VERSION "HIPBNNNYNNNNNNNNNNNNNNNNNNNNNNNNNNYYNNNNNN/4>%%%/4/'%**4NNN///"

NS_ :

BS_:

BU_: ADC BDF BDL BDR BGW CDC DDM VNC Vector_XXX

BO_ 1570 BDB1S03: 8 BDL
 SG_ RSRSENFT : 23|2@0+ (1,0) [0|0] "-"  BGW,CDC,DDM
 SG_ SULDCD : 21|2@0+ (1,0) [0|0] "-"  BGW,CDC,DDM
 SG_ PANL : 19|1@0+ (1,0) [0|0] "-"  BGW,CDC
 SG_ LED_HI_B : 17|2@0+ (1,0) [0|0] "-"  BGW,CDC,DDM
 SG_ DRL : 31|1@0+ (1,0) [0|0] "-"  BGW,CDC,DDM
 SG_ HEDH : 30|1@0+ (1,0) [0|0] "-"  BGW,CDC,DDM
 SG_ HEDL : 29|1@0+ (1,0) [0|0] "-"  BGW,CDC,DDM
 SG_ TAIL : 28|1@0+ (1,0) [0|0] "-"  BGW,CDC
 SG_ FFOG : 27|1@0+ (1,0) [0|0] "-"  BGW,CDC,DDM
 SG_ RFOG : 26|1@0+ (1,0) [0|0] "-"  BGW,CDC,DDM
 SG_ RSROFFTT : 25|2@0+ (1,0) [0|0] "-"  BGW,CDC,DDM
 SG_ SB_IND : 39|2@0+ (1,0) [0|0] "-"  BGW,CDC,DDM
 SG_ RSRMIDR3 : 33|2@0+ (1,0) [0|0] "-"  BGW,CDC,DDM
 SG_ RSRMID_R : 47|2@0+ (1,0) [0|0] "-"  BGW,CDC,DDM
 SG_ RSR_PR : 45|1@0+ (1,0) [0|0] "-"  BGW,CDC,DDM
 SG_ RSRON_ST : 44|1@0+ (1,0) [0|0] "-"  BGW,CDC,DDM
 SG_ LTOFF_AD : 54|1@0+ (1,0) [0|0] "-"  BGW,CDC,DDM
 SG_ RSRSENFC : 53|2@0+ (1,0) [0|0] "-"  BGW,CDC,DDM
 SG_ SRWARN : 51|1@0+ (1,0) [0|0] "-"  BGW,CDC,DDM
 SG_ PWWARN : 50|1@0+ (1,0) [0|0] "-"  BGW,CDC,DDM
 SG_ LTRBZ_R : 49|1@0+ (1,0) [0|0] "-"  BGW,CDC,DDM

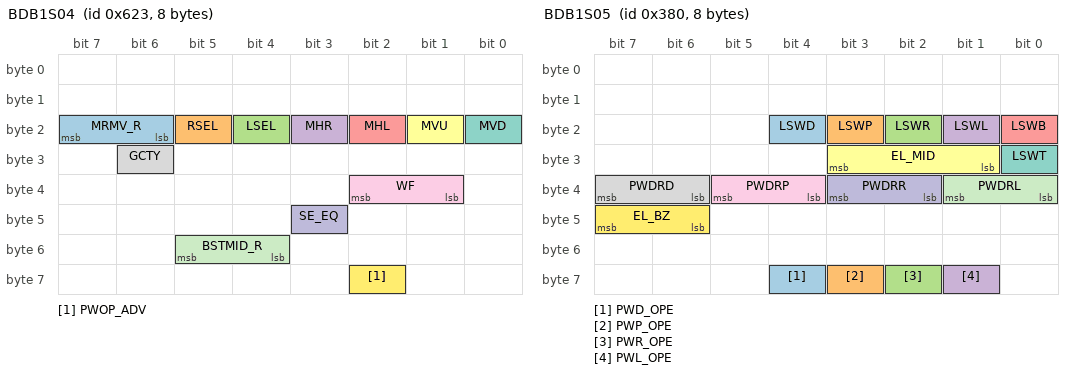
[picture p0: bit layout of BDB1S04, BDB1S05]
BO_ 1571 BDB1S04: 8 BDL
 SG_ MRMV_R : 23|2@0+ (1,0) [0|0] "-"  BGW,CDC,DDM
 SG_ RSEL : 21|1@0+ (1,0) [0|0] "-"  BGW,CDC,DDM
 SG_ LSEL : 20|1@0+ (1,0) [0|0] "-"  BGW,CDC,DDM
 SG_ MHR : 19|1@0+ (1,0) [0|0] "-"  BGW,CDC,DDM
 SG_ MHL : 18|1@0+ (1,0) [0|0] "-"  BGW,CDC,DDM
 SG_ MVU : 17|1@0+ (1,0) [0|0] "-"  BGW,CDC,DDM
 SG_ MVD : 16|1@0+ (1,0) [0|0] "-"  BGW,CDC,DDM
 SG_ GCTY : 30|1@0+ (1,0) [0|0] "-"  BGW,CDC,DDM
 SG_ WF : 34|2@0+ (1,0) [0|0] "-"  BGW,CDC,DDM
 SG_ SE_EQ : 43|1@0+ (1,0) [0|0] "-"  BGW,CDC,DDM
 SG_ BSTMID_R : 53|2@0+ (1,0) [0|0] "-"  BGW,CDC,DDM
 SG_ PWOP_ADV : 58|1@0+ (1,0) [0|0] "-"  BGW,CDC,DDM

BO_ 896 BDB1S05: 8 BDL
 SG_ LSWD : 20|1@0+ (1,0) [0|0] "-"  BGW,CDC
 SG_ LSWP : 19|1@0+ (1,0) [0|0] "-"  BGW,CDC
 SG_ LSWR : 18|1@0+ (1,0) [0|0] "-"  BGW,CDC
 SG_ LSWL : 17|1@0+ (1,0) [0|0] "-"  BGW,CDC
 SG_ LSWB : 16|1@0+ (1,0) [0|0] "-"  BGW,CDC
 SG_ EL_MID : 27|3@0+ (1,0) [0|0] "-"  BGW,CDC
 SG_ LSWT : 24|1@0+ (1,0) [0|0] "-"  BGW,CDC
 SG_ PWDRD : 39|2@0+ (1,0) [0|0] "-"  BGW,CDC
 SG_ PWDRP : 37|2@0+ (1,0) [0|0] "-"  BGW,CDC
 SG_ PWDRR : 35|2@0+ (1,0) [0|0] "-"  BGW,CDC
 SG_ PWDRL : 33|2@0+ (1,0) [0|0] "-"  BGW,CDC
 SG_ EL_BZ : 47|2@0+ (1,0) [0|0] "-"  BGW,CDC
 SG_ PWD_OPE : 60|1@0+ (1,0) [0|0] "-"  BGW,CDC
 SG_ PWP_OPE : 59|1@0+ (1,0) [0|0] "-"  BGW,CDC
 SG_ PWR_OPE : 58|1@0+ (1,0) [0|0] "-"  BGW,CDC
 SG_ PWL_OPE : 57|1@0+ (1,0) [0|0] "-"  BGW,CDC

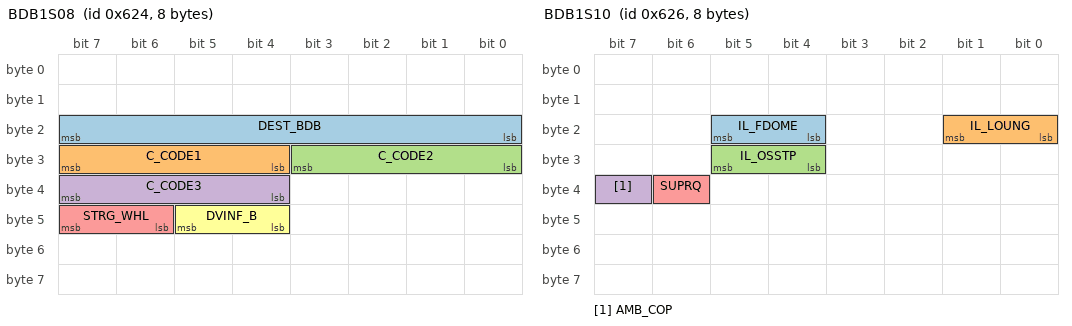
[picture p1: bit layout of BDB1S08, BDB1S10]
BO_ 1572 BDB1S08: 8 BDL
 SG_ DEST_BDB : 23|8@0+ (1,0) [0|0] "-"  BGW,CDC
 SG_ C_CODE1 : 31|4@0+ (1,0) [0|0] "-"  BGW,CDC
 SG_ C_CODE2 : 27|4@0+ (1,0) [0|0] "-"  BGW,CDC
 SG_ C_CODE3 : 39|4@0+ (1,0) [0|0] "-"  BGW,CDC
 SG_ STRG_WHL : 47|2@0+ (1,0) [0|0] "-"  BGW,CDC
 SG_ DVINF_B : 45|2@0+ (1,0) [0|0] "-"  BGW,CDC

BO_ 1574 BDB1S10: 8 BDL
 SG_ IL_FDOME : 21|2@0+ (1,0) [0|0] "-"  CDC
 SG_ IL_LOUNG : 17|2@0+ (1,0) [0|0] "-"  CDC
 SG_ IL_OSSTP : 29|2@0+ (1,0) [0|0] "-"  CDC
 SG_ AMB_COP : 39|1@0+ (1,0) [0|0] "-"  CDC
 SG_ SUPRQ : 38|1@0+ (1,0) [0|0] "-"  CDC

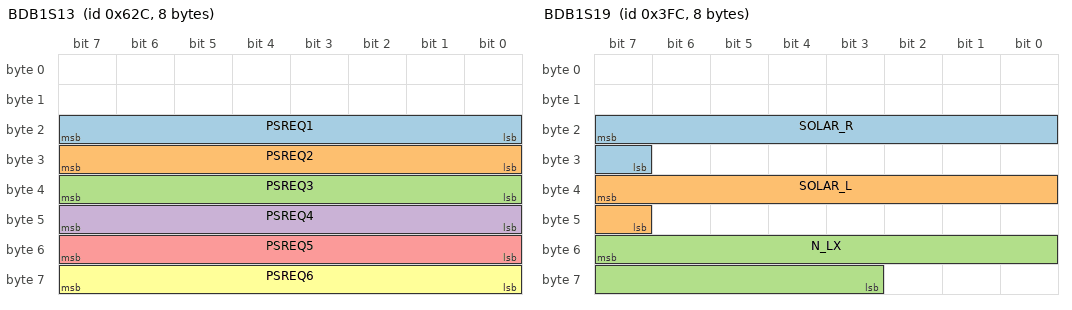
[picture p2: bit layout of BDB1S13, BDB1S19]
BO_ 1580 BDB1S13: 8 BDL
 SG_ PSREQ1 : 23|8@0+ (1,0) [0|0] "-"  CDC
 SG_ PSREQ2 : 31|8@0+ (1,0) [0|0] "-"  CDC
 SG_ PSREQ3 : 39|8@0+ (1,0) [0|0] "-"  CDC
 SG_ PSREQ4 : 47|8@0+ (1,0) [0|0] "-"  CDC
 SG_ PSREQ5 : 55|8@0+ (1,0) [0|0] "-"  CDC
 SG_ PSREQ6 : 63|8@0+ (1,0) [0|0] "-"  CDC

BO_ 1020 BDB1S19: 8 BDL
 SG_ SOLAR_R : 23|9@0+ (100,0) [0|0] "-"  BGW,CDC
 SG_ SOLAR_L : 39|9@0+ (100,0) [0|0] "-"  BGW,CDC
 SG_ N_LX : 55|13@0+ (1,0) [0|0] "-"  BGW,CDC

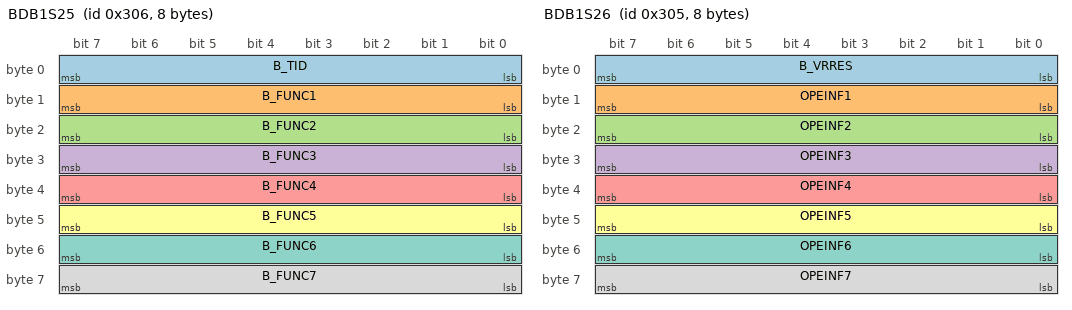
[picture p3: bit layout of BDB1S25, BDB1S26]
BO_ 774 BDB1S25: 8 BDL
 SG_ B_TID : 7|8@0+ (1,0) [0|0] "-"  CDC
 SG_ B_FUNC1 : 15|8@0+ (1,0) [0|0] "-"  CDC
 SG_ B_FUNC2 : 23|8@0+ (1,0) [0|0] "-"  CDC
 SG_ B_FUNC3 : 31|8@0+ (1,0) [0|0] "-"  CDC
 SG_ B_FUNC4 : 39|8@0+ (1,0) [0|0] "-"  CDC
 SG_ B_FUNC5 : 47|8@0+ (1,0) [0|0] "-"  CDC
 SG_ B_FUNC6 : 55|8@0+ (1,0) [0|0] "-"  CDC
 SG_ B_FUNC7 : 63|8@0+ (1,0) [0|0] "-"  CDC

BO_ 773 BDB1S26: 8 BDL
 SG_ B_VRRES : 7|8@0+ (1,0) [0|0] "-"  CDC
 SG_ OPEINF1 : 15|8@0+ (1,0) [0|0] "-"  CDC
 SG_ OPEINF2 : 23|8@0+ (1,0) [0|0] "-"  CDC
 SG_ OPEINF3 : 31|8@0+ (1,0) [0|0] "-"  CDC
 SG_ OPEINF4 : 39|8@0+ (1,0) [0|0] "-"  CDC
 SG_ OPEINF5 : 47|8@0+ (1,0) [0|0] "-"  CDC
 SG_ OPEINF6 : 55|8@0+ (1,0) [0|0] "-"  CDC
 SG_ OPEINF7 : 63|8@0+ (1,0) [0|0] "-"  CDC

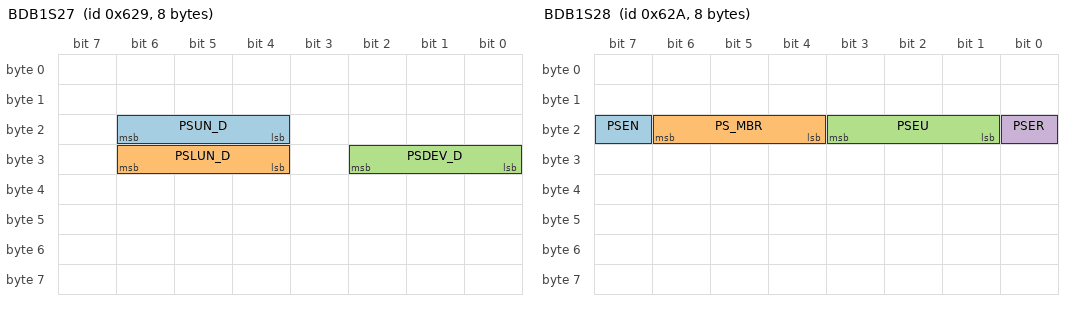
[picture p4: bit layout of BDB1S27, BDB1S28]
BO_ 1577 BDB1S27: 8 BDL
 SG_ PSUN_D : 22|3@0+ (1,0) [0|0] "-"  CDC
 SG_ PSLUN_D : 30|3@0+ (1,0) [0|0] "-"  CDC
 SG_ PSDEV_D : 26|3@0+ (1,0) [0|0] "-"  CDC

BO_ 1578 BDB1S28: 8 BDL
 SG_ PSEN : 23|1@0+ (1,0) [0|0] "-"  CDC
 SG_ PS_MBR : 22|3@0+ (1,0) [0|0] "-"  CDC
 SG_ PSEU : 19|3@0+ (1,0) [0|0] "-"  CDC
 SG_ PSER : 16|1@0+ (1,0) [0|0] "-"  CDC

BO_ 919 BDB1S29: 32 BDL
 SG_ WS_NUM : 23|8@0+ (1,0) [0|0] "-"  CDC
 SG_ WS_DRVR : 31|3@0+ (1,0) [0|0] "-"  CDC
 SG_ WS_NEXTD : 26|3@0+ (1,0) [0|0] "-"  CDC
 SG_ WS_MSG : 39|4@0+ (1,0) [0|0] "-"  CDC
 SG_ DP_ST : 55|1@0+ (1,0) [0|0] "-"  CDC
 SG_ NDRV_DET : 54|1@0+ (1,0) [0|0] "-"  CDC
 SG_ REQ_DPSC : 53|1@0+ (1,0) [0|0] "-"  CDC
 SG_ PS_NUM : 52|8@0+ (1,0) [0|0] "-"  CDC
 SG_ PS_DRVR : 60|3@0+ (1,0) [0|0] "-"  CDC
 SG_ PS_GO_DS : 57|1@0+ (1,0) [0|0] "-"  CDC
 SG_ PS_GO_PD : 56|1@0+ (1,0) [0|0] "-"  CDC
 SG_ PS_GO_FR : 71|1@0+ (1,0) [0|0] "-"  CDC
 SG_ PS_OD : 70|3@0+ (1,0) [0|0] "-"  CDC
 SG_ PS_GO_KA : 67|1@0+ (1,0) [0|0] "-"  CDC
 SG_ PS_FRR : 66|1@0+ (1,0) [0|0] "-"  CDC
 SG_ DKY_EXST : 65|1@0+ (1,0) [0|0] "-"  CDC
 SG_ PS_N_KEY : 64|3@0+ (1,0) [0|0] "-"  CDC
 SG_ PS_FRMEM : 77|1@0+ (1,0) [0|0] "-"  CDC
 SG_ RESEXERS : 76|3@0+ (1,0) [0|0] "-"  CDC
 SG_ DIDEXERS : 73|3@0+ (1,0) [0|0] "-"  CDC
 SG_ PS_DKLNK : 86|1@0+ (1,0) [0|0] "-"  CDC
 SG_ PS_PDHR : 85|1@0+ (1,0) [0|0] "-"  CDC
 SG_ FRTIME : 84|4@0+ (1,0) [0|0] "-"  CDC

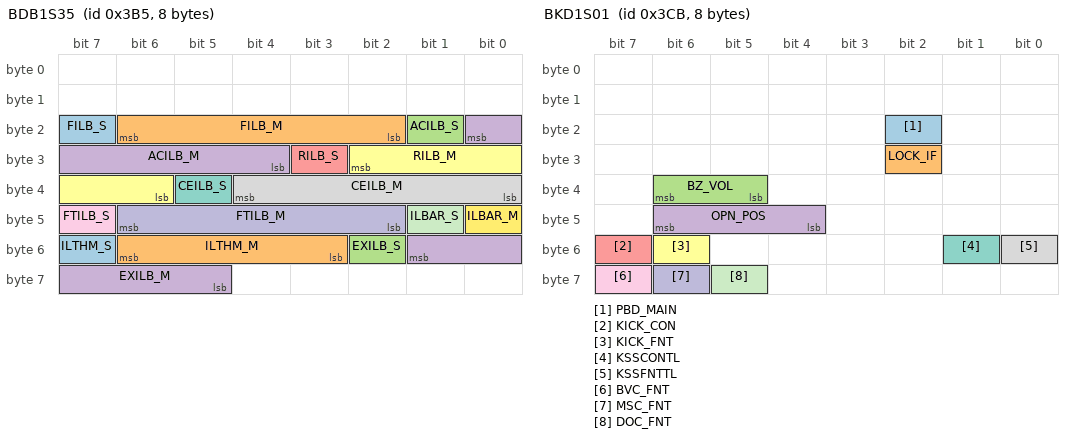
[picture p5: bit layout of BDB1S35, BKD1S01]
BO_ 949 BDB1S35: 8 BDL
 SG_ FILB_S : 23|1@0+ (1,0) [0|0] "-"  CDC
 SG_ FILB_M : 22|5@0+ (1,0) [0|0] "-"  CDC
 SG_ ACILB_S : 17|1@0+ (1,0) [0|0] "-"  CDC
 SG_ ACILB_M : 16|5@0+ (1,0) [0|0] "-"  CDC
 SG_ RILB_S : 27|1@0+ (1,0) [0|0] "-"  CDC
 SG_ RILB_M : 26|5@0+ (1,0) [0|0] "-"  CDC
 SG_ CEILB_S : 37|1@0+ (1,0) [0|0] "-"  CDC
 SG_ CEILB_M : 36|5@0+ (1,0) [0|0] "-"  CDC
 SG_ FTILB_S : 47|1@0+ (1,0) [0|0] "-"  CDC
 SG_ FTILB_M : 46|5@0+ (1,0) [0|0] "-"  CDC
 SG_ ILBAR_S : 41|1@0+ (1,0) [0|0] "-"  CDC
 SG_ ILBAR_M : 40|1@0+ (1,0) [0|0] "-"  CDC
 SG_ ILTHM_S : 55|1@0+ (1,0) [0|0] "-"  CDC
 SG_ ILTHM_M : 54|4@0+ (1,0) [0|0] "-"  CDC
 SG_ EXILB_S : 50|1@0+ (1,0) [0|0] "-"  CDC
 SG_ EXILB_M : 49|5@0+ (1,0) [0|0] "-"  CDC

BO_ 952 BDB1S36: 8 BDL
 SG_ ILCUSA_S : 23|1@0+ (1,0) [0|0] "-"  CDC
 SG_ ILCUSA_M : 22|7@0+ (1,0) [0|0] "-"  CDC
 SG_ WELIL_S : 31|1@0+ (1,0) [0|0] "-"  CDC
 SG_ WELIL_M : 30|1@0+ (1,0) [0|0] "-"  CDC
 SG_ DRIIL_S : 27|1@0+ (1,0) [0|0] "-"  CDC
 SG_ DRIIL_M : 26|1@0+ (1,0) [0|0] "-"  CDC
 SG_ ACIL_S : 25|1@0+ (1,0) [0|0] "-"  CDC
 SG_ ACIL_M : 24|1@0+ (1,0) [0|0] "-"  CDC
 SG_ TIMEIL_S : 39|1@0+ (1,0) [0|0] "-"  CDC
 SG_ TIMEIL_M : 38|1@0+ (1,0) [0|0] "-"  CDC
 SG_ ILMAIN_S : 37|1@0+ (1,0) [0|0] "-"  CDC
 SG_ ILMAIN_M : 36|1@0+ (1,0) [0|0] "-"  CDC
 SG_ FNIL_S : 35|1@0+ (1,0) [0|0] "-"  CDC
 SG_ FNIL_M : 34|1@0+ (1,0) [0|0] "-"  CDC
 SG_ SEAIL_S : 33|1@0+ (1,0) [0|0] "-"  CDC
 SG_ SEAIL_M : 32|1@0+ (1,0) [0|0] "-"  CDC
 SG_ ILLON_NO : 45|6@0+ (1,0) [0|0] "-"  CDC
 SG_ ILLON_F : 50|3@0+ (1,0) [0|0] "-"  CDC

BO_ 786 BDC1S13: 32 BDL
 SG_ ODO_BECU : 7|32@0+ (0.1,0) [0|0] "km"  CDC
 SG_ FV312 : 175|56@0+ (1,0) [0|0] "-"  CDC
 SG_ KZK312 : 231|32@0+ (1,0) [0|0] "-"  CDC

BO_ 800 BDC1S14: 32 BDL
 SG_ B_RACRES : 7|8@0+ (1,0) [0|0] "-"  BGW,CDC
 SG_ B_RACTRG : 15|1@0+ (1,0) [0|0] "-"  BGW,CDC
 SG_ B_RACEQP : 14|1@0+ (1,0) [0|0] "-"  BGW,CDC
 SG_ B_DPADD : 13|1@0+ (1,0) [0|0] "-"  BGW,CDC
 SG_ B_DPACTM : 11|3@0+ (1,0) [0|0] "-"  BGW,CDC
 SG_ B_DPACMD : 8|1@0+ (1,0) [0|0] "-"  BGW,CDC
 SG_ B_DPTMP : 23|8@0+ (1,0) [0|0] "-"  BGW,CDC
 SG_ B_DPREFR : 31|2@0+ (1,0) [0|0] "-"  BGW,CDC
 SG_ B_DPBLLV : 29|4@0+ (1,0) [0|0] "-"  BGW,CDC
 SG_ B_DPFDEF : 25|2@0+ (1,0) [0|0] "-"  BGW,CDC
 SG_ B_DPRDEF : 39|2@0+ (1,0) [0|0] "-"  BGW,CDC
 SG_ B_DPSH : 37|2@0+ (1,0) [0|0] "-"  BGW,CDC
 SG_ B_DPFDHV : 35|2@0+ (1,0) [0|0] "-"  BGW,CDC
 SG_ B_DPFPHV : 33|2@0+ (1,0) [0|0] "-"  BGW,CDC
 SG_ B_DPRDHV : 47|2@0+ (1,0) [0|0] "-"  BGW,CDC
 SG_ B_DPRPHV : 45|2@0+ (1,0) [0|0] "-"  BGW,CDC
 SG_ B_DPFGON : 43|2@0+ (1,0) [0|0] "-"  BGW,CDC
 SG_ B_DPFGCH : 41|2@0+ (1,0) [0|0] "-"  BGW,CDC
 SG_ B_DPFGLV : 55|3@0+ (1,0) [0|0] "-"  BGW,CDC

BO_ 810 BDC1S16: 32 BDL
 SG_ B_DPID1 : 7|3@0+ (1,0) [0|0] "-"  BGW,CDC
 SG_ B_DPON1 : 4|1@0+ (1,0) [0|0] "-"  BGW,CDC
 SG_ B_DPTYP1 : 3|1@0+ (1,0) [0|0] "-"  BGW,CDC
 SG_ B_DPDAY1 : 2|7@0+ (1,0) [0|0] "-"  BGW,CDC
 SG_ B_DPMON1 : 11|4@0+ (1,0) [0|0] "-"  BGW,CDC
 SG_ B_DPDAT1 : 23|5@0+ (1,0) [0|0] "-"  BGW,CDC
 SG_ B_DPDTM1 : 18|9@0+ (1,0) [0|0] "-"  BGW,CDC
 SG_ B_DPAC1 : 25|1@0+ (1,0) [0|0] "-"  BGW,CDC
 SG_ B_DPBC1 : 24|1@0+ (1,0) [0|0] "-"  BGW,CDC
 SG_ B_DPID2 : 39|3@0+ (1,0) [0|0] "-"  BGW,CDC
 SG_ B_DPON2 : 36|1@0+ (1,0) [0|0] "-"  BGW,CDC
 SG_ B_DPTYP2 : 35|1@0+ (1,0) [0|0] "-"  BGW,CDC
 SG_ B_DPDAY2 : 34|7@0+ (1,0) [0|0] "-"  BGW,CDC
 SG_ B_DPMON2 : 43|4@0+ (1,0) [0|0] "-"  BGW,CDC
 SG_ B_DPDAT2 : 55|5@0+ (1,0) [0|0] "-"  BGW,CDC
 SG_ B_DPDTM2 : 50|9@0+ (1,0) [0|0] "-"  BGW,CDC
 SG_ B_DPAC2 : 57|1@0+ (1,0) [0|0] "-"  BGW,CDC
 SG_ B_DPBC2 : 56|1@0+ (1,0) [0|0] "-"  BGW,CDC
 SG_ B_DPID3 : 71|3@0+ (1,0) [0|0] "-"  BGW,CDC
 SG_ B_DPON3 : 68|1@0+ (1,0) [0|0] "-"  BGW,CDC
 SG_ B_DPTYP3 : 67|1@0+ (1,0) [0|0] "-"  BGW,CDC
 SG_ B_DPDAY3 : 66|7@0+ (1,0) [0|0] "-"  BGW,CDC
 SG_ B_DPMON3 : 75|4@0+ (1,0) [0|0] "-"  BGW,CDC
 SG_ B_DPDAT3 : 87|5@0+ (1,0) [0|0] "-"  BGW,CDC
 SG_ B_DPDTM3 : 82|9@0+ (1,0) [0|0] "-"  BGW,CDC
 SG_ B_DPAC3 : 89|1@0+ (1,0) [0|0] "-"  BGW,CDC
 SG_ B_DPBC3 : 88|1@0+ (1,0) [0|0] "-"  BGW,CDC
 SG_ B_DPID4 : 103|3@0+ (1,0) [0|0] "-"  BGW,CDC
 SG_ B_DPON4 : 100|1@0+ (1,0) [0|0] "-"  BGW,CDC
 SG_ B_DPTYP4 : 99|1@0+ (1,0) [0|0] "-"  BGW,CDC
 SG_ B_DPDAY4 : 98|7@0+ (1,0) [0|0] "-"  BGW,CDC
 SG_ B_DPMON4 : 107|4@0+ (1,0) [0|0] "-"  BGW,CDC
 SG_ B_DPDAT4 : 119|5@0+ (1,0) [0|0] "-"  BGW,CDC
 SG_ B_DPDTM4 : 114|9@0+ (1,0) [0|0] "-"  BGW,CDC
 SG_ B_DPAC4 : 121|1@0+ (1,0) [0|0] "-"  BGW,CDC
 SG_ B_DPBC4 : 120|1@0+ (1,0) [0|0] "-"  BGW,CDC
 SG_ B_DPID5 : 135|3@0+ (1,0) [0|0] "-"  BGW,CDC
 SG_ B_DPON5 : 132|1@0+ (1,0) [0|0] "-"  BGW,CDC
 SG_ B_DPTYP5 : 131|1@0+ (1,0) [0|0] "-"  BGW,CDC
 SG_ B_DPDAY5 : 130|7@0+ (1,0) [0|0] "-"  BGW,CDC
 SG_ B_DPMON5 : 139|4@0+ (1,0) [0|0] "-"  BGW,CDC
 SG_ B_DPDAT5 : 151|5@0+ (1,0) [0|0] "-"  BGW,CDC
 SG_ B_DPDTM5 : 146|9@0+ (1,0) [0|0] "-"  BGW,CDC
 SG_ B_DPAC5 : 153|1@0+ (1,0) [0|0] "-"  BGW,CDC
 SG_ B_DPBC5 : 152|1@0+ (1,0) [0|0] "-"  BGW,CDC
 SG_ B_DPID6 : 167|3@0+ (1,0) [0|0] "-"  BGW,CDC
 SG_ B_DPON6 : 164|1@0+ (1,0) [0|0] "-"  BGW,CDC
 SG_ B_DPTYP6 : 163|1@0+ (1,0) [0|0] "-"  BGW,CDC
 SG_ B_DPDAY6 : 162|7@0+ (1,0) [0|0] "-"  BGW,CDC
 SG_ B_DPMON6 : 171|4@0+ (1,0) [0|0] "-"  BGW,CDC
 SG_ B_DPDAT6 : 183|5@0+ (1,0) [0|0] "-"  BGW,CDC
 SG_ B_DPDTM6 : 178|9@0+ (1,0) [0|0] "-"  BGW,CDC
 SG_ B_DPAC6 : 185|1@0+ (1,0) [0|0] "-"  BGW,CDC
 SG_ B_DPBC6 : 184|1@0+ (1,0) [0|0] "-"  BGW,CDC
 SG_ B_DPID7 : 199|3@0+ (1,0) [0|0] "-"  BGW,CDC
 SG_ B_DPON7 : 196|1@0+ (1,0) [0|0] "-"  BGW,CDC
 SG_ B_DPTYP7 : 195|1@0+ (1,0) [0|0] "-"  BGW,CDC
 SG_ B_DPDAY7 : 194|7@0+ (1,0) [0|0] "-"  BGW,CDC
 SG_ B_DPMON7 : 203|4@0+ (1,0) [0|0] "-"  BGW,CDC
 SG_ B_DPDAT7 : 215|5@0+ (1,0) [0|0] "-"  BGW,CDC
 SG_ B_DPDTM7 : 210|9@0+ (1,0) [0|0] "-"  BGW,CDC
 SG_ B_DPAC7 : 217|1@0+ (1,0) [0|0] "-"  BGW,CDC
 SG_ B_DPBC7 : 216|1@0+ (1,0) [0|0] "-"  BGW,CDC
 SG_ B_DPTYPN : 231|1@0+ (1,0) [0|0] "-"  BGW,CDC
 SG_ B_DPDAYN : 230|3@0+ (1,0) [0|0] "-"  BGW,CDC
 SG_ B_DPMONN : 227|4@0+ (1,0) [0|0] "-"  BGW,CDC
 SG_ B_DPDATN : 239|5@0+ (1,0) [0|0] "-"  BGW,CDC
 SG_ B_DPDTMN : 234|9@0+ (1,0) [0|0] "-"  BGW,CDC
 SG_ B_DPACN : 241|1@0+ (1,0) [0|0] "-"  BGW,CDC
 SG_ B_DPBCN : 240|1@0+ (1,0) [0|0] "-"  BGW,CDC
 SG_ B_DPACTO : 255|2@0+ (1,0) [0|0] "-"  BGW,CDC

BO_ 892 BDC1S22: 8 BDL
 SG_ THEFTD1 : 7|2@0+ (1,0) [0|0] "-"  BGW,CDC
 SG_ THEFTD2 : 5|12@0+ (1,0) [0|0] "-"  BGW,CDC

BO_ 320 BDC1S23: 8 BDL
 SG_ MTNLS_L : 7|1@0+ (1,0) [0|0] "-"  CDC
 SG_ MTNLS_R : 6|1@0+ (1,0) [0|0] "-"  CDC

BO_ 390 BDC1S30: 32 BDR
 SG_ DSADSTX : 7|8@0+ (1,0) [0|0] "-"  CDC
 SG_ DSADSTY : 15|8@0+ (1,0) [0|0] "-"  CDC
 SG_ DSADFNX : 19|1@0+ (1,0) [0|0] "-"  CDC
 SG_ DSADFNY : 18|1@0+ (1,0) [0|0] "-"  CDC
 SG_ DSADOPX : 17|1@0+ (1,0) [0|0] "-"  CDC
 SG_ DSADOPY : 16|1@0+ (1,0) [0|0] "-"  CDC
 SG_ DSSHTST : 31|1@0+ (1,0) [0|0] "-"  CDC
 SG_ DSSHTFN : 30|1@0+ (1,0) [0|0] "-"  CDC
 SG_ DSSHTOP : 29|1@0+ (1,0) [0|0] "-"  CDC
 SG_ DSSWGST : 28|1@0+ (1,0) [0|0] "-"  CDC
 SG_ DSSWGFN : 27|1@0+ (1,0) [0|0] "-"  CDC
 SG_ DSSWGOP : 26|1@0+ (1,0) [0|0] "-"  CDC
 SG_ DSARFST : 25|2@0+ (1,0) [0|0] "-"  CDC
 SG_ DCADSTX : 39|8@0+ (1,0) [0|0] "-"  CDC
 SG_ DCADSTY : 47|8@0+ (1,0) [0|0] "-"  CDC
 SG_ DCADFNX : 51|1@0+ (1,0) [0|0] "-"  CDC
 SG_ DCADFNY : 50|1@0+ (1,0) [0|0] "-"  CDC
 SG_ DCADOPX : 49|1@0+ (1,0) [0|0] "-"  CDC
 SG_ DCADOPY : 48|1@0+ (1,0) [0|0] "-"  CDC
 SG_ DCSHTST : 63|1@0+ (1,0) [0|0] "-"  CDC
 SG_ DCSHTFN : 62|1@0+ (1,0) [0|0] "-"  CDC
 SG_ DCSHTOP : 61|1@0+ (1,0) [0|0] "-"  CDC
 SG_ DCSWGST : 60|1@0+ (1,0) [0|0] "-"  CDC
 SG_ DCSWGFN : 59|1@0+ (1,0) [0|0] "-"  CDC
 SG_ DCSWGOP : 58|1@0+ (1,0) [0|0] "-"  CDC
 SG_ DCARFST : 57|2@0+ (1,0) [0|0] "-"  CDC
 SG_ PSADSTX : 71|8@0+ (1,0) [0|0] "-"  CDC
 SG_ PSADSTY : 79|8@0+ (1,0) [0|0] "-"  CDC
 SG_ PSADFNX : 83|1@0+ (1,0) [0|0] "-"  CDC
 SG_ PSADFNY : 82|1@0+ (1,0) [0|0] "-"  CDC
 SG_ PSADOPX : 81|1@0+ (1,0) [0|0] "-"  CDC
 SG_ PSADOPY : 80|1@0+ (1,0) [0|0] "-"  CDC
 SG_ PSSHTST : 95|1@0+ (1,0) [0|0] "-"  CDC
 SG_ PSSHTFN : 94|1@0+ (1,0) [0|0] "-"  CDC
 SG_ PSSHTOP : 93|1@0+ (1,0) [0|0] "-"  CDC
 SG_ PSSWGST : 92|1@0+ (1,0) [0|0] "-"  CDC
 SG_ PSSWGFN : 91|1@0+ (1,0) [0|0] "-"  CDC
 SG_ PSSWGOP : 90|1@0+ (1,0) [0|0] "-"  CDC
 SG_ PSARFST : 89|2@0+ (1,0) [0|0] "-"  CDC
 SG_ PCADSTX : 103|8@0+ (1,0) [0|0] "-"  CDC
 SG_ PCADSTY : 111|8@0+ (1,0) [0|0] "-"  CDC
 SG_ PCADFNX : 115|1@0+ (1,0) [0|0] "-"  CDC
 SG_ PCADFNY : 114|1@0+ (1,0) [0|0] "-"  CDC
 SG_ PCADOPX : 113|1@0+ (1,0) [0|0] "-"  CDC
 SG_ PCADOPY : 112|1@0+ (1,0) [0|0] "-"  CDC
 SG_ PCSHTST : 127|1@0+ (1,0) [0|0] "-"  CDC
 SG_ PCSHTFN : 126|1@0+ (1,0) [0|0] "-"  CDC
 SG_ PCSHTOP : 125|1@0+ (1,0) [0|0] "-"  CDC
 SG_ PCSWGST : 124|1@0+ (1,0) [0|0] "-"  CDC
 SG_ PCSWGFN : 123|1@0+ (1,0) [0|0] "-"  CDC
 SG_ PCSWGOP : 122|1@0+ (1,0) [0|0] "-"  CDC
 SG_ PCARFST : 121|2@0+ (1,0) [0|0] "-"  CDC
 SG_ RRCADSTX : 135|8@0+ (1,0) [0|0] "-"  CDC
 SG_ RRCADSTY : 143|8@0+ (1,0) [0|0] "-"  CDC
 SG_ RRCADFNX : 147|1@0+ (1,0) [0|0] "-"  CDC
 SG_ RRCADFNY : 146|1@0+ (1,0) [0|0] "-"  CDC
 SG_ RRCADOPX : 145|1@0+ (1,0) [0|0] "-"  CDC
 SG_ RRCADOPY : 144|1@0+ (1,0) [0|0] "-"  CDC
 SG_ RRCSHTST : 159|1@0+ (1,0) [0|0] "-"  CDC
 SG_ RRCSHTFN : 158|1@0+ (1,0) [0|0] "-"  CDC
 SG_ RRCSHTOP : 157|1@0+ (1,0) [0|0] "-"  CDC
 SG_ RRCSWGST : 156|1@0+ (1,0) [0|0] "-"  CDC
 SG_ RRCSWGFN : 155|1@0+ (1,0) [0|0] "-"  CDC
 SG_ RRCSWGOP : 154|1@0+ (1,0) [0|0] "-"  CDC
 SG_ RRCARFST : 153|2@0+ (1,0) [0|0] "-"  CDC
 SG_ RLCADSTX : 167|8@0+ (1,0) [0|0] "-"  CDC
 SG_ RLCADSTY : 175|8@0+ (1,0) [0|0] "-"  CDC
 SG_ RLCADFNX : 179|1@0+ (1,0) [0|0] "-"  CDC
 SG_ RLCADFNY : 178|1@0+ (1,0) [0|0] "-"  CDC
 SG_ RLCADOPX : 177|1@0+ (1,0) [0|0] "-"  CDC
 SG_ RLCADOPY : 176|1@0+ (1,0) [0|0] "-"  CDC
 SG_ RLCSHTST : 191|1@0+ (1,0) [0|0] "-"  CDC
 SG_ RLCSHTFN : 190|1@0+ (1,0) [0|0] "-"  CDC
 SG_ RLCSHTOP : 189|1@0+ (1,0) [0|0] "-"  CDC
 SG_ RLCSWGST : 188|1@0+ (1,0) [0|0] "-"  CDC
 SG_ RLCSWGFN : 187|1@0+ (1,0) [0|0] "-"  CDC
 SG_ RLCSWGOP : 186|1@0+ (1,0) [0|0] "-"  CDC
 SG_ RLCARFST : 185|2@0+ (1,0) [0|0] "-"  CDC
 SG_ SWNSWFNP : 199|1@0+ (1,0) [0|0] "-"  CDC
 SG_ SWNSWOPP : 198|1@0+ (1,0) [0|0] "-"  CDC
 SG_ SWNSWSTP : 197|2@0+ (1,0) [0|0] "-"  CDC
 SG_ SWNSWFND : 195|1@0+ (1,0) [0|0] "-"  CDC
 SG_ SWNSWOPD : 194|1@0+ (1,0) [0|0] "-"  CDC
 SG_ SWNSWSTD : 193|2@0+ (1,0) [0|0] "-"  CDC
 SG_ BLMDCMFN : 202|1@0+ (1,0) [0|0] "-"  CDC
 SG_ BLMDCMOP : 201|1@0+ (1,0) [0|0] "-"  CDC
 SG_ BLMDCMST : 200|1@0+ (1,0) [0|0] "-"  CDC
 SG_ DSPADFN : 215|1@0+ (1,0) [0|0] "-"  CDC
 SG_ DSPADOP : 214|1@0+ (1,0) [0|0] "-"  CDC
 SG_ DCPADFN : 213|1@0+ (1,0) [0|0] "-"  CDC
 SG_ DCPADOP : 212|1@0+ (1,0) [0|0] "-"  CDC
 SG_ PSPADFN : 211|1@0+ (1,0) [0|0] "-"  CDC
 SG_ PSPADOP : 210|1@0+ (1,0) [0|0] "-"  CDC
 SG_ PCPADFN : 209|1@0+ (1,0) [0|0] "-"  CDC
 SG_ PCPADOP : 208|1@0+ (1,0) [0|0] "-"  CDC
 SG_ RRCPADFN : 219|1@0+ (1,0) [0|0] "-"  CDC
 SG_ RRCPADOP : 218|1@0+ (1,0) [0|0] "-"  CDC
 SG_ RLCPADFN : 217|1@0+ (1,0) [0|0] "-"  CDC
 SG_ RLCPADOP : 216|1@0+ (1,0) [0|0] "-"  CDC
 SG_ SPTSWFNP : 231|1@0+ (1,0) [0|0] "-"  CDC
 SG_ SPTSWOPP : 230|1@0+ (1,0) [0|0] "-"  CDC
 SG_ SPTSWSTP : 228|1@0+ (1,0) [0|0] "-"  CDC
 SG_ SPTSWFND : 227|1@0+ (1,0) [0|0] "-"  CDC
 SG_ SPTSWOPD : 226|1@0+ (1,0) [0|0] "-"  CDC
 SG_ SPTSWSTD : 224|1@0+ (1,0) [0|0] "-"  CDC
 SG_ SPRSWFNP : 239|1@0+ (1,0) [0|0] "-"  CDC
 SG_ SPRSWOPP : 238|1@0+ (1,0) [0|0] "-"  CDC
 SG_ SPRSWSTP : 236|1@0+ (1,0) [0|0] "-"  CDC
 SG_ SPRSWFND : 235|1@0+ (1,0) [0|0] "-"  CDC
 SG_ SPRSWOPD : 234|1@0+ (1,0) [0|0] "-"  CDC
 SG_ SPRSWSTD : 232|1@0+ (1,0) [0|0] "-"  CDC

BO_ 466 BDC1S33: 8 BDF
 SG_ TVPSOFF : 9|1@0+ (1,0) [0|0] "-"  BDL,CDC
 SG_ APSCJDSA : 19|4@0+ (1,0) [0|0] "-"  CDC

BO_ 328 BDC1S41: 32 BDF
 SG_ AXSOC : 79|16@0+ (0.1,0) [0|0] "%"  CDC

BO_ 868 BDC1S45: 8 BDF
 SG_ SLB_VLWF : 9|2@0+ (1,0) [0|0] "-"  CDC

BO_ 467 BDC1S46: 8 BDF
 SG_ PDS_BUZ : 3|2@0+ (1,0) [0|0] "-"  CDC
 SG_ PDS_DISP : 1|2@0+ (1,0) [0|0] "-"  CDC

BO_ 823 BDC1S48: 32 BDL
 SG_ PS_GO_DD : 7|1@0+ (1,0) [0|0] "-"  BGW,CDC
 SG_ PS_GO_DK : 6|1@0+ (1,0) [0|0] "-"  BGW,CDC
 SG_ FRRSTBDB : 5|3@0+ (1,0) [0|0] "-"  BGW,CDC
 SG_ DISPMODE : 2|1@0+ (1,0) [0|0] "-"  BGW,CDC
 SG_ PS_PD : 1|1@0+ (1,0) [0|0] "-"  BGW,CDC
 SG_ PS_GO_ND : 0|1@0+ (1,0) [0|0] "-"  BGW,CDC
 SG_ MRMAINSW : 15|2@0+ (1,0) [0|0] "-"  BGW,CDC
 SG_ MRSOCANS : 11|4@0+ (1,0) [0|0] "-"  BGW,CDC
 SG_ MRSOCMIN : 23|1@0+ (1,0) [0|0] "-"  BGW,CDC
 SG_ MRRUN : 22|1@0+ (1,0) [0|0] "-"  BGW,CDC
 SG_ MREXITF : 21|3@0+ (1,0) [0|0] "-"  BGW,CDC

BO_ 19 BDC1S52: 64 BDF
 SG_ KZKSEND1 : 7|64@0+ (1,0) [0|0] "-"  CDC
 SG_ KZKSEND2 : 71|64@0+ (1,0) [0|0] "-"  CDC
 SG_ KZKSEND3 : 135|64@0+ (1,0) [0|0] "-"  CDC
 SG_ KZKSEND4 : 199|64@0+ (1,0) [0|0] "-"  CDC
 SG_ KZKSEND5 : 263|64@0+ (1,0) [0|0] "-"  CDC
 SG_ KZKSEND6 : 327|64@0+ (1,0) [0|0] "-"  CDC
 SG_ KZKSEND7 : 391|64@0+ (1,0) [0|0] "-"  CDC
 SG_ KZKSEND8 : 455|64@0+ (1,0) [0|0] "-"  CDC

BO_ 27 BDC1S60: 64 BDF
 SG_ KZKID : 7|8@0+ (1,0) [0|0] "-"  CDC
 SG_ KZKUSAGE : 15|8@0+ (1,0) [0|0] "-"  CDC
 SG_ KZKVERI1 : 23|64@0+ (1,0) [0|0] "-"  CDC
 SG_ KZKVERI2 : 87|64@0+ (1,0) [0|0] "-"  CDC
 SG_ KZKVERI3 : 151|64@0+ (1,0) [0|0] "-"  CDC
 SG_ KZKVERI4 : 215|64@0+ (1,0) [0|0] "-"  CDC

BO_ 833 BDC1S74: 8 BDF
 SG_ POW_ADV : 2|3@0+ (1,0) [0|0] "-"  CDC

BO_ 483 BDC1S81: 32 BDL
 SG_ VPSINFO7 : 30|1@0+ (1,0) [0|0] "-"  CDC
 SG_ VPSINFO6 : 29|1@0+ (1,0) [0|0] "-"  CDC
 SG_ VPSINFO5 : 28|1@0+ (1,0) [0|0] "-"  CDC
 SG_ VPSINFO4 : 27|1@0+ (1,0) [0|0] "-"  CDC
 SG_ VPSINFO3 : 26|1@0+ (1,0) [0|0] "-"  CDC
 SG_ VPSINFO2 : 25|1@0+ (1,0) [0|0] "-"  CDC
 SG_ VPSINFO1 : 24|1@0+ (1,0) [0|0] "-"  CDC
 SG_ VPSINFOS : 39|8@0+ (1,0) [0|0] "-"  CDC
 SG_ VPSISOTA : 55|8@0+ (1,0) [0|0] "-"  CDC
 SG_ APOFRQ : 64|1@0+ (1,0) [0|0] "-"  BGW,CDC,DDM

BO_ 871 BDC1S83: 8 BDF
 SG_ PWRSVSET : 7|4@0+ (1,0) [0|0] "-"  BGW,CDC,DDM
 SG_ PWRSVSOC : 31|16@0+ (0.1,0) [0|0] "kWh"  BGW,CDC,DDM

BO_ 853 BDC1S97: 32 BDF
 SG_ PWCRTRT1 : 71|8@0+ (1,0) [0|0] "-"  CDC
 SG_ PWCRTMD1 : 79|1@0+ (1,0) [0|0] "-"  CDC
 SG_ PWCRTID1 : 78|6@0+ (1,0) [0|0] "-"  CDC

BO_ 856 BDC1S98: 32 BDR
 SG_ PWCRTRT2 : 71|8@0+ (1,0) [0|0] "-"  CDC
 SG_ PWCRTMD2 : 79|1@0+ (1,0) [0|0] "-"  CDC
 SG_ PWCRTID2 : 78|6@0+ (1,0) [0|0] "-"  CDC

BO_ 861 BDC1S99: 32 BDL
 SG_ SBCGOTA : 7|32@0+ (1,0) [0|0] "-"  CDC
 SG_ PWLVOTA : 39|32@0+ (1,0) [0|0] "-"  CDC
 SG_ PWCRTRT3 : 71|8@0+ (1,0) [0|0] "-"  CDC
 SG_ PWCRTMD3 : 79|1@0+ (1,0) [0|0] "-"  CDC
 SG_ PWCRTID3 : 78|6@0+ (1,0) [0|0] "-"  CDC
 SG_ RDYOF_ST : 95|1@0+ (1,0) [0|0] "-"  CDC

BO_ 420 BDC1SA0: 32 BDL
 SG_ PROTREQ : 7|3@0+ (1,0) [0|0] "-"  CDC
 SG_ CYCLCREQ : 4|1@0+ (1,0) [0|0] "-"  CDC
 SG_ DRWUREQ2 : 3|1@0+ (1,0) [0|0] "-"  CDC
 SG_ RMSETREQ : 15|1@0+ (1,0) [0|0] "-"  CDC
 SG_ STRMREQ : 14|2@0+ (1,0) [0|0] "-"  CDC
 SG_ STATREQ : 23|5@0+ (1,0) [0|0] "-"  CDC

BO_ 863 BDC1SA1: 32 BDL
 SG_ PAD_EQ2 : 7|2@0+ (1,0) [0|0] "-"  CDC
 SG_ BSET_PAD : 15|3@0+ (1,0) [0|0] "-"  CDC
 SG_ BSET_PG : 12|2@0+ (1,0) [0|0] "-"  CDC
 SG_ HLACK : 23|2@0+ (1,0) [0|0] "-"  CDC
 SG_ DRBDCABN : 31|1@0+ (1,0) [0|0] "-"  CDC
 SG_ DRGABN : 30|1@0+ (1,0) [0|0] "-"  CDC
 SG_ DRGOFF : 29|1@0+ (1,0) [0|0] "-"  CDC

BO_ 915 BDC1SC1: 32 BDL
 SG_ BDOACK01 : 7|8@0+ (1,0) [0|0] "-"  CDC
 SG_ BDOACK02 : 15|8@0+ (1,0) [0|0] "-"  CDC
 SG_ BDOACK03 : 23|8@0+ (1,0) [0|0] "-"  CDC
 SG_ BDOACK04 : 31|8@0+ (1,0) [0|0] "-"  CDC
 SG_ BDOACK05 : 39|8@0+ (1,0) [0|0] "-"  CDC
 SG_ BDOACK06 : 47|8@0+ (1,0) [0|0] "-"  CDC
 SG_ BDOACK07 : 55|8@0+ (1,0) [0|0] "-"  CDC
 SG_ BDOACK08 : 63|8@0+ (1,0) [0|0] "-"  CDC
 SG_ BDOACK09 : 71|8@0+ (1,0) [0|0] "-"  CDC
 SG_ BDOACK10 : 79|8@0+ (1,0) [0|0] "-"  CDC
 SG_ BDOACK11 : 87|8@0+ (1,0) [0|0] "-"  CDC
 SG_ BDOACK12 : 95|8@0+ (1,0) [0|0] "-"  CDC
 SG_ BDOACRSV : 103|72@0+ (1,0) [0|0] "-"  CDC
 SG_ FV393 : 175|56@0+ (1,0) [0|0] "-"  CDC
 SG_ KZK393 : 231|32@0+ (1,0) [0|0] "-"  CDC

BO_ 917 BDC1SC2: 64 BDL
 SG_ UMASIF01 : 7|16@0+ (1,0) [0|0] "-"  CDC
 SG_ UMASRQ01 : 23|16@0+ (1,0) [0|0] "-"  CDC
 SG_ UMASRV01 : 39|16@0+ (1,0) [0|0] "-"  CDC
 SG_ UMASAD01 : 55|376@0+ (1,0) [0|0] "-"  CDC
 SG_ FV395 : 431|56@0+ (1,0) [0|0] "-"  CDC
 SG_ KZK395 : 487|32@0+ (1,0) [0|0] "-"  CDC

BO_ 918 BDC1SC3: 64 BDL
 SG_ UMASIF02 : 7|16@0+ (1,0) [0|0] "-"  CDC
 SG_ UMASRQ02 : 23|16@0+ (1,0) [0|0] "-"  CDC
 SG_ UMASRV02 : 39|16@0+ (1,0) [0|0] "-"  CDC
 SG_ UMASAD02 : 55|376@0+ (1,0) [0|0] "-"  CDC
 SG_ FV396 : 431|56@0+ (1,0) [0|0] "-"  CDC
 SG_ KZK396 : 487|32@0+ (1,0) [0|0] "-"  CDC

BO_ 922 BDC1SC4: 64 BDL
 SG_ UMASIF03 : 7|16@0+ (1,0) [0|0] "-"  CDC
 SG_ UMASRQ03 : 23|16@0+ (1,0) [0|0] "-"  CDC
 SG_ UMASRV03 : 39|16@0+ (1,0) [0|0] "-"  CDC
 SG_ UMASAD03 : 55|376@0+ (1,0) [0|0] "-"  CDC
 SG_ FV39A : 431|56@0+ (1,0) [0|0] "-"  CDC
 SG_ KZK39A : 487|32@0+ (1,0) [0|0] "-"  CDC

BO_ 923 BDC1SC5: 64 BDL
 SG_ UMASIF04 : 7|16@0+ (1,0) [0|0] "-"  CDC
 SG_ UMASRQ04 : 23|16@0+ (1,0) [0|0] "-"  CDC
 SG_ UMASRV04 : 39|16@0+ (1,0) [0|0] "-"  CDC
 SG_ UMASAD04 : 55|376@0+ (1,0) [0|0] "-"  CDC
 SG_ FV39B : 431|56@0+ (1,0) [0|0] "-"  CDC
 SG_ KZK39B : 487|32@0+ (1,0) [0|0] "-"  CDC

BO_ 925 BDC1SC6: 64 BDL
 SG_ UMASIF05 : 7|16@0+ (1,0) [0|0] "-"  CDC
 SG_ UMASRQ05 : 23|16@0+ (1,0) [0|0] "-"  CDC
 SG_ UMASRV05 : 39|16@0+ (1,0) [0|0] "-"  CDC
 SG_ UMASAD05 : 55|376@0+ (1,0) [0|0] "-"  CDC
 SG_ FV39D : 431|56@0+ (1,0) [0|0] "-"  CDC
 SG_ KZK39D : 487|32@0+ (1,0) [0|0] "-"  CDC

BO_ 926 BDC1SC7: 64 BDL
 SG_ UMASIF06 : 7|16@0+ (1,0) [0|0] "-"  CDC
 SG_ UMASRQ06 : 23|16@0+ (1,0) [0|0] "-"  CDC
 SG_ UMASRV06 : 39|16@0+ (1,0) [0|0] "-"  CDC
 SG_ UMASAD06 : 55|376@0+ (1,0) [0|0] "-"  CDC
 SG_ FV39E : 431|56@0+ (1,0) [0|0] "-"  CDC
 SG_ KZK39E : 487|32@0+ (1,0) [0|0] "-"  CDC

BO_ 927 BDC1SC8: 64 BDL
 SG_ UMASIF07 : 7|16@0+ (1,0) [0|0] "-"  CDC
 SG_ UMASRQ07 : 23|16@0+ (1,0) [0|0] "-"  CDC
 SG_ UMASRV07 : 39|16@0+ (1,0) [0|0] "-"  CDC
 SG_ UMASAD07 : 55|376@0+ (1,0) [0|0] "-"  CDC
 SG_ FV39F : 431|56@0+ (1,0) [0|0] "-"  CDC
 SG_ KZK39F : 487|32@0+ (1,0) [0|0] "-"  CDC

BO_ 933 BDC1SC9: 64 BDL
 SG_ UMASIF08 : 7|16@0+ (1,0) [0|0] "-"  CDC
 SG_ UMASRQ08 : 23|16@0+ (1,0) [0|0] "-"  CDC
 SG_ UMASRV08 : 39|16@0+ (1,0) [0|0] "-"  CDC
 SG_ UMASAD08 : 55|376@0+ (1,0) [0|0] "-"  CDC
 SG_ FV3A5 : 431|56@0+ (1,0) [0|0] "-"  CDC
 SG_ KZK3A5 : 487|32@0+ (1,0) [0|0] "-"  CDC

BO_ 940 BDC1SD1: 64 BDL
 SG_ UMASIF09 : 7|16@0+ (1,0) [0|0] "-"  CDC
 SG_ UMASRQ09 : 23|16@0+ (1,0) [0|0] "-"  CDC
 SG_ UMASRV09 : 39|16@0+ (1,0) [0|0] "-"  CDC
 SG_ UMASAD09 : 55|376@0+ (1,0) [0|0] "-"  CDC
 SG_ FV3AC : 431|56@0+ (1,0) [0|0] "-"  CDC
 SG_ KZK3AC : 487|32@0+ (1,0) [0|0] "-"  CDC

BO_ 942 BDC1SD2: 64 BDL
 SG_ UMASIF10 : 7|16@0+ (1,0) [0|0] "-"  CDC
 SG_ UMASRQ10 : 23|16@0+ (1,0) [0|0] "-"  CDC
 SG_ UMASRV10 : 39|16@0+ (1,0) [0|0] "-"  CDC
 SG_ UMASAD10 : 55|376@0+ (1,0) [0|0] "-"  CDC
 SG_ FV3AE : 431|56@0+ (1,0) [0|0] "-"  CDC
 SG_ KZK3AE : 487|32@0+ (1,0) [0|0] "-"  CDC

BO_ 946 BDC1SD3: 64 BDL
 SG_ UMASIF11 : 7|16@0+ (1,0) [0|0] "-"  CDC
 SG_ UMASRQ11 : 23|16@0+ (1,0) [0|0] "-"  CDC
 SG_ UMASRV11 : 39|16@0+ (1,0) [0|0] "-"  CDC
 SG_ UMASAD11 : 55|376@0+ (1,0) [0|0] "-"  CDC
 SG_ FV3B2 : 431|56@0+ (1,0) [0|0] "-"  CDC
 SG_ KZK3B2 : 487|32@0+ (1,0) [0|0] "-"  CDC

BO_ 947 BDC1SD4: 64 BDL
 SG_ UMASIF12 : 7|16@0+ (1,0) [0|0] "-"  CDC
 SG_ UMASRQ12 : 23|16@0+ (1,0) [0|0] "-"  CDC
 SG_ UMASRV12 : 39|16@0+ (1,0) [0|0] "-"  CDC
 SG_ UMASAD12 : 55|376@0+ (1,0) [0|0] "-"  CDC
 SG_ FV3B3 : 431|56@0+ (1,0) [0|0] "-"  CDC
 SG_ KZK3B3 : 487|32@0+ (1,0) [0|0] "-"  CDC

BO_ 953 BDC1SD5: 64 BDL
 SG_ UMRSIF01 : 7|16@0+ (1,0) [0|0] "-"  CDC
 SG_ UMRSRQ01 : 23|16@0+ (1,0) [0|0] "-"  CDC
 SG_ UMRSRV01 : 39|16@0+ (1,0) [0|0] "-"  CDC
 SG_ UMRSAD01 : 55|376@0+ (1,0) [0|0] "-"  CDC
 SG_ FV3B9 : 431|56@0+ (1,0) [0|0] "-"  CDC
 SG_ KZK3B9 : 487|32@0+ (1,0) [0|0] "-"  CDC

BO_ 956 BDC1SD6: 64 BDL
 SG_ UMRSIF02 : 7|16@0+ (1,0) [0|0] "-"  CDC
 SG_ UMRSRQ02 : 23|16@0+ (1,0) [0|0] "-"  CDC
 SG_ UMRSRV02 : 39|16@0+ (1,0) [0|0] "-"  CDC
 SG_ UMRSAD02 : 55|376@0+ (1,0) [0|0] "-"  CDC
 SG_ FV3BC : 431|56@0+ (1,0) [0|0] "-"  CDC
 SG_ KZK3BC : 487|32@0+ (1,0) [0|0] "-"  CDC

BO_ 966 BDC1SD7: 64 BDL
 SG_ UMRSIF03 : 7|16@0+ (1,0) [0|0] "-"  CDC
 SG_ UMRSRQ03 : 23|16@0+ (1,0) [0|0] "-"  CDC
 SG_ UMRSRV03 : 39|16@0+ (1,0) [0|0] "-"  CDC
 SG_ UMRSAD03 : 55|376@0+ (1,0) [0|0] "-"  CDC
 SG_ FV3C6 : 431|56@0+ (1,0) [0|0] "-"  CDC
 SG_ KZK3C6 : 487|32@0+ (1,0) [0|0] "-"  CDC

BO_ 967 BDC1SD8: 64 BDL
 SG_ UMRSIF04 : 7|16@0+ (1,0) [0|0] "-"  CDC
 SG_ UMRSRQ04 : 23|16@0+ (1,0) [0|0] "-"  CDC
 SG_ UMRSRV04 : 39|16@0+ (1,0) [0|0] "-"  CDC
 SG_ UMRSAD04 : 55|376@0+ (1,0) [0|0] "-"  CDC
 SG_ FV3C7 : 431|56@0+ (1,0) [0|0] "-"  CDC
 SG_ KZK3C7 : 487|32@0+ (1,0) [0|0] "-"  CDC

BO_ 973 BDC1SD9: 64 BDL
 SG_ UMRSIF05 : 7|16@0+ (1,0) [0|0] "-"  CDC
 SG_ UMRSRQ05 : 23|16@0+ (1,0) [0|0] "-"  CDC
 SG_ UMRSRV05 : 39|16@0+ (1,0) [0|0] "-"  CDC
 SG_ UMRSAD05 : 55|376@0+ (1,0) [0|0] "-"  CDC
 SG_ FV3CD : 431|56@0+ (1,0) [0|0] "-"  CDC
 SG_ KZK3CD : 487|32@0+ (1,0) [0|0] "-"  CDC

BO_ 979 BDC1SE1: 64 BDL
 SG_ UMRSIF06 : 7|16@0+ (1,0) [0|0] "-"  CDC
 SG_ UMRSRQ06 : 23|16@0+ (1,0) [0|0] "-"  CDC
 SG_ UMRSRV06 : 39|16@0+ (1,0) [0|0] "-"  CDC
 SG_ UMRSAD06 : 55|376@0+ (1,0) [0|0] "-"  CDC
 SG_ FV3D3 : 431|56@0+ (1,0) [0|0] "-"  CDC
 SG_ KZK3D3 : 487|32@0+ (1,0) [0|0] "-"  CDC

BO_ 982 BDC1SE2: 64 BDL
 SG_ UMRSIF07 : 7|16@0+ (1,0) [0|0] "-"  CDC
 SG_ UMRSRQ07 : 23|16@0+ (1,0) [0|0] "-"  CDC
 SG_ UMRSRV07 : 39|16@0+ (1,0) [0|0] "-"  CDC
 SG_ UMRSAD07 : 55|376@0+ (1,0) [0|0] "-"  CDC
 SG_ FV3D6 : 431|56@0+ (1,0) [0|0] "-"  CDC
 SG_ KZK3D6 : 487|32@0+ (1,0) [0|0] "-"  CDC

BO_ 989 BDC1SE3: 64 BDL
 SG_ UMRSIF08 : 7|16@0+ (1,0) [0|0] "-"  CDC
 SG_ UMRSRQ08 : 23|16@0+ (1,0) [0|0] "-"  CDC
 SG_ UMRSRV08 : 39|16@0+ (1,0) [0|0] "-"  CDC
 SG_ UMRSAD08 : 55|376@0+ (1,0) [0|0] "-"  CDC
 SG_ FV3DD : 431|56@0+ (1,0) [0|0] "-"  CDC
 SG_ KZK3DD : 487|32@0+ (1,0) [0|0] "-"  CDC

BO_ 993 BDC1SE4: 64 BDL
 SG_ UMRSIF09 : 7|16@0+ (1,0) [0|0] "-"  CDC
 SG_ UMRSRQ09 : 23|16@0+ (1,0) [0|0] "-"  CDC
 SG_ UMRSRV09 : 39|16@0+ (1,0) [0|0] "-"  CDC
 SG_ UMRSAD09 : 55|376@0+ (1,0) [0|0] "-"  CDC
 SG_ FV3E1 : 431|56@0+ (1,0) [0|0] "-"  CDC
 SG_ KZK3E1 : 487|32@0+ (1,0) [0|0] "-"  CDC

BO_ 1003 BDC1SE5: 64 BDL
 SG_ UMRSIF10 : 7|16@0+ (1,0) [0|0] "-"  CDC
 SG_ UMRSRQ10 : 23|16@0+ (1,0) [0|0] "-"  CDC
 SG_ UMRSRV10 : 39|16@0+ (1,0) [0|0] "-"  CDC
 SG_ UMRSAD10 : 55|376@0+ (1,0) [0|0] "-"  CDC
 SG_ FV3EB : 431|56@0+ (1,0) [0|0] "-"  CDC
 SG_ KZK3EB : 487|32@0+ (1,0) [0|0] "-"  CDC

BO_ 1007 BDC1SE6: 64 BDL
 SG_ UMRSIF11 : 7|16@0+ (1,0) [0|0] "-"  CDC
 SG_ UMRSRQ11 : 23|16@0+ (1,0) [0|0] "-"  CDC
 SG_ UMRSRV11 : 39|16@0+ (1,0) [0|0] "-"  CDC
 SG_ UMRSAD11 : 55|376@0+ (1,0) [0|0] "-"  CDC
 SG_ FV3EF : 431|56@0+ (1,0) [0|0] "-"  CDC
 SG_ KZK3EF : 487|32@0+ (1,0) [0|0] "-"  CDC

BO_ 1013 BDC1SE7: 64 BDL
 SG_ UMRSIF12 : 7|16@0+ (1,0) [0|0] "-"  CDC
 SG_ UMRSRQ12 : 23|16@0+ (1,0) [0|0] "-"  CDC
 SG_ UMRSRV12 : 39|16@0+ (1,0) [0|0] "-"  CDC
 SG_ UMRSAD12 : 55|376@0+ (1,0) [0|0] "-"  CDC
 SG_ FV3F5 : 431|56@0+ (1,0) [0|0] "-"  CDC
 SG_ KZK3F5 : 487|32@0+ (1,0) [0|0] "-"  CDC

BO_ 1059 BDC1SE8: 64 BDL
 SG_ UMIIFTT : 7|16@0+ (1,0) [0|0] "-"  CDC
 SG_ UMIREQTT : 23|16@0+ (1,0) [0|0] "-"  CDC
 SG_ UMIRSVTT : 39|16@0+ (1,0) [0|0] "-"  CDC
 SG_ UMIDATTT : 55|464@0+ (1,0) [0|0] "-"  CDC

BO_ 1065 BDC1SE9: 64 BDL
 SG_ UMIIFS1 : 7|16@0+ (1,0) [0|0] "-"  CDC
 SG_ UMIREQS1 : 23|16@0+ (1,0) [0|0] "-"  CDC
 SG_ UMIRSVS1 : 39|16@0+ (1,0) [0|0] "-"  CDC
 SG_ UMIDATS1 : 55|464@0+ (1,0) [0|0] "-"  CDC

BO_ 1072 BDC1SF1: 64 BDL
 SG_ UMIIFS2 : 7|16@0+ (1,0) [0|0] "-"  CDC
 SG_ UMIREQS2 : 23|16@0+ (1,0) [0|0] "-"  CDC
 SG_ UMIRSVS2 : 39|16@0+ (1,0) [0|0] "-"  CDC
 SG_ UMIDATS2 : 55|464@0+ (1,0) [0|0] "-"  CDC

BO_ 1152 BDC1SF2: 64 BDL
 SG_ UMIIFS3 : 7|16@0+ (1,0) [0|0] "-"  CDC
 SG_ UMIREQS3 : 23|16@0+ (1,0) [0|0] "-"  CDC
 SG_ UMIRSVS3 : 39|16@0+ (1,0) [0|0] "-"  CDC
 SG_ UMIDATS3 : 55|464@0+ (1,0) [0|0] "-"  CDC

BO_ 1156 BDC1SF3: 64 BDL
 SG_ UMIIFS4 : 7|16@0+ (1,0) [0|0] "-"  CDC
 SG_ UMIREQS4 : 23|16@0+ (1,0) [0|0] "-"  CDC
 SG_ UMIRSVS4 : 39|16@0+ (1,0) [0|0] "-"  CDC
 SG_ UMIDATS4 : 55|464@0+ (1,0) [0|0] "-"  CDC

BO_ 1169 BDC1SF4: 64 BDL
 SG_ UMIIFPW : 7|16@0+ (1,0) [0|0] "-"  CDC
 SG_ UMIREQPW : 23|16@0+ (1,0) [0|0] "-"  CDC
 SG_ UMIRSVPW : 39|16@0+ (1,0) [0|0] "-"  CDC
 SG_ UMIDATPW : 55|464@0+ (1,0) [0|0] "-"  CDC

BO_ 1175 BDC1SF6: 64 BDL
 SG_ UMIIFSD : 7|16@0+ (1,0) [0|0] "-"  CDC
 SG_ UMIREQSD : 23|16@0+ (1,0) [0|0] "-"  CDC
 SG_ UMIRSVSD : 39|16@0+ (1,0) [0|0] "-"  CDC
 SG_ UMIDATSD : 55|464@0+ (1,0) [0|0] "-"  CDC

BO_ 1318 BDC1SG4: 64 BDL
 SG_ UMIIFDL : 7|16@0+ (1,0) [0|0] "-"  CDC
 SG_ UMIREQDL : 23|16@0+ (1,0) [0|0] "-"  CDC
 SG_ UMIRSVDL : 39|16@0+ (1,0) [0|0] "-"  CDC
 SG_ UMIDATDL : 55|464@0+ (1,0) [0|0] "-"  CDC

BO_ 1323 BDC1SG6: 64 BDL
 SG_ UMIIFI1 : 7|16@0+ (1,0) [0|0] "-"  CDC
 SG_ UMIREQI1 : 23|16@0+ (1,0) [0|0] "-"  CDC
 SG_ UMIRSVI1 : 39|16@0+ (1,0) [0|0] "-"  CDC
 SG_ UMIDATI1 : 55|464@0+ (1,0) [0|0] "-"  CDC

BO_ 1324 BDC1SG7: 64 BDL
 SG_ UMIIFI2 : 7|16@0+ (1,0) [0|0] "-"  CDC
 SG_ UMIREQI2 : 23|16@0+ (1,0) [0|0] "-"  CDC
 SG_ UMIRSVI2 : 39|16@0+ (1,0) [0|0] "-"  CDC
 SG_ UMIDATI2 : 55|464@0+ (1,0) [0|0] "-"  CDC

BO_ 1328 BDC1SG8: 64 BDL
 SG_ UMIIFI3 : 7|16@0+ (1,0) [0|0] "-"  CDC
 SG_ UMIREQI3 : 23|16@0+ (1,0) [0|0] "-"  CDC
 SG_ UMIRSVI3 : 39|16@0+ (1,0) [0|0] "-"  CDC
 SG_ UMIDATI3 : 55|464@0+ (1,0) [0|0] "-"  CDC

BO_ 1329 BDC1SG9: 64 BDL
 SG_ UMIIFDP : 7|16@0+ (1,0) [0|0] "-"  CDC
 SG_ UMIREQDP : 23|16@0+ (1,0) [0|0] "-"  CDC
 SG_ UMIRSVDP : 39|16@0+ (1,0) [0|0] "-"  CDC
 SG_ UMIDATDP : 55|464@0+ (1,0) [0|0] "-"  CDC

BO_ 1332 BDC1SH3: 64 BDL
 SG_ UMIIFFG : 7|16@0+ (1,0) [0|0] "-"  CDC
 SG_ UMIREQFG : 23|16@0+ (1,0) [0|0] "-"  CDC
 SG_ UMIRSVFG : 39|16@0+ (1,0) [0|0] "-"  CDC
 SG_ UMIDATFG : 55|376@0+ (1,0) [0|0] "-"  CDC
 SG_ FV534 : 431|56@0+ (1,0) [0|0] "-"  CDC
 SG_ KZK534 : 487|32@0+ (1,0) [0|0] "-"  CDC

BO_ 1333 BDC1SH4: 64 BDL
 SG_ UMIIFA1 : 7|16@0+ (1,0) [0|0] "-"  CDC
 SG_ UMIREQA1 : 23|16@0+ (1,0) [0|0] "-"  CDC
 SG_ UMIRSVA1 : 39|16@0+ (1,0) [0|0] "-"  CDC
 SG_ UMIDATA1 : 55|464@0+ (1,0) [0|0] "-"  CDC

BO_ 1335 BDC1SH5: 64 BDL
 SG_ UMIIFA2 : 7|16@0+ (1,0) [0|0] "-"  CDC
 SG_ UMIREQA2 : 23|16@0+ (1,0) [0|0] "-"  CDC
 SG_ UMIRSVA2 : 39|16@0+ (1,0) [0|0] "-"  CDC
 SG_ UMIDATA2 : 55|464@0+ (1,0) [0|0] "-"  CDC

BO_ 1336 BDC1SH6: 64 BDL
 SG_ UMIIFA3 : 7|16@0+ (1,0) [0|0] "-"  CDC
 SG_ UMIREQA3 : 23|16@0+ (1,0) [0|0] "-"  CDC
 SG_ UMIRSVA3 : 39|16@0+ (1,0) [0|0] "-"  CDC
 SG_ UMIDATA3 : 55|464@0+ (1,0) [0|0] "-"  CDC

BO_ 691 BDC1SH8: 8 BDL
 SG_ ST1 : 7|2@0+ (1,0) [0|0] "-"  CDC
 SG_ ST1PER : 5|1@0+ (1,0) [0|0] "-"  CDC
 SG_ ST2 : 4|2@0+ (1,0) [0|0] "-"  CDC
 SG_ ST2PER : 2|1@0+ (1,0) [0|0] "-"  CDC
 SG_ ST3 : 1|2@0+ (1,0) [0|0] "-"  CDC
 SG_ ST3PER : 15|1@0+ (1,0) [0|0] "-"  CDC
 SG_ ST4 : 14|2@0+ (1,0) [0|0] "-"  CDC
 SG_ ST4PER : 12|1@0+ (1,0) [0|0] "-"  CDC
 SG_ ST5 : 11|2@0+ (1,0) [0|0] "-"  CDC
 SG_ ST5PER : 9|1@0+ (1,0) [0|0] "-"  CDC
 SG_ ST6 : 8|2@0+ (1,0) [0|0] "-"  CDC
 SG_ ST6PER : 22|1@0+ (1,0) [0|0] "-"  CDC
 SG_ ST7 : 21|2@0+ (1,0) [0|0] "-"  CDC
 SG_ ST7PER : 19|1@0+ (1,0) [0|0] "-"  CDC
 SG_ ST8 : 18|2@0+ (1,0) [0|0] "-"  CDC
 SG_ ST8PER : 16|1@0+ (1,0) [0|0] "-"  CDC
 SG_ ST9 : 31|2@0+ (1,0) [0|0] "-"  CDC
 SG_ ST9PER : 29|1@0+ (1,0) [0|0] "-"  CDC
 SG_ ST10 : 28|2@0+ (1,0) [0|0] "-"  CDC
 SG_ ST10PER : 26|1@0+ (1,0) [0|0] "-"  CDC
 SG_ ST11 : 25|2@0+ (1,0) [0|0] "-"  CDC
 SG_ ST11PER : 39|1@0+ (1,0) [0|0] "-"  CDC
 SG_ ST12 : 38|2@0+ (1,0) [0|0] "-"  CDC
 SG_ ST12PER : 36|1@0+ (1,0) [0|0] "-"  CDC
 SG_ ST13 : 35|2@0+ (1,0) [0|0] "-"  CDC
 SG_ ST13PER : 33|1@0+ (1,0) [0|0] "-"  CDC
 SG_ ST14 : 32|2@0+ (1,0) [0|0] "-"  CDC
 SG_ ST14PER : 46|1@0+ (1,0) [0|0] "-"  CDC
 SG_ ST15 : 45|2@0+ (1,0) [0|0] "-"  CDC
 SG_ ST15PER : 43|1@0+ (1,0) [0|0] "-"  CDC
 SG_ ST16 : 42|2@0+ (1,0) [0|0] "-"  CDC
 SG_ ST16PER : 40|1@0+ (1,0) [0|0] "-"  CDC
 SG_ ST17 : 55|2@0+ (1,0) [0|0] "-"  CDC
 SG_ ST17PER : 53|1@0+ (1,0) [0|0] "-"  CDC
 SG_ ST18 : 52|2@0+ (1,0) [0|0] "-"  CDC
 SG_ ST18PER : 50|1@0+ (1,0) [0|0] "-"  CDC

BO_ 1157 BDC1SZ1: 32 BDL
 SG_ VSI_L4B : 55|8@0+ (1,0) [0|0] "-"  BGW,CDC
 SG_ VSI_L6K : 79|8@0+ (1,0) [0|0] "-"  BGW,CDC
 SG_ VSI_L7E : 95|8@0+ (1,0) [0|0] "-"  BGW,CDC

BO_ 1084 BDC1SZ3: 32 BDL
 SG_ VSI_B3N : 95|8@0+ (1,0) [0|0] "-"  CDC
 SG_ VSI_K1B : 167|8@0+ (1,0) [0|0] "-"  CDC
 SG_ VSI_U4C : 183|8@0+ (1,0) [0|0] "-"  CDC
 SG_ VSI_B2B : 199|8@0+ (1,0) [0|0] "-"  CDC
 SG_ VSI_B2C : 207|8@0+ (1,0) [0|0] "-"  CDC
 SG_ VSI_U4Y : 215|8@0+ (1,0) [0|0] "-"  CDC

BO_ 1158 BDC1SZ5: 32 BDL
 SG_ VSI_C7E : 31|8@0+ (1,0) [0|0] "-"  CDC,DDM
 SG_ VSI_C7F : 39|8@0+ (1,0) [0|0] "-"  CDC,DDM
 SG_ VSI_G4A : 71|8@0+ (1,0) [0|0] "-"  CDC
 SG_ VSI_G4B : 79|8@0+ (1,0) [0|0] "-"  CDC

BO_ 891 BDF3S01: 32 BDF
 SG_ ACPRE_AD : 55|8@0+ (0.01953125,0) [0|0] "V"  CDC
 SG_ EXPMIP : 56|9@0+ (50,0) [0|0] "W"  CDC,DDM
 SG_ AMR : 87|16@0+ (1,0) [0|0] "rpm"  CDC
 SG_ MIP : 103|8@0+ (50,0) [0|0] "W"  CDC

BO_ 397 BDF3S02: 32 BDF
 SG_ HVH_ATPW : 114|11@0+ (10,0) [0|0] "W"  CDC

BO_ 410 BDR3S02: 32 BDR
 SG_ COMPRP_A : 23|16@0+ (1,0) [0|0] "rpm"  CDC
 SG_ ACMODE_P : 42|2@0+ (1,0) [0|0] "-"  CDC

BO_ 971 BKD1S01: 8 BDL
 SG_ PBD_MAIN : 18|1@0+ (1,0) [0|0] "-"  CDC
 SG_ LOCK_IF : 26|1@0+ (1,0) [0|0] "-"  CDC
 SG_ BZ_VOL : 38|2@0+ (1,0) [0|0] "-"  CDC
 SG_ OPN_POS : 46|3@0+ (1,0) [0|0] "-"  CDC
 SG_ KICK_CON : 55|1@0+ (1,0) [0|0] "-"  CDC
 SG_ KICK_FNT : 54|1@0+ (1,0) [0|0] "-"  CDC
 SG_ KSSCONTL : 49|1@0+ (1,0) [0|0] "-"  CDC
 SG_ KSSFNTTL : 48|1@0+ (1,0) [0|0] "-"  CDC
 SG_ BVC_FNT : 63|1@0+ (1,0) [0|0] "-"  CDC
 SG_ MSC_FNT : 62|1@0+ (1,0) [0|0] "-"  CDC
 SG_ DOC_FNT : 61|1@0+ (1,0) [0|0] "-"  CDC

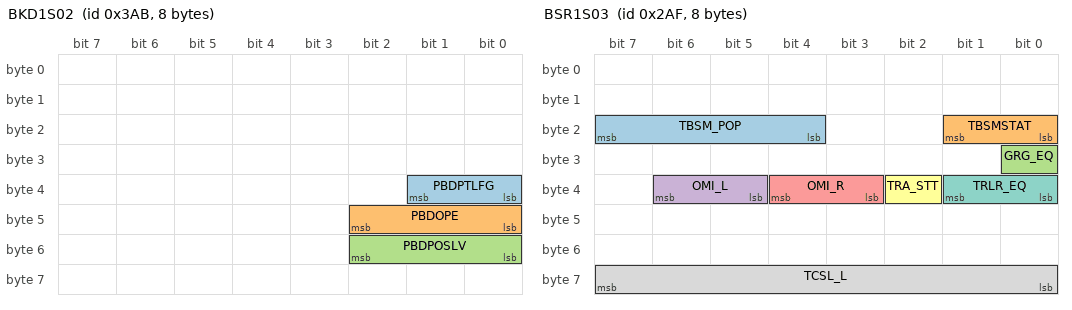
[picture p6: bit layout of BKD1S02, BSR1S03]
BO_ 939 BKD1S02: 8 BDL
 SG_ PBDPTLFG : 33|2@0+ (1,0) [0|0] "-"  CDC
 SG_ PBDOPE : 42|3@0+ (1,0) [0|0] "-"  CDC
 SG_ PBDPOSLV : 50|3@0+ (1,0) [0|0] "-"  CDC

BO_ 1014 BSR1S01: 8 ADC
 SG_ BSD_STAT : 7|3@0+ (1,0) [0|0] "-"  BDL,CDC
 SG_ RCTA_DIR : 4|3@0+ (1,0) [0|0] "-"  BDL,CDC
 SG_ BSD_SW : 15|1@0+ (1,0) [0|0] "-"  BDL,CDC
 SG_ RCTA_EQ : 14|1@0+ (1,0) [0|0] "-"  BDL,CDC
 SG_ RCTADISP : 11|1@0+ (1,0) [0|0] "-"  BDL,CDC
 SG_ RCTA_SW : 9|1@0+ (1,0) [0|0] "-"  CDC
 SG_ BSD_BUZ : 23|1@0+ (1,0) [0|0] "-"  BDL,CDC
 SG_ BSD_ILCR : 22|1@0+ (1,0) [0|0] "-"  BDL,CDC
 SG_ BSD_ILV : 21|3@0+ (1,0) [0|0] "-"  CDC
 SG_ BSD_ITCR : 18|1@0+ (1,0) [0|0] "-"  BDL,CDC
 SG_ BSD_ITV : 17|2@0+ (1,0) [0|0] "-"  BDL,CDC
 SG_ FHL_STAT : 31|3@0+ (1,0) [0|0] "-"  BDL,CDC
 SG_ ADDSTRI2 : 35|1@0+ (1,0) [0|0] "-"  BDL,CDC
 SG_ ADDSTRI1 : 34|1@0+ (1,0) [0|0] "-"  BDL,CDC
 SG_ BSD_TTR : 47|1@0+ (1,0) [0|0] "-"  BDL,CDC
 SG_ BSD_SWR : 44|1@0+ (1,0) [0|0] "-"  BDL,CDC
 SG_ RCTA_SWR : 43|1@0+ (1,0) [0|0] "-"  BDL,CDC
 SG_ ADDS_EQ : 40|1@0+ (1,0) [0|0] "-"  BDL,CDC
 SG_ FHL_EQ : 55|1@0+ (1,0) [0|0] "-"  BDL,CDC
 SG_ BSD_SMS : 54|2@0+ (1,0) [0|0] "-"  BDL,CDC
 SG_ RTAN_ITV : 51|2@0+ (1,0) [0|0] "-"  BDL,CDC
 SG_ RTAN_SW : 49|1@0+ (1,0) [0|0] "-"  BDL,CDC
 SG_ RTAN_SWR : 48|1@0+ (1,0) [0|0] "-"  BDL,CDC
 SG_ RTANITCR : 63|1@0+ (1,0) [0|0] "-"  BDL,CDC
 SG_ RTANDISM : 61|1@0+ (1,0) [0|0] "-"  BDL,CDC
 SG_ BSDDISP2 : 60|1@0+ (1,0) [0|0] "-"  BDL,CDC
 SG_ BSDDISP1 : 59|1@0+ (1,0) [0|0] "-"  BDL,CDC
 SG_ DOA_BUZ : 58|3@0+ (1,0) [0|0] "-"  BDL,CDC

BO_ 565 BSR1S02: 8 ADC
 SG_ DOA_EQ : 7|1@0+ (1,0) [0|0] "-"  CDC
 SG_ DOA_STAT : 6|3@0+ (1,0) [0|0] "-"  CDC
 SG_ DOAM_FR : 11|2@0+ (1,0) [0|0] "-"  CDC
 SG_ DOAM_FL : 9|2@0+ (1,0) [0|0] "-"  CDC
 SG_ DOAM_RR : 23|2@0+ (1,0) [0|0] "-"  CDC
 SG_ DOAM_RL : 21|2@0+ (1,0) [0|0] "-"  CDC
 SG_ DOAM_TR : 19|1@0+ (1,0) [0|0] "-"  CDC
 SG_ DOAM_TL : 18|1@0+ (1,0) [0|0] "-"  CDC
 SG_ DOAM_VEH : 17|1@0+ (1,0) [0|0] "-"  CDC
 SG_ DOA_ITCR : 16|1@0+ (1,0) [0|0] "-"  CDC
 SG_ DOA_VORH : 31|2@0+ (1,0) [0|0] "-"  CDC
 SG_ DOA_VOLH : 29|2@0+ (1,0) [0|0] "-"  CDC
 SG_ DOA_STVO : 27|2@0+ (1,0) [0|0] "-"  CDC
 SG_ DOA_SWR : 25|1@0+ (1,0) [0|0] "-"  CDC
 SG_ DOA_SW : 24|1@0+ (1,0) [0|0] "-"  CDC
 SG_ DOAM_MSG : 39|1@0+ (1,0) [0|0] "-"  CDC
 SG_ DOA_ITV : 38|2@0+ (1,0) [0|0] "-"  CDC
 SG_ ADDS_SW : 36|1@0+ (1,0) [0|0] "-"  CDC
 SG_ DOAVOL_R : 33|1@0+ (1,0) [0|0] "-"  CDC
 SG_ ADDS_SWR : 32|1@0+ (1,0) [0|0] "-"  CDC
 SG_ BSR_STAT : 53|3@0+ (1,0) [0|0] "-"  CDC
 SG_ BSMDISPR : 58|1@0+ (1,0) [0|0] "-"  CDC
 SG_ BSMDISPL : 57|1@0+ (1,0) [0|0] "-"  CDC

BO_ 687 BSR1S03: 8 ADC
 SG_ TBSM_POP : 23|4@0+ (1,0) [0|0] "-"  CDC
 SG_ TBSMSTAT : 17|2@0+ (1,0) [0|0] "-"  CDC
 SG_ GRG_EQ : 24|1@0+ (1,0) [0|0] "-"  CDC
 SG_ OMI_L : 38|2@0+ (1,0) [0|0] "-"  CDC
 SG_ OMI_R : 36|2@0+ (1,0) [0|0] "-"  CDC
 SG_ TRA_STT : 34|1@0+ (1,0) [0|0] "-"  CDC
 SG_ TRLR_EQ : 33|2@0+ (1,0) [0|0] "-"  CDC
 SG_ TCSL_L : 63|8@0+ (50,0) [0|0] "mm"  CDC

BO_ 1090 CDC1N01: 8 CDC
 SG_ CDCREV : 7|8@0+ (1,0) [0|0] "-" Vector__XXX

BO_ 819 CDC1S01: 32 CDC
 SG_ ODO_MET : 71|32@0+ (0.1,0) [0|0] "km"  BDL
 SG_ FV333 : 175|56@0+ (1,0) [0|0] "-"  BDL
 SG_ KZK333 : 231|32@0+ (1,0) [0|0] "-"  BDL

BO_ 820 CDC1S03: 32 CDC
 SG_ PRMEXE_M : 7|3@0+ (1,0) [0|0] "-"  BDL
 SG_ REQEXE_M : 4|2@0+ (1,0) [0|0] "-"  BDL
 SG_ DIDEXE_M : 2|3@0+ (1,0) [0|0] "-"  BDL
 SG_ DEL_UN_M : 15|3@0+ (1,0) [0|0] "-"  BDL
 SG_ MREQDP_M : 12|2@0+ (1,0) [0|0] "-"  BDL
 SG_ MSRDRV_M : 10|3@0+ (1,0) [0|0] "-"  BDL
 SG_ OPTEXE_M : 16|1@0+ (1,0) [0|0] "-"  BDL

BO_ 849 CDC1S04: 8 CDC
 SG_ ETHWU_21 : 7|1@0+ (1,0) [0|0] "-"  ADC,BGW
 SG_ ETHWU_23 : 5|1@0+ (1,0) [0|0] "-"  BDF,BGW

BO_ 473 CMB1S03: 8 BDL
 SG_ HED_S : 12|1@0+ (1,0) [0|0] "-"  BGW,CDC,DDM
 SG_ TAL_S : 11|1@0+ (1,0) [0|0] "-"  BGW,CDC,DDM
 SG_ DRL_S : 10|1@0+ (1,0) [0|0] "-"  BGW,CDC,DDM
 SG_ AUT_S : 9|1@0+ (1,0) [0|0] "-"  BGW,CDC,DDM
 SG_ OFF_S : 8|1@0+ (1,0) [0|0] "-"  BGW,CDC,DDM
 SG_ AHB_S : 22|1@0+ (1,0) [0|0] "-"  BGW,CDC,DDM
 SG_ PAS_S : 21|1@0+ (1,0) [0|0] "-"  BGW,CDC,DDM
 SG_ HIB_S : 20|1@0+ (1,0) [0|0] "-"  BGW,CDC,DDM
 SG_ BW_S : 18|1@0+ (1,0) [0|0] "-"  BGW,CDC,DDM
 SG_ RFG_S : 17|1@0+ (1,0) [0|0] "-"  BGW,CDC,DDM
 SG_ FOG_S : 16|1@0+ (1,0) [0|0] "-"  BGW,CDC,DDM
 SG_ CRGL_S : 43|1@0+ (1,0) [0|0] "-"  BGW,CDC,DDM
 SG_ CRGR_S : 42|1@0+ (1,0) [0|0] "-"  BGW,CDC,DDM
 SG_ TRNL_S : 41|1@0+ (1,0) [0|0] "-"  BGW,CDC,DDM
 SG_ TRNR_S : 40|1@0+ (1,0) [0|0] "-"  BGW,CDC,DDM
 SG_ CXP_TERR : 50|1@0+ (1,0) [0|0] "-"  BGW,CDC,DDM
 SG_ CXP_JDGT : 49|2@0+ (1,0) [0|0] "-"  BGW,CDC,DDM

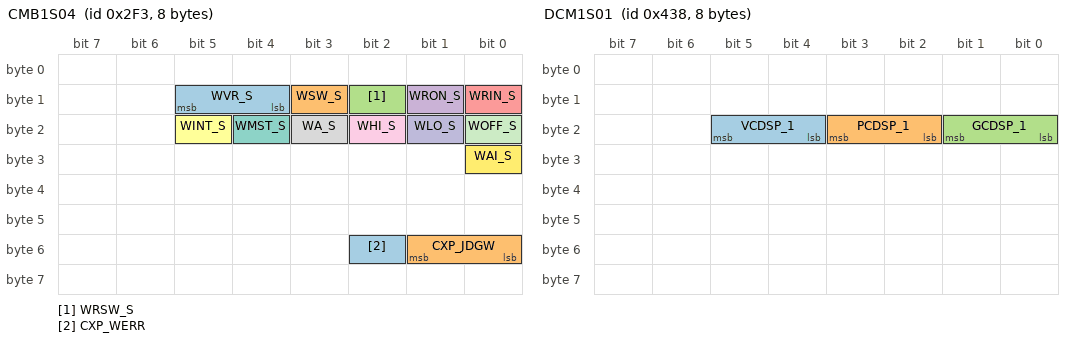
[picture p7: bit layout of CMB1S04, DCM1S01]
BO_ 755 CMB1S04: 8 BDL
 SG_ WVR_S : 13|2@0+ (1,0) [0|0] "-"  CDC
 SG_ WSW_S : 11|1@0+ (1,0) [0|0] "-"  CDC
 SG_ WRSW_S : 10|1@0+ (1,0) [0|0] "-"  CDC
 SG_ WRON_S : 9|1@0+ (1,0) [0|0] "-"  CDC
 SG_ WRIN_S : 8|1@0+ (1,0) [0|0] "-"  CDC
 SG_ WINT_S : 21|1@0+ (1,0) [0|0] "-"  CDC
 SG_ WMST_S : 20|1@0+ (1,0) [0|0] "-"  CDC
 SG_ WA_S : 19|1@0+ (1,0) [0|0] "-"  CDC
 SG_ WHI_S : 18|1@0+ (1,0) [0|0] "-"  CDC
 SG_ WLO_S : 17|1@0+ (1,0) [0|0] "-"  CDC
 SG_ WOFF_S : 16|1@0+ (1,0) [0|0] "-"  CDC
 SG_ WAI_S : 24|1@0+ (1,0) [0|0] "-"  CDC
 SG_ CXP_WERR : 50|1@0+ (1,0) [0|0] "-"  CDC
 SG_ CXP_JDGW : 49|2@0+ (1,0) [0|0] "-"  CDC

BO_ 1080 DCM1S01: 8 BGW
 SG_ VCDSP_1 : 21|2@0+ (1,0) [0|0] "-"  BDL,CDC
 SG_ PCDSP_1 : 19|2@0+ (1,0) [0|0] "-"  BDL,CDC
 SG_ GCDSP_1 : 17|2@0+ (1,0) [0|0] "-"  BDL,CDC

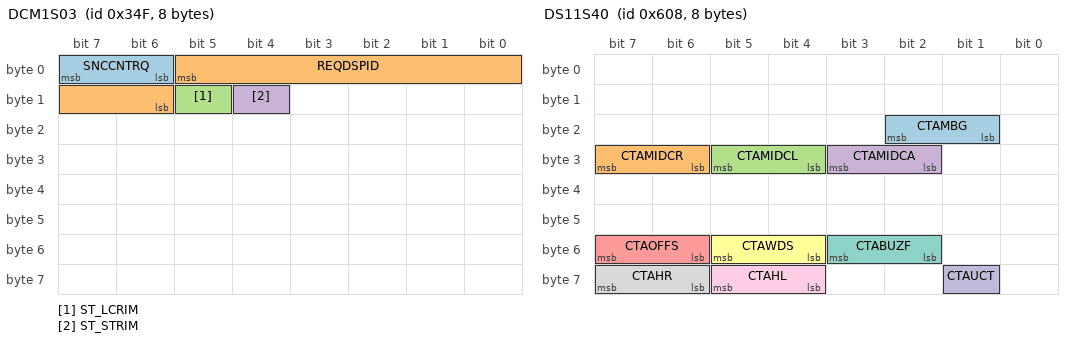
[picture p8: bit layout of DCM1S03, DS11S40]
BO_ 847 DCM1S03: 8 BGW
 SG_ SNCCNTRQ : 7|2@0+ (1,0) [0|0] "-"  CDC
 SG_ REQDSPID : 5|8@0+ (1,0) [0|0] "-"  CDC
 SG_ ST_LCRIM : 13|1@0+ (1,0) [0|0] "-"  CDC
 SG_ ST_STRIM : 12|1@0+ (1,0) [0|0] "-"  CDC

BO_ 867 DCM1S04: 32 BGW
 SG_ RSCOM811 : 7|8@0+ (1,0) [0|0] "-"  CDC
 SG_ RSCOM812 : 15|8@0+ (1,0) [0|0] "-"  CDC
 SG_ RSCOM813 : 23|8@0+ (1,0) [0|0] "-"  CDC
 SG_ RSCOM814 : 31|8@0+ (1,0) [0|0] "-"  CDC
 SG_ RSCOM815 : 39|8@0+ (1,0) [0|0] "-"  CDC
 SG_ RSCOM816 : 47|8@0+ (1,0) [0|0] "-"  CDC
 SG_ RSCOM817 : 55|8@0+ (1,0) [0|0] "-"  CDC
 SG_ RSCOM818 : 63|8@0+ (1,0) [0|0] "-"  CDC
 SG_ RSCOMEX1 : 71|64@0+ (1,0) [0|0] "-"  CDC
 SG_ RSCOMEX2 : 135|64@0+ (1,0) [0|0] "-"  CDC
 SG_ RSCOMEX3 : 199|64@0+ (1,0) [0|0] "-"  CDC

BO_ 840 DCM1S08: 8 BGW
 SG_ ETHWU_32 : 6|1@0+ (1,0) [0|0] "-"  CDC

BO_ 184 DDM1S12: 64 DDM
 SG_ BKTQA : 167|8@0+ (16,0) [0|0] "Nm"  BGW,CDC
 SG_ FBKSYS : 175|1@0+ (1,0) [0|0] "-"  BGW,CDC
 SG_ TBKCSYS2 : 174|1@0+ (1,0) [0|0] "-"  BGW,CDC
 SG_ TBKCR_AX : 172|13@0- (0.01,0) [0|0] "m/s^2"  BGW,CDC
 SG_ FBKDR_AX : 332|13@0- (0.01,0) [0|0] "m/s^2"  BGW,CDC
 SG_ FBKDRSYS : 351|1@0+ (1,0) [0|0] "-"  BGW,CDC

BO_ 750 DDM1S16: 32 DDM
 SG_ NMRBR_MD : 39|1@0+ (1,0) [0|0] "-"  BGW,CDC
 SG_ BHSWEXT : 38|1@0+ (1,0) [0|0] "-"  BGW,CDC

BO_ 471 DDM1S17: 32 DDM
 SG_ E_CRC1D7 : 7|16@0+ (1,0) [0|0] "-"  CDC
 SG_ E_CNT1D7 : 23|8@0+ (1,0) [0|0] "-"  CDC
 SG_ B_BRKW : 30|2@0+ (1,0) [0|0] "-"  CDC
 SG_ BRK_MID : 28|1@0+ (1,0) [0|0] "-"  CDC
 SG_ B_ABS : 27|3@0+ (1,0) [0|0] "-"  CDC
 SG_ ABS_MID : 24|1@0+ (1,0) [0|0] "-"  CDC
 SG_ B_EBW : 39|3@0+ (1,0) [0|0] "-"  CDC
 SG_ EBW_MID : 36|1@0+ (1,0) [0|0] "-"  CDC
 SG_ B_BRLV : 35|1@0+ (1,0) [0|0] "-"  CDC
 SG_ TRCOFF : 34|1@0+ (1,0) [0|0] "-"  CDC
 SG_ TRCCONRL : 33|1@0+ (1,0) [0|0] "-"  CDC
 SG_ TRCCONRR : 32|1@0+ (1,0) [0|0] "-"  CDC
 SG_ TRCCONFL : 47|1@0+ (1,0) [0|0] "-"  CDC
 SG_ TRCCONFR : 46|1@0+ (1,0) [0|0] "-"  CDC
 SG_ TRC_MID : 45|1@0+ (1,0) [0|0] "-"  CDC
 SG_ VSCOFF : 44|2@0+ (1,0) [0|0] "-"  CDC
 SG_ SLP_WL : 42|3@0+ (1,0) [0|0] "-"  CDC
 SG_ B_ALSD : 55|2@0+ (1,0) [0|0] "-"  CDC
 SG_ BHEXIST : 53|1@0+ (1,0) [0|0] "-"  CDC
 SG_ B_DAINDP : 52|2@0+ (1,0) [0|0] "-"  CDC
 SG_ B_DAINDC : 50|3@0+ (1,0) [0|0] "-"  CDC
 SG_ B_DAINFO : 63|5@0+ (1,0) [0|0] "-"  CDC
 SG_ B_OTA : 57|2@0+ (1,0) [0|0] "-"  CDC
 SG_ OTA_DISP : 71|3@0+ (1,0) [0|0] "-"  CDC
 SG_ VSCEXPRT : 68|1@0+ (1,0) [0|0] "-"  CDC
 SG_ EXPTLVL : 67|3@0+ (1,0) [0|0] "-"  CDC
 SG_ EXPTCNFG : 79|2@0+ (1,0) [0|0] "-"  CDC
 SG_ EXPTPLUS : 77|1@0+ (1,0) [0|0] "-"  CDC
 SG_ B_DACIND : 76|2@0+ (1,0) [0|0] "-"  CDC
 SG_ DAC_DISP : 74|2@0+ (1,0) [0|0] "-"  CDC
 SG_ DAC_SETV : 87|6@0+ (1,0) [0|0] "km/h"  CDC
 SG_ CRAWLIND : 81|2@0+ (1,0) [0|0] "-"  CDC
 SG_ CRAWLMID : 95|2@0+ (1,0) [0|0] "-"  CDC
 SG_ CRAWLSPD : 93|3@0+ (1,0) [0|0] "-"  CDC
 SG_ DDRTWV : 90|1@0+ (1,0) [0|0] "-"  CDC
 SG_ VSCEXIST : 89|1@0+ (1,0) [0|0] "-"  CDC
 SG_ B_BUZZER : 103|4@0+ (1,0) [0|0] "-"  CDC
 SG_ B_PKBLP : 99|3@0+ (1,0) [0|0] "-"  CDC
 SG_ B_EPBWL : 111|2@0+ (1,0) [0|0] "-"  CDC
 SG_ B_EPBMID : 109|5@0+ (1,0) [0|0] "-"  CDC
 SG_ MCBW : 119|2@0+ (1,0) [0|0] "-"  CDC
 SG_ CRLSPD2 : 117|6@0+ (1,0) [0|0] "-"  CDC
 SG_ CRLAOFF : 127|1@0+ (1,0) [0|0] "-"  CDC
 SG_ CRLSRINF : 126|2@0+ (1,0) [0|0] "-"  CDC

BO_ 730 DDM1S20: 32 DDM
 SG_ POSIREQ : 31|8@0+ (1,0) [0|0] "-"  CDC
 SG_ POSIREQ2 : 47|8@0+ (1,0) [0|0] "-"  CDC
 SG_ A_DMODEA : 154|3@0+ (1,0) [0|0] "-"  CDC
 SG_ B_DCMDA1 : 167|1@0+ (1,0) [0|0] "-"  CDC
 SG_ B_DCMDA2 : 166|3@0+ (1,0) [0|0] "-"  CDC
 SG_ B_DCMDA3 : 163|4@0+ (1,0) [0|0] "-"  CDC

BO_ 741 DDM1S35: 32 DDM
 SG_ GRLGDBCR : 3|3@0+ (1,0) [0|0] "-"  CDC
 SG_ DMCNVINF : 135|16@0+ (1,0) [0|0] "-"  CDC
 SG_ CNV_MODE : 149|4@0+ (1,0) [0|0] "-"  CDC
 SG_ DMCNVVLD : 145|1@0+ (1,0) [0|0] "-"  CDC

BO_ 641 DDM1SFG: 32 DDM
 SG_ TEC : 7|16@0- (5,0) [0|0] "Wh"  CDC
 SG_ DRVEC : 23|16@0- (5,0) [0|0] "Wh"  CDC
 SG_ ALTEC : 39|16@0- (5,0) [0|0] "Wh"  CDC
 SG_ ACEC : 55|16@0- (5,0) [0|0] "Wh"  CDC
 SG_ BPEC : 71|16@0- (5,0) [0|0] "Wh"  CDC
 SG_ DAEC : 87|16@0- (5,0) [0|0] "Wh"  CDC
 SG_ CAEC : 103|16@0- (5,0) [0|0] "Wh"  CDC
 SG_ CUMTEC : 119|32@0+ (5,0) [0|0] "Wh"  CDC
 SG_ CUMDRVEC : 151|32@0+ (5,0) [0|0] "Wh"  CDC
 SG_ CUMALTEC : 183|32@0+ (5,0) [0|0] "Wh"  CDC
 SG_ CUMACEC : 215|32@0+ (5,0) [0|0] "Wh"  CDC

BO_ 642 DDM1SFH: 32 DDM
 SG_ CUMBPEC : 7|32@0+ (5,0) [0|0] "Wh"  CDC
 SG_ CUMDAEC : 39|32@0+ (5,0) [0|0] "Wh"  CDC
 SG_ CUMCAEC : 71|32@0+ (5,0) [0|0] "Wh"  CDC
 SG_ RBSCC_E : 103|16@0- (1,0) [0|0] "-"  CDC
 SG_ RBSCC_F : 119|16@0- (1,0) [0|0] "-"  CDC
 SG_ RBSCC_G : 135|16@0- (1,0) [0|0] "-"  CDC
 SG_ RBSCC_H : 151|16@0- (1,0) [0|0] "-"  CDC
 SG_ CHGCAL1 : 167|8@0+ (1,0) [0|0] "-"  CDC
 SG_ CHGCAL2 : 175|8@0+ (0.1,0) [0|0] "A"  CDC
 SG_ FSWRP : 183|8@0+ (1,0) [0|0] "-"  CDC
 SG_ U1TOCDC1 : 191|8@0+ (1,0) [0|0] "-"  CDC
 SG_ U1TOCDC2 : 199|8@0+ (1,0) [0|0] "-"  CDC
 SG_ U1TOCDC3 : 207|8@0+ (1,0) [0|0] "-"  CDC
 SG_ S2TOCDC1 : 215|16@0- (1,0) [0|0] "-"  CDC
 SG_ S2TOCDC2 : 231|16@0- (1,0) [0|0] "-"  CDC
 SG_ S2TOCDC3 : 247|16@0- (1,0) [0|0] "-"  CDC

BO_ 1320 DKY1S26: 8 BDL
 SG_ RSISDKME : 7|2@0+ (1,0) [0|0] "-"  CDC
 SG_ RSISIDDK : 5|5@0+ (1,0) [0|0] "-"  CDC

BO_ 290 DMC1S08: 32 ADC
 SG_ FR_DISP : 83|3@0+ (1,0) [0|0] "-"  BGW,CDC

BO_ 1063 DMS1S02: 8 CDC
 SG_ R1_MD_SW : 7|1@0+ (1,0) [0|0] "-"  DDM
 SG_ R2_MD_SW : 6|1@0+ (1,0) [0|0] "-"  DDM
 SG_ R3_MD_SW : 5|1@0+ (1,0) [0|0] "-"  DDM
 SG_ R4_MD_SW : 4|1@0+ (1,0) [0|0] "-"  DDM
 SG_ R5_MD_SW : 3|1@0+ (1,0) [0|0] "-"  DDM
 SG_ R6_MD_SW : 2|1@0+ (1,0) [0|0] "-"  DDM
 SG_ R7_MD_SW : 1|1@0+ (1,0) [0|0] "-"  DDM
 SG_ R8_MD_SW : 0|1@0+ (1,0) [0|0] "-"  DDM
 SG_ R9_MD_SW : 15|1@0+ (1,0) [0|0] "-"  DDM
 SG_ R10_MDSW : 14|1@0+ (1,0) [0|0] "-"  DDM
 SG_ R11_MDSW : 13|1@0+ (1,0) [0|0] "-"  DDM
 SG_ R12_MDSW : 12|1@0+ (1,0) [0|0] "-"  DDM
 SG_ R13_MDSW : 11|1@0+ (1,0) [0|0] "-"  DDM
 SG_ R14_MDSW : 10|1@0+ (1,0) [0|0] "-"  DDM
 SG_ R15_MDSW : 9|1@0+ (1,0) [0|0] "-"  DDM
 SG_ R16_MDSW : 8|1@0+ (1,0) [0|0] "-"  DDM
 SG_ R17_MDSW : 23|1@0+ (1,0) [0|0] "-"  DDM
 SG_ R18_MDSW : 22|1@0+ (1,0) [0|0] "-"  DDM
 SG_ R19_MDSW : 21|1@0+ (1,0) [0|0] "-"  DDM
 SG_ R20_MDSW : 20|1@0+ (1,0) [0|0] "-"  DDM
 SG_ R21_MDSW : 19|1@0+ (1,0) [0|0] "-"  DDM
 SG_ R22_MDSW : 18|1@0+ (1,0) [0|0] "-"  DDM
 SG_ R23_MDSW : 17|1@0+ (1,0) [0|0] "-"  DDM
 SG_ R24_MDSW : 16|1@0+ (1,0) [0|0] "-"  DDM
 SG_ TW_MD_SW : 31|1@0+ (1,0) [0|0] "-"  DDM
 SG_ CH_MD_SW : 28|1@0+ (1,0) [0|0] "-"  DDM
 SG_ P1_MD_SW : 27|1@0+ (1,0) [0|0] "-"  DDM
 SG_ RG_MD_SW : 26|1@0+ (1,0) [0|0] "-"  DDM
 SG_ CF_MD_SW : 39|1@0+ (1,0) [0|0] "-"  DDM
 SG_ PW_MD_SW : 38|1@0+ (1,0) [0|0] "-"  DDM
 SG_ SN_MD_SW : 37|1@0+ (1,0) [0|0] "-"  DDM
 SG_ SP_MD_SW : 36|1@0+ (1,0) [0|0] "-"  DDM
 SG_ EC_MD_SW : 35|1@0+ (1,0) [0|0] "-"  DDM
 SG_ NR_MD_SW : 34|1@0+ (1,0) [0|0] "-"  DDM
 SG_ CS_MD_SW : 33|1@0+ (1,0) [0|0] "-"  DDM
 SG_ ECORC_SW : 32|1@0+ (1,0) [0|0] "-"  DDM
 SG_ SS_MD_SW : 43|1@0+ (1,0) [0|0] "-"  DDM

BO_ 958 DRL1S03: 8 BDL
 SG_ LPSDWARN : 40|1@0+ (1,0) [0|0] "-"  CDC,DDM

BO_ 943 DRR1S03: 8 BDL
 SG_ RPSDWARN : 40|1@0+ (1,0) [0|0] "-"  CDC,DDM

BO_ 645 DS11S27: 8 ADC
 SG_ DESMUTE : 48|1@0+ (1,0) [0|0] "-"  BGW,CDC

BO_ 791 DS11S37: 8 ADC
 SG_ LCANGBZ : 3|1@0+ (1,0) [0|0] "-"  CDC,DDM
 SG_ LCAVCBZ : 2|1@0+ (1,0) [0|0] "-"  CDC,DDM
 SG_ LCSRQBZ : 1|1@0+ (1,0) [0|0] "-"  CDC,DDM
 SG_ LCSONSD : 9|1@0+ (1,0) [0|0] "-"  CDC,DDM
 SG_ LCSEXIST : 8|1@0+ (1,0) [0|0] "-"  CDC,DDM
 SG_ LCATRAJE : 23|4@0+ (1,0) [0|0] "-"  CDC,DDM
 SG_ LCSLWNGD : 17|2@0+ (1,0) [0|0] "-"  CDC,DDM
 SG_ LCSARRLD : 31|3@0+ (1,0) [0|0] "-"  CDC,DDM
 SG_ LCSARRRD : 28|3@0+ (1,0) [0|0] "-"  CDC,DDM
 SG_ LCSRWNGD : 25|2@0+ (1,0) [0|0] "-"  CDC,DDM
 SG_ LTCLCSD : 36|1@0+ (1,0) [0|0] "-"  CDC,DDM
 SG_ DM_DISPM : 46|4@0+ (1,0) [0|0] "-"  CDC,DDM
 SG_ DM_BZR : 55|4@0+ (1,0) [0|0] "-"  CDC,DDM
 SG_ LCASGEST : 49|1@0+ (1,0) [0|0] "-"  CDC,DDM
 SG_ LCASGMCS : 48|1@0+ (1,0) [0|0] "-"  CDC,DDM
 SG_ LCAMSG : 63|4@0+ (1,0) [0|0] "-"  CDC,DDM
 SG_ LCASGIND : 59|4@0+ (1,0) [0|0] "-"  CDC,DDM

BO_ 1544 DS11S40: 8 ADC
 SG_ CTAMBG : 18|2@0+ (1,0) [0|0] "-"  BGW,CDC
 SG_ CTAMIDCR : 31|2@0+ (1,0) [0|0] "-"  BGW,CDC
 SG_ CTAMIDCL : 29|2@0+ (1,0) [0|0] "-"  BGW,CDC
 SG_ CTAMIDCA : 27|2@0+ (1,0) [0|0] "-"  BGW,CDC
 SG_ CTAOFFS : 55|2@0+ (1,0) [0|0] "-"  BGW,CDC
 SG_ CTAWDS : 53|2@0+ (1,0) [0|0] "-"  BGW,CDC
 SG_ CTABUZF : 51|2@0+ (1,0) [0|0] "-"  BGW,CDC
 SG_ CTAHR : 63|2@0+ (1,0) [0|0] "-"  BGW,CDC
 SG_ CTAHL : 61|2@0+ (1,0) [0|0] "-"  BGW,CDC
 SG_ CTAUCT : 57|1@0+ (1,0) [0|0] "-"  BGW,CDC

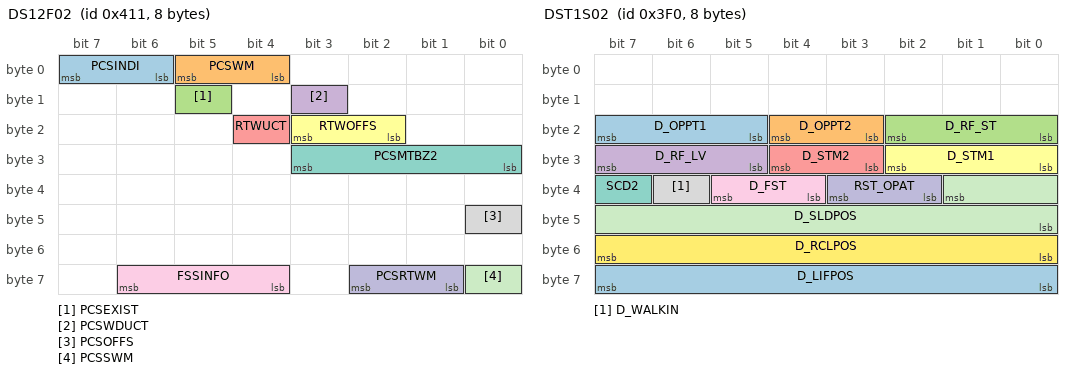
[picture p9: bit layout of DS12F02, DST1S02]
BO_ 1041 DS12F02: 8 ADC
 SG_ PCSINDI : 7|2@0+ (1,0) [0|0] "-"  BGW,CDC
 SG_ PCSWM : 5|2@0+ (1,0) [0|0] "-"  BGW,CDC
 SG_ PCSEXIST : 13|1@0+ (1,0) [0|0] "-"  BGW,CDC
 SG_ PCSWDUCT : 11|1@0+ (1,0) [0|0] "-"  BGW,CDC
 SG_ RTWUCT : 20|1@0+ (1,0) [0|0] "-"  BGW,CDC
 SG_ RTWOFFS : 19|2@0+ (1,0) [0|0] "-"  BGW,CDC
 SG_ PCSMTBZ2 : 27|4@0+ (1,0) [0|0] "-"  BGW,CDC
 SG_ PCSOFFS : 40|1@0+ (1,0) [0|0] "-"  BGW,CDC
 SG_ FSSINFO : 62|3@0+ (1,0) [0|0] "-"  BGW,CDC
 SG_ PCSRTWM : 58|2@0+ (1,0) [0|0] "-"  BGW,CDC
 SG_ PCSSWM : 56|1@0+ (1,0) [0|0] "-"  BGW,CDC

BO_ 1042 DS12F03: 8 ADC
 SG_ LDAINDI : 7|4@0+ (1,0) [0|0] "-"  CDC
 SG_ LTAINDI : 3|3@0+ (1,0) [0|0] "-"  CDC
 SG_ LDAMSG : 15|4@0+ (1,0) [0|0] "-"  CDC
 SG_ LTAMSG : 11|4@0+ (1,0) [0|0] "-"  CDC
 SG_ CSFBUZ : 22|1@0+ (1,0) [0|0] "-"  CDC
 SG_ LDWBUZ : 21|2@0+ (1,0) [0|0] "-"  CDC
 SG_ LKACB : 18|1@0+ (1,0) [0|0] "-"  CDC
 SG_ SWSBUZ : 17|2@0+ (1,0) [0|0] "-"  CDC
 SG_ LKAWLSL : 30|3@0+ (1,0) [0|0] "-"  CDC
 SG_ LKAWLSR : 26|3@0+ (1,0) [0|0] "-"  CDC
 SG_ SWSRAD : 39|2@0+ (1,0) [0|0] "-"  CDC
 SG_ LTAEXIST : 47|1@0+ (1,0) [0|0] "-"  CDC
 SG_ LDAEXIST : 46|1@0+ (1,0) [0|0] "-"  CDC
 SG_ LKAWTCS : 45|2@0+ (1,0) [0|0] "-"  CDC
 SG_ SWSSWD : 43|1@0+ (1,0) [0|0] "-"  CDC
 SG_ LDWEXIST : 42|1@0+ (1,0) [0|0] "-"  CDC
 SG_ LDACS : 41|1@0+ (1,0) [0|0] "-"  CDC
 SG_ VIBEXIST : 55|1@0+ (1,0) [0|0] "-"  CDC
 SG_ LDACD : 54|3@0+ (1,0) [0|0] "-"  CDC
 SG_ LTABZR : 51|2@0+ (1,0) [0|0] "-"  CDC
 SG_ SWSEXIST : 49|1@0+ (1,0) [0|0] "-"  CDC
 SG_ LDWTEXT : 48|1@0+ (1,0) [0|0] "-"  CDC
 SG_ LDAAMEX : 63|1@0+ (1,0) [0|0] "-"  CDC
 SG_ LDAAMST : 62|3@0+ (1,0) [0|0] "-"  CDC
 SG_ VSDGCONT : 59|1@0+ (1,0) [0|0] "-"  CDC
 SG_ VSDGONST : 58|1@0+ (1,0) [0|0] "-"  CDC
 SG_ VUSMONST : 56|1@0+ (1,0) [0|0] "-"  CDC

BO_ 1008 DST1S02: 8 BDL
 SG_ D_OPPT1 : 23|3@0+ (1,0) [0|0] "-"  CDC
 SG_ D_OPPT2 : 20|2@0+ (1,0) [0|0] "-"  CDC
 SG_ D_RF_ST : 18|3@0+ (1,0) [0|0] "-"  CDC
 SG_ D_RF_LV : 31|3@0+ (1,0) [0|0] "-"  CDC
 SG_ D_STM2 : 28|2@0+ (1,0) [0|0] "-"  CDC
 SG_ D_STM1 : 26|3@0+ (1,0) [0|0] "-"  CDC
 SG_ SCD2 : 39|1@0+ (1,0) [0|0] "-"  CDC
 SG_ D_WALKIN : 38|1@0+ (1,0) [0|0] "-"  CDC
 SG_ D_FST : 37|2@0+ (1,0) [0|0] "-"  CDC
 SG_ RST_OPAT : 35|2@0+ (1,0) [0|0] "-"  CDC
 SG_ D_SLDPOS : 33|10@0+ (1,0) [0|0] "mm"  CDC
 SG_ D_RCLPOS : 55|8@0+ (0.5,0) [0|0] "deg"  CDC
 SG_ D_LIFPOS : 63|8@0+ (1,0) [0|0] "mm"  CDC

BO_ 1184 EBU1D01: 32 DDM
 SG_ DREBUID : 7|8@0+ (1,0) [0|0] "-"  CDC
 SG_ DREBU02 : 15|8@0+ (1,0) [0|0] "-"  CDC
 SG_ DREBU03 : 23|8@0+ (1,0) [0|0] "-"  CDC
 SG_ DREBU04 : 31|8@0+ (1,0) [0|0] "-"  CDC
 SG_ DREBU05 : 39|8@0+ (1,0) [0|0] "-"  CDC
 SG_ DREBU06 : 47|8@0+ (1,0) [0|0] "-"  CDC
 SG_ DREBU07 : 55|8@0+ (1,0) [0|0] "-"  CDC
 SG_ DREBU08 : 63|8@0+ (1,0) [0|0] "-"  CDC
 SG_ DREBU11 : 71|8@0+ (1,0) [0|0] "-"  CDC
 SG_ DREBU12 : 79|8@0+ (1,0) [0|0] "-"  CDC
 SG_ DREBU13 : 87|8@0+ (1,0) [0|0] "-"  CDC
 SG_ DREBU14 : 95|8@0+ (1,0) [0|0] "-"  CDC
 SG_ DREBU15 : 103|8@0+ (1,0) [0|0] "-"  CDC
 SG_ DREBU16 : 111|8@0+ (1,0) [0|0] "-"  CDC
 SG_ DREBU17 : 119|8@0+ (1,0) [0|0] "-"  CDC
 SG_ DREBU18 : 127|8@0+ (1,0) [0|0] "-"  CDC
 SG_ DREBU21 : 135|8@0+ (1,0) [0|0] "-"  CDC
 SG_ DREBU22 : 143|8@0+ (1,0) [0|0] "-"  CDC
 SG_ DREBU23 : 151|8@0+ (1,0) [0|0] "-"  CDC
 SG_ DREBU24 : 159|8@0+ (1,0) [0|0] "-"  CDC
 SG_ DREBU25 : 167|8@0+ (1,0) [0|0] "-"  CDC
 SG_ DREBU26 : 175|8@0+ (1,0) [0|0] "-"  CDC
 SG_ DREBU27 : 183|8@0+ (1,0) [0|0] "-"  CDC
 SG_ DREBU28 : 191|8@0+ (1,0) [0|0] "-"  CDC
 SG_ DREBU31 : 199|8@0+ (1,0) [0|0] "-"  CDC
 SG_ DREBU32 : 207|8@0+ (1,0) [0|0] "-"  CDC
 SG_ DREBU33 : 215|8@0+ (1,0) [0|0] "-"  CDC
 SG_ DREBU34 : 223|8@0+ (1,0) [0|0] "-"  CDC
 SG_ DREBU35 : 231|8@0+ (1,0) [0|0] "-"  CDC
 SG_ DREBU36 : 239|8@0+ (1,0) [0|0] "-"  CDC
 SG_ DREBU37 : 247|8@0+ (1,0) [0|0] "-"  CDC
 SG_ DREBU38 : 255|8@0+ (1,0) [0|0] "-"  CDC

BO_ 959 ECT1G01: 32 DDM
 SG_ B_P : 31|1@0+ (1,0) [0|0] "-"  BGW,CDC
 SG_ B_R : 30|1@0+ (1,0) [0|0] "-"  BGW,CDC
 SG_ B_N : 29|1@0+ (1,0) [0|0] "-"  BGW,CDC
 SG_ B_D : 28|1@0+ (1,0) [0|0] "-"  BGW,CDC
 SG_ B_B : 39|1@0+ (1,0) [0|0] "-"  BGW,CDC
 SG_ XFSFT : 37|1@0+ (1,0) [0|0] "-"  BGW,CDC
 SG_ SFTOUT : 45|4@0+ (1,0) [0|0] "-"  BGW,CDC
 SG_ ACT : 41|1@0+ (1,0) [0|0] "-"  BGW,CDC
 SG_ IGP_PT2 : 40|1@0+ (1,0) [0|0] "-"  BGW,CDC

BO_ 1025 ECT1S93: 8 DDM
 SG_ DRDYSTS : 5|2@0+ (1,0) [0|0] "-"  CDC
 SG_ DRDYB : 3|1@0+ (1,0) [0|0] "-"  BDL,BGW,CDC

BO_ 444 EHV1E96: 32 DDM
 SG_ STRGCM : 15|8@0- (32,0) [0|0] "Nm"  CDC

BO_ 296 EHV1G30: 8 DDM
 SG_ BCKLTRQ : 7|1@0+ (1,0) [0|0] "-"  CDC

BO_ 464 EHV1S23: 8 DDM
 SG_ FCRF : 23|1@0+ (1,0) [0|0] "-"  BGW,CDC
 SG_ CLE_SOCF : 22|1@0+ (1,0) [0|0] "-"  BGW,CDC

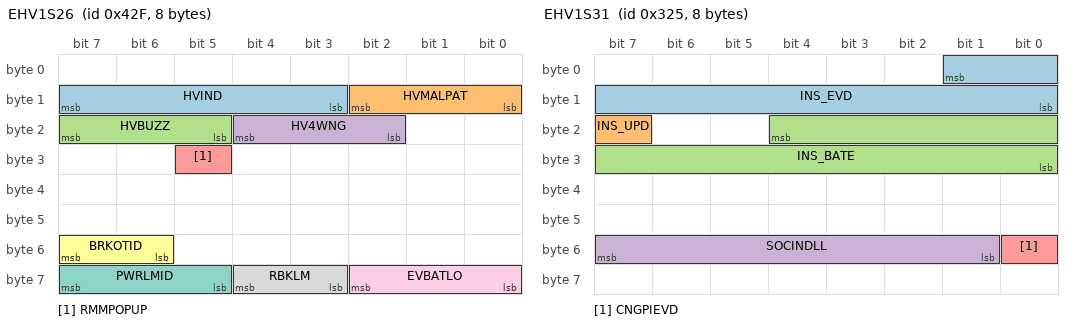
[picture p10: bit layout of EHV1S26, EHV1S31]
BO_ 1071 EHV1S26: 8 DDM
 SG_ HVIND : 15|5@0+ (1,0) [0|0] "-"  BGW,CDC
 SG_ HVMALPAT : 10|3@0+ (1,0) [0|0] "-"  BGW,CDC
 SG_ HVBUZZ : 23|3@0+ (1,0) [0|0] "-"  BGW,CDC
 SG_ HV4WNG : 20|3@0+ (1,0) [0|0] "-"  BGW,CDC
 SG_ RMMPOPUP : 29|1@0+ (1,0) [0|0] "-"  BGW,CDC
 SG_ BRKOTID : 55|2@0+ (1,0) [0|0] "-"  BGW,CDC
 SG_ PWRLMID : 63|3@0+ (1,0) [0|0] "-"  BGW,CDC
 SG_ RBKLM : 60|2@0+ (1,0) [0|0] "-"  BGW,CDC
 SG_ EVBATLO : 58|3@0+ (1,0) [0|0] "-"  BGW,CDC

BO_ 805 EHV1S31: 8 DDM
 SG_ INS_EVD : 1|10@0+ (0.1,0) [0|0] "m"  BGW,CDC
 SG_ INS_UPD : 23|1@0+ (1,0) [0|0] "-"  BGW,CDC
 SG_ INS_BATE : 20|13@0- (0.01,0) [0|0] "Wh"  BGW,CDC
 SG_ SOCINDLL : 55|7@0+ (1,0) [0|0] "%"  BGW,CDC
 SG_ CNGPIEVD : 48|1@0+ (1,0) [0|0] "-"  BGW,CDC

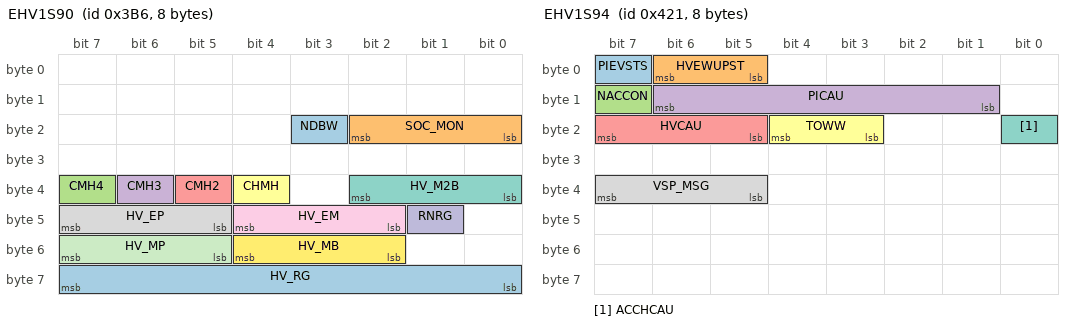
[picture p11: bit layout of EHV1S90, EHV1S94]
BO_ 950 EHV1S90: 8 DDM
 SG_ NDBW : 19|1@0+ (1,0) [0|0] "-"  BGW,CDC
 SG_ SOC_MON : 18|3@0+ (1,0) [0|0] "-"  BGW,CDC
 SG_ CMH4 : 39|1@0+ (1,0) [0|0] "-"  BGW,CDC
 SG_ CMH3 : 38|1@0+ (1,0) [0|0] "-"  BGW,CDC
 SG_ CMH2 : 37|1@0+ (1,0) [0|0] "-"  BGW,CDC
 SG_ CHMH : 36|1@0+ (1,0) [0|0] "-"  BGW,CDC
 SG_ HV_M2B : 34|3@0+ (1,0) [0|0] "-"  BGW,CDC
 SG_ HV_EP : 47|3@0+ (1,0) [0|0] "-"  BGW,CDC
 SG_ HV_EM : 44|3@0+ (1,0) [0|0] "-"  BGW,CDC
 SG_ RNRG : 41|1@0+ (1,0) [0|0] "-"  BGW,CDC
 SG_ HV_MP : 55|3@0+ (1,0) [0|0] "-"  BGW,CDC
 SG_ HV_MB : 52|3@0+ (1,0) [0|0] "-"  BGW,CDC
 SG_ HV_RG : 63|8@0+ (5,0) [0|0] "Wh"  BGW,CDC

BO_ 1057 EHV1S94: 8 DDM
 SG_ PIEVSTS : 7|1@0+ (1,0) [0|0] "-"  BGW,CDC
 SG_ HVEWUPST : 6|2@0+ (1,0) [0|0] "-"  BGW,CDC
 SG_ NACCON : 15|1@0+ (1,0) [0|0] "-"  BGW,CDC
 SG_ PICAU : 14|6@0+ (1,0) [0|0] "-"  BGW,CDC
 SG_ HVCAU : 23|3@0+ (1,0) [0|0] "-"  BGW,CDC
 SG_ TOWW : 20|2@0+ (1,0) [0|0] "-"  BGW,CDC
 SG_ ACCHCAU : 16|1@0+ (1,0) [0|0] "-"  BGW,CDC
 SG_ VSP_MSG : 39|3@0+ (1,0) [0|0] "-"  BGW,CDC

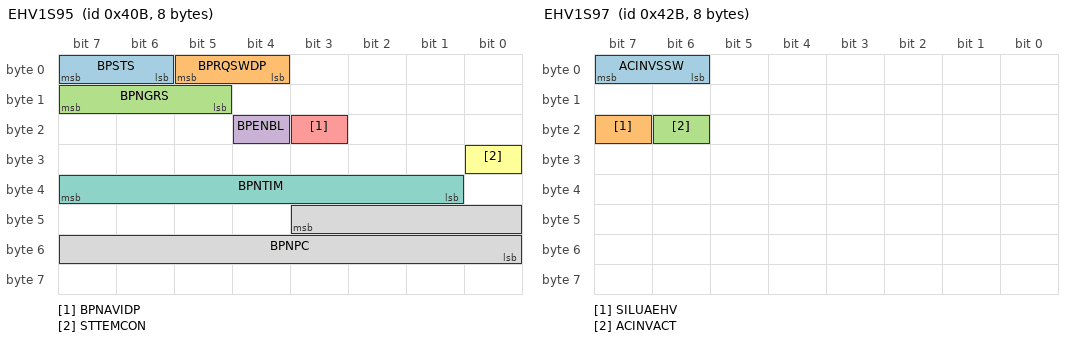
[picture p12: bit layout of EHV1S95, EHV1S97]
BO_ 1035 EHV1S95: 8 DDM
 SG_ BPSTS : 7|2@0+ (1,0) [0|0] "-"  BGW,CDC
 SG_ BPRQSWDP : 5|2@0+ (1,0) [0|0] "-"  BGW,CDC
 SG_ BPNGRS : 15|3@0+ (1,0) [0|0] "-"  BGW,CDC
 SG_ BPENBL : 20|1@0+ (1,0) [0|0] "-"  BGW,CDC
 SG_ BPNAVIDP : 19|1@0+ (1,0) [0|0] "-"  BGW,CDC
 SG_ STTEMCON : 24|1@0+ (1,0) [0|0] "-"  BGW,CDC
 SG_ BPNTIM : 39|7@0+ (1,0) [0|0] "min"  BGW,CDC
 SG_ BPNPC : 43|12@0+ (50,0) [0|0] "Wh"  BGW,CDC

BO_ 506 EHV1S96: 8 DDM
 SG_ RNEC_MON : 7|1@0+ (1,0) [0|0] "-"  CDC
 SG_ EC_MON : 21|14@0- (0.01,0) [0|0] "Wh"  CDC

BO_ 1067 EHV1S97: 8 DDM
 SG_ ACINVSSW : 7|2@0+ (1,0) [0|0] "-"  CDC
 SG_ SILUAEHV : 23|1@0+ (1,0) [0|0] "-"  CDC
 SG_ ACINVACT : 22|1@0+ (1,0) [0|0] "-"  CDC

BO_ 747 EHV1SL2: 8 DDM
 SG_ BTSTS : 15|2@0+ (1,0) [0|0] "-"  BGW,CDC

BO_ 514 EHV2G70: 32 DDM
 SG_ ENECRT1 : 62|7@0+ (1,0) [0|0] "%"  BGW,CDC
 SG_ ENERTEX : 71|1@0+ (1,0) [0|0] "-"  BGW,CDC
 SG_ ENECRT2 : 70|7@0+ (1,0) [0|0] "%"  BGW,CDC
 SG_ ENECRT3 : 79|7@0+ (1,0) [0|0] "%"  BGW,CDC
 SG_ EVDSPEC : 72|9@0+ (0.1,0) [0|0] "km/kWh"  BGW,CDC

BO_ 821 EIM1S01: 8 BDL
 SG_ DREIMABN : 0|1@0+ (1,0) [0|0] "-"  CDC

BO_ 164 ENG1G03: 32 DDM
 SG_ AOR : 7|8@0+ (0.5,0) [0|0] "%"  BGW,CDC
 SG_ HV_ACCP : 15|8@0+ (0.5,0) [0|0] "%"  BGW,CDC

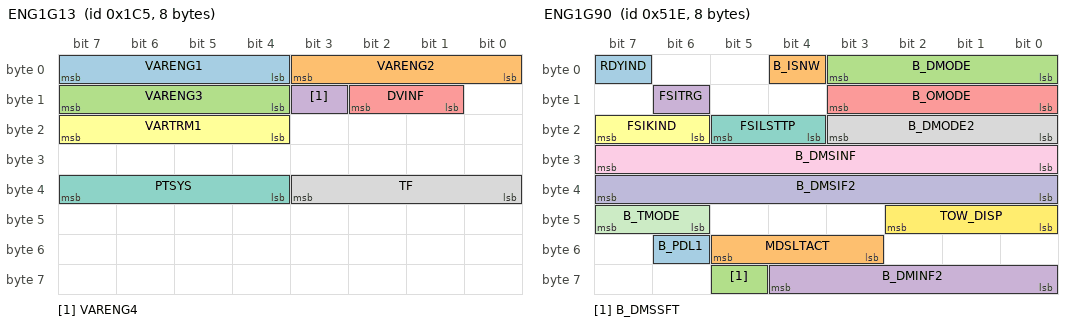
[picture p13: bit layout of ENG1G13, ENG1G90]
BO_ 453 ENG1G13: 8 DDM
 SG_ VARENG1 : 7|4@0+ (1,0) [0|0] "-"  BGW,CDC
 SG_ VARENG2 : 3|4@0+ (1,0) [0|0] "-"  BGW,CDC
 SG_ VARENG3 : 15|4@0+ (1,0) [0|0] "-"  BGW,CDC
 SG_ VARENG4 : 11|1@0+ (1,0) [0|0] "-"  BGW,CDC
 SG_ DVINF : 10|2@0+ (1,0) [0|0] "-"  BDL,BGW,CDC
 SG_ VARTRM1 : 23|4@0+ (1,0) [0|0] "-"  BGW,CDC
 SG_ PTSYS : 39|4@0+ (1,0) [0|0] "-"  BGW,CDC
 SG_ TF : 35|4@0+ (1,0) [0|0] "-"  BGW,CDC

BO_ 1310 ENG1G90: 8 DDM
 SG_ RDYIND : 7|1@0+ (1,0) [0|0] "-"  BGW,CDC
 SG_ B_ISNW : 4|1@0+ (1,0) [0|0] "-"  BDL,BGW,CDC
 SG_ B_DMODE : 3|4@0+ (1,0) [0|0] "-"  BGW,CDC
 SG_ FSITRG : 14|1@0+ (1,0) [0|0] "-"  BDL,BGW,CDC
 SG_ B_OMODE : 11|4@0+ (1,0) [0|0] "-"  BDL,BGW,CDC
 SG_ FSIKIND : 23|2@0+ (1,0) [0|0] "-"  BDL,BGW,CDC
 SG_ FSILSTTP : 21|2@0+ (1,0) [0|0] "-"  BDL,BGW,CDC
 SG_ B_DMODE2 : 19|4@0+ (1,0) [0|0] "-"  BDL,BGW,CDC
 SG_ B_DMSINF : 31|8@0+ (1,0) [0|0] "-"  BDL,BGW,CDC
 SG_ B_DMSIF2 : 39|8@0+ (1,0) [0|0] "-"  BDL,BGW,CDC
 SG_ B_TMODE : 47|2@0+ (1,0) [0|0] "-"  BDL,BGW,CDC
 SG_ TOW_DISP : 42|3@0+ (1,0) [0|0] "-"  BDL,BGW,CDC
 SG_ B_PDL1 : 54|1@0+ (1,0) [0|0] "-"  BDL,BGW,CDC
 SG_ MDSLTACT : 53|3@0+ (1,0) [0|0] "-"  BDL,BGW,CDC
 SG_ B_DMSSFT : 61|1@0+ (1,0) [0|0] "-"  BDL,BGW,CDC
 SG_ B_DMINF2 : 60|5@0+ (1,0) [0|0] "-"  BDL,BGW,CDC

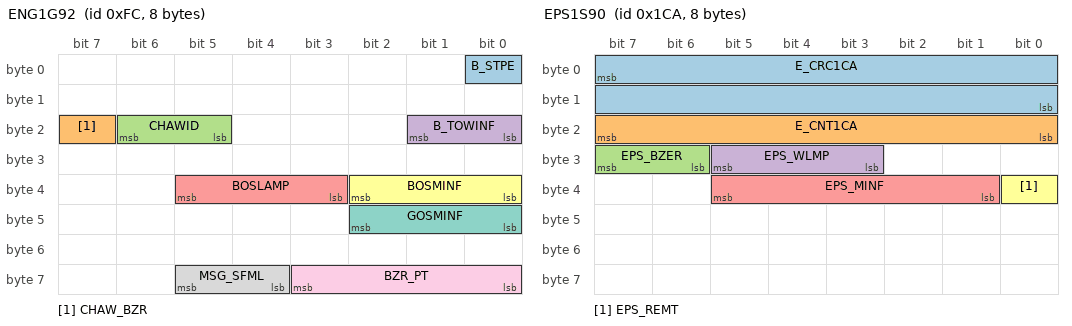
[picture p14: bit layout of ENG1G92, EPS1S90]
BO_ 252 ENG1G92: 8 DDM
 SG_ B_STPE : 0|1@0+ (1,0) [0|0] "-"  BGW,CDC
 SG_ CHAW_BZR : 23|1@0+ (1,0) [0|0] "-"  BGW,CDC
 SG_ CHAWID : 22|2@0+ (1,0) [0|0] "-"  BGW,CDC
 SG_ B_TOWINF : 17|2@0+ (1,0) [0|0] "-"  BGW,CDC
 SG_ BOSLAMP : 37|3@0+ (1,0) [0|0] "-"  BGW,CDC
 SG_ BOSMINF : 34|3@0+ (1,0) [0|0] "-"  BGW,CDC
 SG_ GOSMINF : 42|3@0+ (1,0) [0|0] "-"  BGW,CDC
 SG_ MSG_SFML : 61|2@0+ (1,0) [0|0] "-"  BGW,CDC
 SG_ BZR_PT : 59|4@0+ (1,0) [0|0] "-"  BGW,CDC

BO_ 1426 ENG1S51: 32 DDM
 SG_ VIN_1 : 7|8@0+ (1,0) [0|0] "-"  BGW,CDC
 SG_ VIN_2 : 15|8@0+ (1,0) [0|0] "-"  BGW,CDC
 SG_ VIN_3 : 23|8@0+ (1,0) [0|0] "-"  BGW,CDC
 SG_ VIN_4 : 31|8@0+ (1,0) [0|0] "-"  BGW,CDC
 SG_ VIN_5 : 39|8@0+ (1,0) [0|0] "-"  BGW,CDC
 SG_ VIN_6 : 47|8@0+ (1,0) [0|0] "-"  BGW,CDC
 SG_ VIN_7 : 55|8@0+ (1,0) [0|0] "-"  BGW,CDC
 SG_ VIN_8 : 63|8@0+ (1,0) [0|0] "-"  BGW,CDC
 SG_ VIN_9 : 71|8@0+ (1,0) [0|0] "-"  BGW,CDC
 SG_ VIN_10 : 79|8@0+ (1,0) [0|0] "-"  BGW,CDC
 SG_ VIN_11 : 87|8@0+ (1,0) [0|0] "-"  BGW,CDC
 SG_ VIN_12 : 95|8@0+ (1,0) [0|0] "-"  BGW,CDC
 SG_ VIN_13 : 103|8@0+ (1,0) [0|0] "-"  BGW,CDC
 SG_ VIN_14 : 111|8@0+ (1,0) [0|0] "-"  BGW,CDC
 SG_ VIN_15 : 119|8@0+ (1,0) [0|0] "-"  BGW,CDC
 SG_ VIN_16 : 127|8@0+ (1,0) [0|0] "-"  BGW,CDC
 SG_ VIN_17 : 135|8@0+ (1,0) [0|0] "-"  BGW,CDC

BO_ 98 EPS1S11: 64 DDM
 SG_ TRQSENS : 31|8@0- (0.1,0) [0|0] "Nm"  BGW,CDC
 SG_ ST_TYP : 39|1@0+ (1,0) [0|0] "-"  BGW,CDC
 SG_ PANG : 38|15@0- (0.05,0) [0|0] "deg"  BGW,CDC
 SG_ PANGV : 55|12@0- (1,0) [0|0] "deg/s"  BGW,CDC
 SG_ PANGINV : 59|1@0+ (1,0) [0|0] "-"  BGW,CDC
 SG_ PANGFAIL : 58|1@0+ (1,0) [0|0] "-"  BGW,CDC
 SG_ PANGVS : 84|5@0- (0.03125,0) [0|0] "deg/s"  BGW,CDC
 SG_ TRQSENSS : 111|4@0- (0.01,0) [0|0] "Nm"  BGW,CDC
 SG_ EPSSATGF : 164|1@0+ (1,0) [0|0] "-"  BGW,CDC
 SG_ EPSSATG : 163|12@0- (1.5,0) [0|0] "deg"  BGW,CDC
 SG_ EPSTRQ : 183|16@0- (0.01,0) [0|0] "Nm"  BGW,CDC
 SG_ SANGFAIL : 199|1@0+ (1,0) [0|0] "-"  BGW,CDC
 SG_ SANGINV : 198|1@0+ (1,0) [0|0] "-"  BGW,CDC
 SG_ SANG : 197|14@0- (0.1,0) [0|0] "deg"  BGW,CDC
 SG_ SANGV : 223|12@0- (1,0) [0|0] "deg/s"  BGW,CDC
 SG_ STRDIFF : 225|10@0- (0.1,0) [0|0] "deg"  BGW,CDC

BO_ 458 EPS1S90: 8 DDM
 SG_ E_CRC1CA : 7|16@0+ (1,0) [0|0] "-"  CDC
 SG_ E_CNT1CA : 23|8@0+ (1,0) [0|0] "-"  CDC
 SG_ EPS_BZER : 31|2@0+ (1,0) [0|0] "-"  CDC
 SG_ EPS_WLMP : 29|3@0+ (1,0) [0|0] "-"  CDC
 SG_ EPS_MINF : 37|5@0+ (1,0) [0|0] "-"  CDC
 SG_ EPS_REMT : 32|1@0+ (1,0) [0|0] "-"  CDC

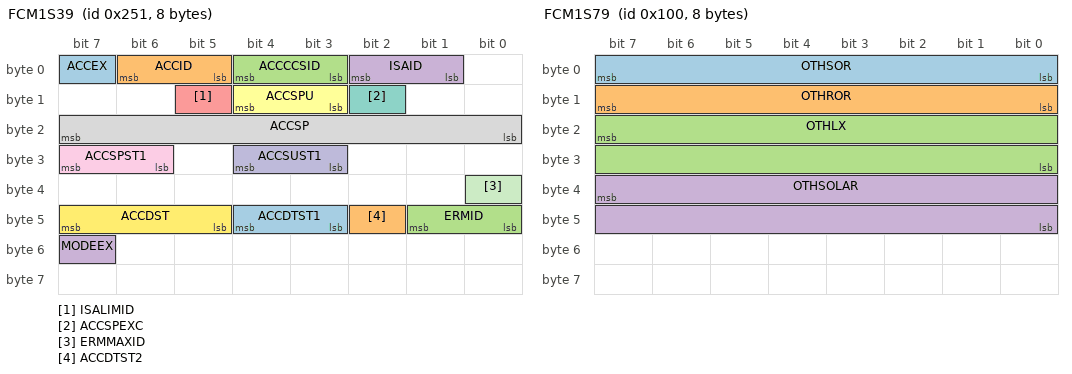
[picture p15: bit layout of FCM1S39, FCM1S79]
BO_ 593 FCM1S39: 8 ADC
 SG_ ACCEX : 7|1@0+ (1,0) [0|0] "-"  BGW,CDC
 SG_ ACCID : 6|2@0+ (1,0) [0|0] "-"  BGW,CDC
 SG_ ACCCCSID : 4|2@0+ (1,0) [0|0] "-"  BGW,CDC
 SG_ ISAID : 2|2@0+ (1,0) [0|0] "-"  BGW,CDC
 SG_ ISALIMID : 13|1@0+ (1,0) [0|0] "-"  BGW,CDC
 SG_ ACCSPU : 12|2@0+ (1,0) [0|0] "-"  BGW,CDC
 SG_ ACCSPEXC : 10|1@0+ (1,0) [0|0] "-"  BGW,CDC
 SG_ ACCSP : 23|8@0+ (1,0) [0|0] "km/h,mph"  BGW,CDC
 SG_ ACCSPST1 : 31|2@0+ (1,0) [0|0] "-"  BGW,CDC
 SG_ ACCSUST1 : 28|2@0+ (1,0) [0|0] "-"  BGW,CDC
 SG_ ERMMAXID : 32|1@0+ (1,0) [0|0] "-"  BGW,CDC
 SG_ ACCDST : 47|3@0+ (1,0) [0|0] "-"  BGW,CDC
 SG_ ACCDTST1 : 44|2@0+ (1,0) [0|0] "-"  BGW,CDC
 SG_ ACCDTST2 : 42|1@0+ (1,0) [0|0] "-"  BGW,CDC
 SG_ ERMID : 41|2@0+ (1,0) [0|0] "-"  BGW,CDC
 SG_ MODEEX : 55|1@0+ (1,0) [0|0] "-"  BGW,CDC

BO_ 602 FCM1S70: 8 ADC
 SG_ OTHAHCON : 7|2@0+ (1,0) [0|0] "-"  CDC
 SG_ OTHINCON : 5|2@0+ (1,0) [0|0] "-"  CDC
 SG_ SRP_PRE : 3|1@0+ (1,0) [0|0] "-"  CDC
 SG_ SRP_IND : 2|1@0+ (1,0) [0|0] "-"  CDC
 SG_ AHSSWVST : 13|1@0+ (1,0) [0|0] "-"  CDC
 SG_ AHSSWVEX : 12|1@0+ (1,0) [0|0] "-"  CDC
 SG_ AHSSDEST : 11|3@0+ (1,0) [0|0] "-"  CDC
 SG_ AHSSDEEX : 8|1@0+ (1,0) [0|0] "-"  CDC
 SG_ A_LMP_ST : 29|2@0+ (1,0) [0|0] "-"  CDC
 SG_ A_HLLI : 27|2@0+ (1,0) [0|0] "-"  CDC
 SG_ A_BW_IND : 25|2@0+ (1,0) [0|0] "-"  CDC
 SG_ A_BW_PRE : 39|1@0+ (1,0) [0|0] "-"  CDC
 SG_ AH_IND_S : 38|3@0+ (1,0) [0|0] "-"  CDC
 SG_ AHSACTST : 35|1@0+ (1,0) [0|0] "-"  CDC
 SG_ AHSACTEX : 34|1@0+ (1,0) [0|0] "-"  CDC
 SG_ AHBACTST : 33|1@0+ (1,0) [0|0] "-"  CDC
 SG_ AHBACTEX : 32|1@0+ (1,0) [0|0] "-"  CDC

BO_ 346 FCM1S78: 8 ADC
 SG_ OTHFRILL : 7|20@0+ (0.04,0) [0|0] "cd/m^2"  CDC

BO_ 256 FCM1S79: 8 ADC
 SG_ OTHSOR : 7|8@0+ (1,0) [0|0] "-"  CDC
 SG_ OTHROR : 15|8@0+ (1,0) [0|0] "-"  CDC
 SG_ OTHLX : 23|16@0+ (1,0) [0|0] "-"  CDC
 SG_ OTHSOLAR : 39|16@0+ (1,0) [0|0] "-"  CDC

BO_ 434 FCM1S90: 32 ADC
 SG_ XREQFPB : 29|1@0+ (1,0) [0|0] "-"  BGW,CDC,DDM
 SG_ XREQPB : 28|1@0+ (1,0) [0|0] "-"  BGW,CDC,DDM
 SG_ XREQPBH : 25|1@0+ (1,0) [0|0] "-"  BGW,CDC,DDM

BO_ 1015 HUD1S01: 8 CDC
 SG_ HUD_ST : 13|3@0+ (1,0) [0|0] "-"  BDL

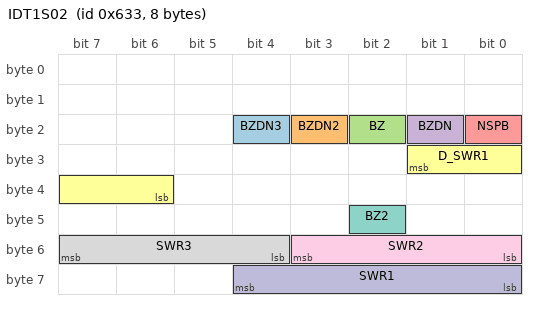
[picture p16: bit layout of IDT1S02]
BO_ 1587 IDT1S02: 8 BDL
 SG_ BZDN3 : 20|1@0+ (1,0) [0|0] "-"  CDC
 SG_ BZDN2 : 19|1@0+ (1,0) [0|0] "-"  CDC
 SG_ BZ : 18|1@0+ (1,0) [0|0] "-"  CDC
 SG_ BZDN : 17|1@0+ (1,0) [0|0] "-"  CDC
 SG_ NSPB : 16|1@0+ (1,0) [0|0] "-"  CDC
 SG_ D_SWR1 : 25|4@0+ (1,0) [0|0] "-"  CDC
 SG_ BZ2 : 42|1@0+ (1,0) [0|0] "-"  CDC
 SG_ SWR3 : 55|4@0+ (1,0) [0|0] "-"  CDC
 SG_ SWR2 : 51|4@0+ (1,0) [0|0] "-"  CDC
 SG_ SWR1 : 60|5@0+ (1,0) [0|0] "-"  CDC

CM_ BO_ 1570 "Reserve";
CM_ SG_ 1570 RSRSENFT "occupant sensor temp-fail";
CM_ SG_ 1570 SULDCD "Smart Unlock Door Change Display";
CM_ SG_ 1570 PANL "Panel lighting request";
CM_ SG_ 1570 LED_HI_B "LED Headlamp Indicator";
CM_ SG_ 1570 DRL "DRL request";
CM_ SG_ 1570 HEDH "High beam head lamp request";
CM_ SG_ 1570 HEDL "Low beam head lamp request";
CM_ SG_ 1570 TAIL "Tail lamp request";
CM_ SG_ 1570 FFOG "Front fog lamp request";
CM_ SG_ 1570 RFOG "Rear fog lamp request";
CM_ SG_ 1570 RSROFFTT "Rear Seat Reminder OFF Tell-Tale";
CM_ SG_ 1570 SB_IND "SmartBeam indicator";
CM_ SG_ 1570 RSRMIDR3 "Rear Seat Reminder MID Request";
CM_ SG_ 1570 RSRMID_R "Rear Seat Reminder MID Request";
CM_ SG_ 1570 RSR_PR "Rear Seat Reminder function presence";
CM_ SG_ 1570 RSRON_ST "Rear Seat Reminder ON/OFF State";
CM_ SG_ 1570 LTOFF_AD "Lighting OFF operation Advisory";
CM_ SG_ 1570 RSRSENFC "occupant sensor fail";
CM_ SG_ 1570 SRWARN "Slide Roof Open Warning Request";
CM_ SG_ 1570 PWWARN "Power Window Open Warning Request";
CM_ SG_ 1570 LTRBZ_R "Light Reminder Buzzer Request";
CM_ BO_ 1571 "Reserve";
CM_ SG_ 1571 MRMV_R "Mirror Move Request";
CM_ SG_ 1571 RSEL "Right outside mirror select SW";
CM_ SG_ 1571 LSEL "Left outside mirror select SW";
CM_ SG_ 1571 MHR "Outside mirror rightward SW";
CM_ SG_ 1571 MHL "Outside mirror leftward SW";
CM_ SG_ 1571 MVU "Outside mirror upward SW";
CM_ SG_ 1571 MVD "Outside mirror downward SW";
CM_ SG_ 1571 GCTY "Glass Hatch Courtesy SW Signal";
CM_ SG_ 1571 WF "Wiper fault signal";
CM_ SG_ 1571 SE_EQ "Swing door E-Latch Equipment";
CM_ SG_ 1571 BSTMID_R "Body System Stop MID Request";
CM_ SG_ 1571 PWOP_ADV "P/W Inoperative Advice";
CM_ BO_ 896 "Reserve";
CM_ SG_ 896 LSWD "Driver's door lock position SW";
CM_ SG_ 896 LSWP "Passenger's door lock position SW";
CM_ SG_ 896 LSWR "Rear right side door lock position SW";
CM_ SG_ 896 LSWL "Rear left side door lock position SW";
CM_ SG_ 896 LSWB "Back door lock position SW";
CM_ SG_ 896 EL_MID "Side door eLatch MID Indication request";
CM_ SG_ 896 LSWT "Trunk lock position SW";
CM_ SG_ 896 PWDRD "Driver's window position";
CM_ SG_ 896 PWDRP "Passenger's window position";
CM_ SG_ 896 PWDRR "Rear right side window Position";
CM_ SG_ 896 PWDRL "Rear left side window position";
CM_ SG_ 896 EL_BZ "Side door eLatch Buzzer sound request";
CM_ SG_ 896 PWD_OPE "Driver's window operation state";
CM_ SG_ 896 PWP_OPE "Passenger's window operation state";
CM_ SG_ 896 PWR_OPE "Rear right side window operation state";
CM_ SG_ 896 PWL_OPE "Rear left side window operation state";
CM_ BO_ 1572 "Reserve";
CM_ SG_ 1572 DEST_BDB "Destination Symbol";
CM_ SG_ 1572 C_CODE1 "Country Code 1st";
CM_ SG_ 1572 C_CODE2 "Country Code 2nd";
CM_ SG_ 1572 C_CODE3 "Country Code 3rd";
CM_ SG_ 1572 STRG_WHL "Steering Wheel";
CM_ SG_ 1572 DVINF_B "Drive train information(C-BEST)";
CM_ BO_ 1574 "Reserve";
CM_ SG_ 1574 IL_FDOME "Front dome illumination light request";
CM_ SG_ 1574 IL_LOUNG "Lounge illumination light request";
CM_ SG_ 1574 IL_OSSTP "Outside underfoot ilumination light request";
CM_ SG_ 1574 AMB_COP "Opening/Ending coordination on-off(BDB)";
CM_ SG_ 1574 SUPRQ "Opening coordination status(BDB)";
CM_ BO_ 1580 "Reserve";
CM_ SG_ 1580 PSREQ1 "Proposal Service Request 1";
CM_ SG_ 1580 PSREQ2 "Proposal Service Request 2";
CM_ SG_ 1580 PSREQ3 "Proposal Service Request 3";
CM_ SG_ 1580 PSREQ4 "Proposal Service Request 4";
CM_ SG_ 1580 PSREQ5 "Proposal Service Request 5";
CM_ SG_ 1580 PSREQ6 "Proposal Service Request 6";
CM_ BO_ 1020 "Reserve";
CM_ SG_ 1020 SOLAR_R "Solar data(R)";
CM_ SG_ 1020 SOLAR_L "Solar data(L)";
CM_ SG_ 1020 N_LX "Illuminance data";
CM_ BO_ 774 "Reserve";
CM_ SG_ 774 B_TID "TableID";
CM_ SG_ 774 B_FUNC1 "BDB_Function1";
CM_ SG_ 774 B_FUNC2 "BDB_Function2";
CM_ SG_ 774 B_FUNC3 "BDB_Function3";
CM_ SG_ 774 B_FUNC4 "BDB_Function4";
CM_ SG_ 774 B_FUNC5 "BDB_Function5";
CM_ SG_ 774 B_FUNC6 "BDB_Function6";
CM_ SG_ 774 B_FUNC7 "BDB_Function7";
CM_ BO_ 773 "Reserve";
CM_ SG_ 773 B_VRRES "Body voice recognition response";
CM_ SG_ 773 OPEINF1 "BDB_OperationInf1";
CM_ SG_ 773 OPEINF2 "BDB_OperationInf2";
CM_ SG_ 773 OPEINF3 "BDB_OperationInf3";
CM_ SG_ 773 OPEINF4 "BDB_OperationInf4";
CM_ SG_ 773 OPEINF5 "BDB_OperationInf5";
CM_ SG_ 773 OPEINF6 "BDB_OperationInf6";
CM_ SG_ 773 OPEINF7 "BDB_OperationInf7";
CM_ BO_ 1577 "Reserve";
CM_ SG_ 1577 PSUN_D "Personal Setting User Number(Driver)";
CM_ SG_ 1577 PSLUN_D "Personal Setting Last User Number(Driver)";
CM_ SG_ 1577 PSDEV_D "Personal Setting Device for identification (Driver)";
CM_ BO_ 1578 "Reserve";
CM_ SG_ 1578 PSEN "Personal Setting Status";
CM_ SG_ 1578 PS_MBR "Presonal Setting Meter Buzzer Request";
CM_ SG_ 1578 PSEU "Personal Setting Erase User";
CM_ SG_ 1578 PSER "Personal Setting Erase Request";
CM_ BO_ 919 "Reserve";
CM_ SG_ 919 WS_NUM "WelcomeScreen_Number";
CM_ SG_ 919 WS_DRVR "WelcomeScreen_Driver";
CM_ SG_ 919 WS_NEXTD "WelcomeScreen_Next Driver";
CM_ SG_ 919 WS_MSG "WelcomeScreen_Message";
CM_ SG_ 919 DP_ST "State of driving position reproducement";
CM_ SG_ 919 NDRV_DET "New driver detection ";
CM_ SG_ 919 REQ_DPSC "Driving position recall proposal screen";
CM_ SG_ 919 PS_NUM "PersonalSettingScreen_Number";
CM_ SG_ 919 PS_DRVR "PersonalSettingScreen_Driver";
CM_ SG_ 919 PS_GO_DS "PersonalSettingScreen_GrayOut_DriverSelect";
CM_ SG_ 919 PS_GO_PD "PersonalSettingScreen_GrayOut_PersonalSmartKeyDevice";
CM_ SG_ 919 PS_GO_FR "PersonalSettingScreen_GrayOut_FaceRecognitionRequest";
CM_ SG_ 919 PS_OD "PersonalSettingScreen_OldDriver";
CM_ SG_ 919 PS_GO_KA "PersonalSettingScreen_GrayOut_KeyAdd";
CM_ SG_ 919 PS_FRR "PersonalSettingScreen_FaceRecognitionRequest";
CM_ SG_ 919 DKY_EXST "Digital key function exist";
CM_ SG_ 919 PS_N_KEY "ScreenInfo : Number of sync key";
CM_ SG_ 919 PS_FRMEM "ScreenInfo : Information of face registration";
CM_ SG_ 919 RESEXERS "Response of execution response of personal identification device registration";
CM_ SG_ 919 DIDEXERS "Device ID of execution response of personal identification device registration";
CM_ SG_ 919 PS_DKLNK "ScreenInfo : Information of digital key link";
CM_ SG_ 919 PS_PDHR "PersonalSettingScreen_PersonalSmartKeyDevice HideRequest";
CM_ SG_ 919 FRTIME "ScreenInfo: State of face registration progress";
CM_ BO_ 949 "Reserve";
CM_ SG_ 949 FILB_S "Front seat/All zone illumination brightness support";
CM_ SG_ 949 FILB_M "Front seat/All zone illumination brightness mode";
CM_ SG_ 949 ACILB_S "Accessory illumination brightness support";
CM_ SG_ 949 ACILB_M "Accessory illumination brightness mode";
CM_ SG_ 949 RILB_S "Rr seat illumination brightness support";
CM_ SG_ 949 RILB_M "Rr seat illumination brightness mode";
CM_ SG_ 949 CEILB_S "Roof illumination brightness support";
CM_ SG_ 949 CEILB_M "Roof illumination brightness mode";
CM_ SG_ 949 FTILB_S "Foot illumination brightness support";
CM_ SG_ 949 FTILB_M "Foot illumination brightness mode";
CM_ SG_ 949 ILBAR_S "Illumination brightness adjusting area support";
CM_ SG_ 949 ILBAR_M "Illumination brightness adjusting area mode";
CM_ SG_ 949 ILTHM_S "Interior illumination theme setting support";
CM_ SG_ 949 ILTHM_M "Interior illumination theme setting mode";
CM_ SG_ 949 EXILB_S "Exterior illumination brightness support";
CM_ SG_ 949 EXILB_M "Exterior illumination brightness mode";
CM_ BO_ 952 "Reserve";
CM_ SG_ 952 ILCUSA_S "Interior illumination customized color setting No1 support";
CM_ SG_ 952 ILCUSA_M "Interior illumination customized color setting No1 mode";
CM_ SG_ 952 WELIL_S "Welcom illumination support";
CM_ SG_ 952 WELIL_M "Welcom illumination mode";
CM_ SG_ 952 DRIIL_S "Drive mode illumination support";
CM_ SG_ 952 DRIIL_M "Drive mode illumination mode";
CM_ SG_ 952 ACIL_S "Air-conditioner cooperation illumination support";
CM_ SG_ 952 ACIL_M "Air-conditioner cooperation illumination mode";
CM_ SG_ 952 TIMEIL_S "Time of the day illumination support";
CM_ SG_ 952 TIMEIL_M "Time of the day illumination mode";
CM_ SG_ 952 ILMAIN_S "Illumination main SW support";
CM_ SG_ 952 ILMAIN_M "Illumination main SW mode";
CM_ SG_ 952 FNIL_S "Forward notifications illumination support";
CM_ SG_ 952 FNIL_M "Forward notifications illumination mode";
CM_ SG_ 952 SEAIL_S "Safe exit assist illumination support";
CM_ SG_ 952 SEAIL_M "Safe exit assist illumination mode";
CM_ SG_ 952 ILLON_NO "Illumination turn-on No for meter linkage";
CM_ SG_ 952 ILLON_F "Illumination turn-on factor for meter linkage";
CM_ BO_ 786 "Reserve";
CM_ SG_ 786 ODO_BECU "Odometer value stored in Backup ECU memory";
CM_ SG_ 786 FV312 "BDC1S13 Freshness Value";
CM_ SG_ 786 KZK312 "BDC1S13 KZKValue";
CM_ BO_ 800 "Reserve";
CM_ SG_ 800 B_RACRES "Remote AC notification type";
CM_ SG_ 800 B_RACTRG "Remote AC notification trigger";
CM_ SG_ 800 B_RACEQP "Remote AC system equipment";
CM_ SG_ 800 B_DPADD "Add button for departure plan";
CM_ SG_ 800 B_DPACTM "Running time setting of HVAC for departure plan";
CM_ SG_ 800 B_DPACMD "Mode setting of HVAC for departure plan";
CM_ SG_ 800 B_DPTMP "Temperature setting for departure plan";
CM_ SG_ 800 B_DPREFR "Fresh and recirculation setting for departure plan";
CM_ SG_ 800 B_DPBLLV "Blower level setting for departure plan";
CM_ SG_ 800 B_DPFDEF "Front defroster setting for departure plan";
CM_ SG_ 800 B_DPRDEF "Rear defogger and mirror heater setting for departure plan";
CM_ SG_ 800 B_DPSH "Steering heater setting for departure plan";
CM_ SG_ 800 B_DPFDHV "Fr Dr seat heater and ventilation setting for departure plan";
CM_ SG_ 800 B_DPFPHV "Fr Pa seat heater and ventilation setting for departure plan";
CM_ SG_ 800 B_DPRDHV "Rr Dr seat heater and ventilation setting for departure plan";
CM_ SG_ 800 B_DPRPHV "Rr Pa seat heater and ventilation setting for departure plan";
CM_ SG_ 800 B_DPFGON "Fragrance ON /OFF for departure plan";
CM_ SG_ 800 B_DPFGCH "Fragrance cartridge type setting for departure plan";
CM_ SG_ 800 B_DPFGLV "Fragrance spray concentration setting for departure plan";
CM_ BO_ 810 "Reserve";
CM_ SG_ 810 B_DPID1 "Setting ID of departure plan 1";
CM_ SG_ 810 B_DPON1 "Enable/disable of departure plan 1";
CM_ SG_ 810 B_DPTYP1 "Type selection of departure plan 1";
CM_ SG_ 810 B_DPDAY1 "Day selection of departure plan 1";
CM_ SG_ 810 B_DPMON1 "Month selection of departure plan 1";
CM_ SG_ 810 B_DPDAT1 "Date selection of departure plan 1";
CM_ SG_ 810 B_DPDTM1 "Departure time of departure plan 1";
CM_ SG_ 810 B_DPAC1 "Enable/disable of AC setting of departure plan 1";
CM_ SG_ 810 B_DPBC1 "Enable/disable of battery conditioning setting of departure plan 1";
CM_ SG_ 810 B_DPID2 "Setting ID of departure plan 2";
CM_ SG_ 810 B_DPON2 "Enable/disable of departure plan 2";
CM_ SG_ 810 B_DPTYP2 "Type selection of departure plan 2";
CM_ SG_ 810 B_DPDAY2 "Day selection of departure plan 2";
CM_ SG_ 810 B_DPMON2 "Month selection of departure plan 2";
CM_ SG_ 810 B_DPDAT2 "Date selection of departure plan 1";
CM_ SG_ 810 B_DPDTM2 "Departure time of departure plan 2";
CM_ SG_ 810 B_DPAC2 "Enable/disable of AC setting of departure plan 2";
CM_ SG_ 810 B_DPBC2 "Enable/disable of battery conditioning setting of departure plan 2";
CM_ SG_ 810 B_DPID3 "Setting ID of departure plan 3";
CM_ SG_ 810 B_DPON3 "Enable/disable of departure plan 3";
CM_ SG_ 810 B_DPTYP3 "Type selection of departure plan 3";
CM_ SG_ 810 B_DPDAY3 "Day selection of departure plan 3";
CM_ SG_ 810 B_DPMON3 "Month selection of departure plan 3";
CM_ SG_ 810 B_DPDAT3 "Date selection of departure plan 1";
CM_ SG_ 810 B_DPDTM3 "Departure time of departure plan 3";
CM_ SG_ 810 B_DPAC3 "Enable/disable of AC setting of departure plan 3";
CM_ SG_ 810 B_DPBC3 "Enable/disable of battery conditioning setting of departure plan 3";
CM_ SG_ 810 B_DPID4 "Setting ID of departure plan 4";
CM_ SG_ 810 B_DPON4 "Enable/disable of departure plan 4";
CM_ SG_ 810 B_DPTYP4 "Type selection of departure plan 4";
CM_ SG_ 810 B_DPDAY4 "Day selection of departure plan 4";
CM_ SG_ 810 B_DPMON4 "Month selection of departure plan 4";
CM_ SG_ 810 B_DPDAT4 "Date selection of departure plan 1";
CM_ SG_ 810 B_DPDTM4 "Departure time of departure plan 4";
CM_ SG_ 810 B_DPAC4 "Enable/disable of AC setting of departure plan 4";
CM_ SG_ 810 B_DPBC4 "Enable/disable of battery conditioning setting of departure plan 4";
CM_ SG_ 810 B_DPID5 "Setting ID of departure plan 5";
CM_ SG_ 810 B_DPON5 "Enable/disable of departure plan 5";
CM_ SG_ 810 B_DPTYP5 "Type selection of departure plan 5";
CM_ SG_ 810 B_DPDAY5 "Day selection of departure plan 5";
CM_ SG_ 810 B_DPMON5 "Month selection of departure plan 5";
CM_ SG_ 810 B_DPDAT5 "Date selection of departure plan 1";
CM_ SG_ 810 B_DPDTM5 "Departure time of departure plan 5";
CM_ SG_ 810 B_DPAC5 "Enable/disable of AC setting of departure plan 5";
CM_ SG_ 810 B_DPBC5 "Enable/disable of battery conditioning setting of departure plan 5";
CM_ SG_ 810 B_DPID6 "Setting ID of departure plan 6";
CM_ SG_ 810 B_DPON6 "Enable/disable of departure plan 6";
CM_ SG_ 810 B_DPTYP6 "Type selection of departure plan 6";
CM_ SG_ 810 B_DPDAY6 "Day selection of departure plan 6";
CM_ SG_ 810 B_DPMON6 "Month selection of departure plan 6";
CM_ SG_ 810 B_DPDAT6 "Date selection of departure plan 1";
CM_ SG_ 810 B_DPDTM6 "Departure time of departure plan 6";
CM_ SG_ 810 B_DPAC6 "Enable/disable of AC setting of departure plan 6";
CM_ SG_ 810 B_DPBC6 "Enable/disable of battery conditioning setting of departure plan 6";
CM_ SG_ 810 B_DPID7 "Setting ID of departure plan 7";
CM_ SG_ 810 B_DPON7 "Enable/disable of departure plan 7";
CM_ SG_ 810 B_DPTYP7 "Type selection of departure plan 7";
CM_ SG_ 810 B_DPDAY7 "Day selection of departure plan 7";
CM_ SG_ 810 B_DPMON7 "Month selection of departure plan 7";
CM_ SG_ 810 B_DPDAT7 "Date selection of departure plan 1";
CM_ SG_ 810 B_DPDTM7 "Departure time of departure plan 7";
CM_ SG_ 810 B_DPAC7 "Enable/disable of AC setting of departure plan 7";
CM_ SG_ 810 B_DPBC7 "Enable/disable of battery conditioning setting of departure plan 7";
CM_ SG_ 810 B_DPTYPN "Next type selection of departure plan";
CM_ SG_ 810 B_DPDAYN "Next day selection of departure plan";
CM_ SG_ 810 B_DPMONN "Next month selection of departure plan";
CM_ SG_ 810 B_DPDATN "Next date selection of departure plan";
CM_ SG_ 810 B_DPDTMN "Next departure time of departure plan";
CM_ SG_ 810 B_DPACN "Enable/disable of next AC setting of departure plan";
CM_ SG_ 810 B_DPBCN "Enable/disable of next battery conditioning setting of departure plan";
CM_ SG_ 810 B_DPACTO "Time-out due to reaching maximum airconditioning system operating time";
CM_ BO_ 892 "Reserve";
CM_ SG_ 892 THEFTD1 "Theft Detection 1";
CM_ SG_ 892 THEFTD2 "Theft Detection 2";
CM_ BO_ 320 "Reserve";
CM_ SG_ 320 MTNLS_L "Flashing Synchronized Signal of Turn Lamp (Left)";
CM_ SG_ 320 MTNLS_R "Flashing Synchronized Signal of Turn Lamp (Right)";
CM_ BO_ 390 "Reserve";
CM_ SG_ 390 DSADSTX "Driver Side Electric register air direction status signal(X)";
CM_ SG_ 390 DSADSTY "Driver Side Electric register air direction status signal(Y)";
CM_ SG_ 390 DSADFNX "Driver Side Electric register air direction availability of function  signal(X)";
CM_ SG_ 390 DSADFNY "Driver Side Electric register air direction availability of function  signal(Y)";
CM_ SG_ 390 DSADOPX "Driver Side Electric register availability of air direction operation signal(X)";
CM_ SG_ 390 DSADOPY "Driver Side Electric register availability of air direction operation signal(Y)";
CM_ SG_ 390 DSSHTST "Driver Side Electric register shut status signal";
CM_ SG_ 390 DSSHTFN "Driver Side Electric register availability of shut function signal";
CM_ SG_ 390 DSSHTOP "Driver Side Electric register availability of shut operation signal";
CM_ SG_ 390 DSSWGST "Driver Side Electric register swing status signal";
CM_ SG_ 390 DSSWGFN "Driver Side Electric register availability of swing function signal";
CM_ SG_ 390 DSSWGOP "Driver Side Electric register availability of swing operation signal";
CM_ SG_ 390 DSARFST "Driver Side Electric register state of air flow signal";
CM_ SG_ 390 DCADSTX "Driver Center Electric register air direction status signal(X)";
CM_ SG_ 390 DCADSTY "Drive Center Electric register air direction status signal(Y)";
CM_ SG_ 390 DCADFNX "Driver Center Electric register air direction availability of function  signal(X)";
CM_ SG_ 390 DCADFNY "Driver Center Electric register air direction availability of function  signal(Y)";
CM_ SG_ 390 DCADOPX "Driver Center Electric register availability of air direction operation signal(X)";
CM_ SG_ 390 DCADOPY "Driver Center Electric register availability of air direction operation signal(Y)";
CM_ SG_ 390 DCSHTST "Driver Center Electric register shut status signal";
CM_ SG_ 390 DCSHTFN "Driver Center Electric register availability of shut function signal";
CM_ SG_ 390 DCSHTOP "Driver Center Electric register availability of shut operation signal";
CM_ SG_ 390 DCSWGST "Driver Center Electric register swing status signal";
CM_ SG_ 390 DCSWGFN "Driver Center Electric register availability of swing function signal";
CM_ SG_ 390 DCSWGOP "Driver Center Electric register availability of swing operation signal";
CM_ SG_ 390 DCARFST "Driver Center Electric register state of air flow signal";
CM_ SG_ 390 PSADSTX "Passenger Side Electric register air direction status signal(X)";
CM_ SG_ 390 PSADSTY "Passenger Side Electric register air direction status signal(Y)";
CM_ SG_ 390 PSADFNX "Passenger Side Electric register air direction availability of function  signal(X)";
CM_ SG_ 390 PSADFNY "Passenger Side Electric register air direction availability of function  signal(Y)";
CM_ SG_ 390 PSADOPX "Passenger Side Electric register availability of air direction operation signal(X)";
CM_ SG_ 390 PSADOPY "Passenger Side Electric register availability of air direction operation signal(Y)";
CM_ SG_ 390 PSSHTST "Passenger Side Electric register shut status signal";
CM_ SG_ 390 PSSHTFN "Passenger Side Electric register availability of shut function signal";
CM_ SG_ 390 PSSHTOP "Passenger Side Electric register availability of shut operation signal";
CM_ SG_ 390 PSSWGST "Passenger Side Electric register swing status signal";
CM_ SG_ 390 PSSWGFN "Passenger Side Electric register availability of swing function signal";
CM_ SG_ 390 PSSWGOP "Passenger Side Electric register availability of swing operation signal";
CM_ SG_ 390 PSARFST "Passenger Side Electric register state of air flow signal";
CM_ SG_ 390 PCADSTX "Passenger Center Electric register air direction status signal(X)";
CM_ SG_ 390 PCADSTY "Passenger Center Electric register air direction status signal(Y)";
CM_ SG_ 390 PCADFNX "Passenger Center Electric register air direction availability of function  signal(X)";
CM_ SG_ 390 PCADFNY "Passenger Center Electric register air direction availability of function  signal(Y)";
CM_ SG_ 390 PCADOPX "Passenger Center Electric register availability of air direction operation signal(X)";
CM_ SG_ 390 PCADOPY "Passenger Center Electric register availability of air direction operation signal(Y)";
CM_ SG_ 390 PCSHTST "Passenger Center Electric register shut status signal";
CM_ SG_ 390 PCSHTFN "Passenger Center Electric register availability of shut function signal";
CM_ SG_ 390 PCSHTOP "Passenger Center Electric register availability of shut operation signal";
CM_ SG_ 390 PCSWGST "Passenger Center Electric register swing status signal";
CM_ SG_ 390 PCSWGFN "Passenger Center Electric register availability of swing function signal";
CM_ SG_ 390 PCSWGOP "Passenger Center Electric register availability of swing operation signal";
CM_ SG_ 390 PCARFST "Passenger Center Electric register state of air flow signal";
CM_ SG_ 390 RRCADSTX "RR Center Electric register air direction status signal(X)";
CM_ SG_ 390 RRCADSTY "RR Center Electric register air direction status signal(Y)";
CM_ SG_ 390 RRCADFNX "RR Center Electric register air direction availability of function  signal(X)";
CM_ SG_ 390 RRCADFNY "RR Center Electric register air direction availability of function  signal(Y)";
CM_ SG_ 390 RRCADOPX "RR Center Electric register availability of air direction operation signal(X)";
CM_ SG_ 390 RRCADOPY "RR Center Electric register availability of air direction operation signal(Y)";
CM_ SG_ 390 RRCSHTST "RR Center Electric register shut status signal";
CM_ SG_ 390 RRCSHTFN "RR Center Electric register availability of shut function signal";
CM_ SG_ 390 RRCSHTOP "RR Center Electric register availability of shut operation signal";
CM_ SG_ 390 RRCSWGST "RR Center Electric register swing status signal";
CM_ SG_ 390 RRCSWGFN "RR Center Electric register availability of swing function signal";
CM_ SG_ 390 RRCSWGOP "RR Center Electric register availability of swing operation signal";
CM_ SG_ 390 RRCARFST "RR center Electric register state of air flow signal";
CM_ SG_ 390 RLCADSTX "RL Center Electric register air direction status signal(X)";
CM_ SG_ 390 RLCADSTY "RL Center Electric register air direction status signal(Y)";
CM_ SG_ 390 RLCADFNX "RL Center Electric register air direction availability of function  signal(X)";
CM_ SG_ 390 RLCADFNY "RL Center Electric register air direction availability of function  signal(Y)";
CM_ SG_ 390 RLCADOPX "RL Center Electric register availability of air direction operation signal(X)";
CM_ SG_ 390 RLCADOPY "RL Center Electric register availability of air direction operation signal(Y)";
CM_ SG_ 390 RLCSHTST "RL Center Electric register shut status signal";
CM_ SG_ 390 RLCSHTFN "RL Center Electric register availability of shut function signal";
CM_ SG_ 390 RLCSHTOP "RL Center Electric register availability of shut operation signal";
CM_ SG_ 390 RLCSWGST "RL Center Electric register swing status signal";
CM_ SG_ 390 RLCSWGFN "RL Center Electric register availability of swing function signal";
CM_ SG_ 390 RLCSWGOP "RL Center Electric register availability of swing operation signal";
CM_ SG_ 390 RLCARFST "RL center Electric register state of air flow signal";
CM_ SG_ 390 SWNSWFNP "Electric register availability of swing SW function signal for Passenger seat";
CM_ SG_ 390 SWNSWOPP "Electric register availability of swing SW operation  signal for Passenger seat";
CM_ SG_ 390 SWNSWSTP "Electric register swing SW status  signal for Passenger seat";
CM_ SG_ 390 SWNSWFND "Electric register availability of swing SW function signal for Driver seat";
CM_ SG_ 390 SWNSWOPD "Electric register availability of swing SW operation  signal for Driver seat";
CM_ SG_ 390 SWNSWSTD "Electric register swing SW status  signal for Driver seat";
CM_ SG_ 390 BLMDCMFN "Electric register availability of blow mode customization SW function signal";
CM_ SG_ 390 BLMDCMOP "Electric register availability of blow mode customization SW operation  signal";
CM_ SG_ 390 BLMDCMST "Electric register state of blow mode customization SW  signal";
CM_ SG_ 390 DSPADFN "Driver Side Electric register availability of air direction indication of parts signal";
CM_ SG_ 390 DSPADOP "Driver Side Electric register availability of air direction indication of parts signal";
CM_ SG_ 390 DCPADFN "Driver Center Electric register availability of air direction indication of parts signal";
CM_ SG_ 390 DCPADOP "Driver Center Electric register availability of air direction indication of parts signal";
CM_ SG_ 390 PSPADFN "Passenger Side Electric register availability of air direction indication of parts signal";
CM_ SG_ 390 PSPADOP "Passenger Side Electric register availability of air direction indication of parts signal";
CM_ SG_ 390 PCPADFN "Passenger Center Electric register availability of air direction indication of parts signal";
CM_ SG_ 390 PCPADOP "Passenger Center Electric register availability of air direction indication of parts signal";
CM_ SG_ 390 RRCPADFN "RR Center Electric register availability of air direction indication of parts signal";
CM_ SG_ 390 RRCPADOP "RR Center Electric register availability of air direction indication of parts signal";
CM_ SG_ 390 RLCPADFN "RL Center Electric register availability of air direction indication of parts signal";
CM_ SG_ 390 RLCPADOP "RL Center Electric register availability of air direction indication of parts signal";
CM_ SG_ 390 SPTSWFNP "Electric register availability of spot SW function signal for  Passenger seat";
CM_ SG_ 390 SPTSWOPP "Electric register availability of spot SW operation  signal for Passenger seat";
CM_ SG_ 390 SPTSWSTP "Electric register spot SW status  signal for Passenger seat";
CM_ SG_ 390 SPTSWFND "Electric register availability of spot SW function signal for Driver seat";
CM_ SG_ 390 SPTSWOPD "Electric register availability of spot SW operation  signal for Driver seat";
CM_ SG_ 390 SPTSWSTD "Electric register spot SW status  signal for Driver seat";
CM_ SG_ 390 SPRSWFNP "Electric register availability of spread SW function signal for  Passengerseat";
CM_ SG_ 390 SPRSWOPP "Electric register availability of spread SW operation  signal for Passenger seat";
CM_ SG_ 390 SPRSWSTP "Electric register spread SW status  signal for Passenger seat";
CM_ SG_ 390 SPRSWFND "Electric register availability of spread SW function signal for Driver seat";
CM_ SG_ 390 SPRSWOPD "Electric register availability of spread SW operation  signal for Driver seat";
CM_ SG_ 390 SPRSWSTD "Electric register spread SW status  signal for Driver seat";
CM_ BO_ 466 "Reserve";
CM_ SG_ 466 TVPSOFF "Twelve Volt Power Supply OFF";
CM_ SG_ 466 APSCJDSA "auxiliary power supply control judgment result to service apps";
CM_ BO_ 328 "Reserve";
CM_ SG_ 328 AXSOC "AXSOC";
CM_ BO_ 868 "Reserve";
CM_ SG_ 868 SLB_VLWF "Accessory performance degradation";
CM_ BO_ 467 "Reserve";
CM_ SG_ 467 PDS_BUZ "Fallback driving Buzzer sound request";
CM_ SG_ 467 PDS_DISP "Fallback driving Display Indication request";
CM_ BO_ 823 "Reserve";
CM_ SG_ 823 PS_GO_DD "ScreenInfo: GrayOut_DeleteDriver";
CM_ SG_ 823 PS_GO_DK "ScreenInfo: GrayOut_LinkDigitalKey";
CM_ SG_ 823 FRRSTBDB "Face register execution result (BDB)";
CM_ SG_ 823 DISPMODE "Personal identification display mode";
CM_ SG_ 823 PS_PD "ScreenInfo: LinkKey";
CM_ SG_ 823 PS_GO_ND "ScreenInfo: GrayOut_AcceptNewDriver";
CM_ SG_ 823 MRMAINSW "My Room Mode Main Switch Display Request";
CM_ SG_ 823 MRSOCANS "My Room Mode SOC Select Answer";
CM_ SG_ 823 MRSOCMIN "My Room Mode Min Flag";
CM_ SG_ 823 MRRUN "My Room Mode Running Notice Request";
CM_ SG_ 823 MREXITF "My Room Mode Exit Factor Notice";
CM_ BO_ 19 "Reserve";
CM_ SG_ 19 KZKSEND1 "Data #1 for Distribution";
CM_ SG_ 19 KZKSEND2 "Data #2 for Distribution";
CM_ SG_ 19 KZKSEND3 "Data #3 for Distribution";
CM_ SG_ 19 KZKSEND4 "Data #4 for Distribution";
CM_ SG_ 19 KZKSEND5 "Data #5 for Distribution";
CM_ SG_ 19 KZKSEND6 "Data #6 for Distribution";
CM_ SG_ 19 KZKSEND7 "Data #7 for Distribution";
CM_ SG_ 19 KZKSEND8 "Data #8 for Distribution";
CM_ BO_ 27 "Reserve";
CM_ SG_ 27 KZKID "KZK ID";
CM_ SG_ 27 KZKUSAGE "KZK usage";
CM_ SG_ 27 KZKVERI1 "Data #1 for Verification";
CM_ SG_ 27 KZKVERI2 "Data #2 for Verification";
CM_ SG_ 27 KZKVERI3 "Data #3 for Verification";
CM_ SG_ 27 KZKVERI4 "Data #4 for Verification";
CM_ BO_ 833 "Reserve";
CM_ SG_ 833 POW_ADV "Power status notification";
CM_ BO_ 483 "Reserve";
CM_ SG_ 483 VPSINFO7 "ParkingHighVoltageAndHeatConditioning";
CM_ SG_ 483 VPSINFO6 "ParkingHighVoltage";
CM_ SG_ 483 VPSINFO5 "PowerOnEmergency";
CM_ SG_ 483 VPSINFO4 "PowerOnNormal";
CM_ SG_ 483 VPSINFO3 "Riding";
CM_ SG_ 483 VPSINFO2 "Parking";
CM_ SG_ 483 VPSINFO1 "Checking";
CM_ SG_ 483 VPSINFOS "Vehicle power state";
CM_ SG_ 483 VPSISOTA "Vehicle Power state OTA Special state.";
CM_ SG_ 483 APOFRQ "AppearanceOFF  Control Request";
CM_ BO_ 871 "Reserve";
CM_ SG_ 871 PWRSVSET "PowerSave Set";
CM_ SG_ 871 PWRSVSOC "PowerSave SOC";
CM_ BO_ 853 "Reserve";
CM_ SG_ 853 PWCRTRT1 "Power Controlre result for individual ECU.";
CM_ SG_ 853 PWCRTMD1 "Result Power ON/OFF";
CM_ SG_ 853 PWCRTID1 "Result the Power ON/OFF request ID for individual ECU.";
CM_ BO_ 856 "Reserve";
CM_ SG_ 856 PWCRTRT2 "Power Controlre result for individual ECU.";
CM_ SG_ 856 PWCRTMD2 "Result Power ON/OFF";
CM_ SG_ 856 PWCRTID2 "Result the Power ON/OFF request ID for individual ECU.";
CM_ BO_ 861 "Reserve";
CM_ SG_ 861 SBCGOTA "Charge state for sub-Li Battery. (include reasons for failure)";
CM_ SG_ 861 PWLVOTA "Power Level is OTA enable/disable";
CM_ SG_ 861 PWCRTRT3 "Power Controlre result for individual ECU.";
CM_ SG_ 861 PWCRTMD3 "Result Power ON/OFF";
CM_ SG_ 861 PWCRTID3 "Result the Power ON/OFF request ID for individual ECU.";
CM_ SG_ 861 RDYOF_ST "Vehicle Power Ready ON disable state";
CM_ BO_ 420 "Reserve";
CM_ SG_ 420 PROTREQ "Protect request";
CM_ SG_ 420 CYCLCREQ "Cyclic record request";
CM_ SG_ 420 DRWUREQ2 "Wakeup request 2";
CM_ SG_ 420 RMSETREQ "Remote setting request";
CM_ SG_ 420 STRMREQ "Steaming request";
CM_ SG_ 420 STATREQ "Status request";
CM_ BO_ 863 "Reserve";
CM_ SG_ 863 PAD_EQ2 "Parking approach detection equipment";
CM_ SG_ 863 BSET_PAD "BDC setting for parking approach detection";
CM_ SG_ 863 BSET_PG "BDC setting for parking impact detection ";
CM_ SG_ 863 HLACK "Head lamp request ack";
CM_ SG_ 863 DRBDCABN "Drive recorder BDC abnormal";
CM_ SG_ 863 DRGABN "Drive recorder G sensor wiring abnormal";
CM_ SG_ 863 DRGOFF "Drive recorder G sensor off request";
CM_ BO_ 915 "Reserve";
CM_ SG_ 915 BDOACK01 "Upper Body Manager Operation01 ACK";
CM_ SG_ 915 BDOACK02 "Upper Body Manager Operation02 ACK";
CM_ SG_ 915 BDOACK03 "Upper Body Manager Operation03 ACK";
CM_ SG_ 915 BDOACK04 "Upper Body Manager Operation04 ACK";
CM_ SG_ 915 BDOACK05 "Upper Body Manager Operation05 ACK";
CM_ SG_ 915 BDOACK06 "Upper Body Manager Operation06 ACK";
CM_ SG_ 915 BDOACK07 "Upper Body Manager Operation07 ACK";
CM_ SG_ 915 BDOACK08 "Upper Body Manager Operation08 ACK";
CM_ SG_ 915 BDOACK09 "Upper Body Manager Operation09 ACK";
CM_ SG_ 915 BDOACK10 "Upper Body Manager Operation10 ACK";
CM_ SG_ 915 BDOACK11 "Upper Body Manager Operation11 ACK";
CM_ SG_ 915 BDOACK12 "Upper Body Manager Operation12 ACK";
CM_ SG_ 915 BDOACRSV "reserve";
CM_ SG_ 915 FV393 "Freshness Value";
CM_ SG_ 915 KZK393 "KZKValue";
CM_ BO_ 917 "Reserve";
CM_ SG_ 917 UMASIF01 "Upper Manager IF_ID";
CM_ SG_ 917 UMASRQ01 "Request ID";
CM_ SG_ 917 UMASRV01 "reserve";
CM_ SG_ 917 UMASAD01 "Acceptance Data";
CM_ SG_ 917 FV395 "Freshness Value";
CM_ SG_ 917 KZK395 "KZKValue";
CM_ BO_ 918 "Reserve";
CM_ SG_ 918 UMASIF02 "Upper Manager IF_ID";
CM_ SG_ 918 UMASRQ02 "Request ID";
CM_ SG_ 918 UMASRV02 "reserve";
CM_ SG_ 918 UMASAD02 "Acceptance Data";
CM_ SG_ 918 FV396 "Freshness Value";
CM_ SG_ 918 KZK396 "KZKValue";
CM_ BO_ 922 "Reserve";
CM_ SG_ 922 UMASIF03 "Upper Manager IF_ID";
CM_ SG_ 922 UMASRQ03 "Request ID";
CM_ SG_ 922 UMASRV03 "reserve";
CM_ SG_ 922 UMASAD03 "Acceptance Data";
CM_ SG_ 922 FV39A "Freshness Value";
CM_ SG_ 922 KZK39A "KZKValue";
CM_ BO_ 923 "Reserve";
CM_ SG_ 923 UMASIF04 "Upper Manager IF_ID";
CM_ SG_ 923 UMASRQ04 "Request ID";
CM_ SG_ 923 UMASRV04 "reserve";
CM_ SG_ 923 UMASAD04 "Acceptance Data";
CM_ SG_ 923 FV39B "Freshness Value";
CM_ SG_ 923 KZK39B "KZKValue";
CM_ BO_ 925 "Reserve";
CM_ SG_ 925 UMASIF05 "Upper Manager IF_ID";
CM_ SG_ 925 UMASRQ05 "Request ID";
CM_ SG_ 925 UMASRV05 "reserve";
CM_ SG_ 925 UMASAD05 "Acceptance Data";
CM_ SG_ 925 FV39D "Freshness Value";
CM_ SG_ 925 KZK39D "KZKValue";
CM_ BO_ 926 "Reserve";
CM_ SG_ 926 UMASIF06 "Upper Manager IF_ID";
CM_ SG_ 926 UMASRQ06 "Request ID";
CM_ SG_ 926 UMASRV06 "reserve";
CM_ SG_ 926 UMASAD06 "Acceptance Data";
CM_ SG_ 926 FV39E "Freshness Value";
CM_ SG_ 926 KZK39E "KZKValue";
CM_ BO_ 927 "Reserve";
CM_ SG_ 927 UMASIF07 "Upper Manager IF_ID";
CM_ SG_ 927 UMASRQ07 "Request ID";
CM_ SG_ 927 UMASRV07 "reserve";
CM_ SG_ 927 UMASAD07 "Acceptance Data";
CM_ SG_ 927 FV39F "Freshness Value";
CM_ SG_ 927 KZK39F "KZKValue";
CM_ BO_ 933 "Reserve";
CM_ SG_ 933 UMASIF08 "Upper Manager IF_ID";
CM_ SG_ 933 UMASRQ08 "Request ID";
CM_ SG_ 933 UMASRV08 "reserve";
CM_ SG_ 933 UMASAD08 "Acceptance Data";
CM_ SG_ 933 FV3A5 "Freshness Value";
CM_ SG_ 933 KZK3A5 "KZKValue";
CM_ BO_ 940 "Reserve";
CM_ SG_ 940 UMASIF09 "Upper Manager IF_ID";
CM_ SG_ 940 UMASRQ09 "Request ID";
CM_ SG_ 940 UMASRV09 "reserve";
CM_ SG_ 940 UMASAD09 "Acceptance Data";
CM_ SG_ 940 FV3AC "Freshness Value";
CM_ SG_ 940 KZK3AC "KZKValue";
CM_ BO_ 942 "Reserve";
CM_ SG_ 942 UMASIF10 "Upper Manager IF_ID";
CM_ SG_ 942 UMASRQ10 "Request ID";
CM_ SG_ 942 UMASRV10 "reserve";
CM_ SG_ 942 UMASAD10 "Acceptance Data";
CM_ SG_ 942 FV3AE "Freshness Value";
CM_ SG_ 942 KZK3AE "KZKValue";
CM_ BO_ 946 "Reserve";
CM_ SG_ 946 UMASIF11 "Upper Manager IF_ID";
CM_ SG_ 946 UMASRQ11 "Request ID";
CM_ SG_ 946 UMASRV11 "reserve";
CM_ SG_ 946 UMASAD11 "Acceptance Data";
CM_ SG_ 946 FV3B2 "Freshness Value";
CM_ SG_ 946 KZK3B2 "KZKValue";
CM_ BO_ 947 "Reserve";
CM_ SG_ 947 UMASIF12 "Upper Manager IF_ID";
CM_ SG_ 947 UMASRQ12 "Request ID";
CM_ SG_ 947 UMASRV12 "reserve";
CM_ SG_ 947 UMASAD12 "Acceptance Data";
CM_ SG_ 947 FV3B3 "Freshness Value";
CM_ SG_ 947 KZK3B3 "KZKValue";
CM_ BO_ 953 "Reserve";
CM_ SG_ 953 UMRSIF01 "Upper Manager IF_ID";
CM_ SG_ 953 UMRSRQ01 "Request ID";
CM_ SG_ 953 UMRSRV01 "reserve";
CM_ SG_ 953 UMRSAD01 "Result Data";
CM_ SG_ 953 FV3B9 "Freshness Value";
CM_ SG_ 953 KZK3B9 "KZKValue";
CM_ BO_ 956 "Reserve";
CM_ SG_ 956 UMRSIF02 "Upper Manager IF_ID";
CM_ SG_ 956 UMRSRQ02 "Request ID";
CM_ SG_ 956 UMRSRV02 "reserve";
CM_ SG_ 956 UMRSAD02 "Result Data";
CM_ SG_ 956 FV3BC "Freshness Value";
CM_ SG_ 956 KZK3BC "KZKValue";
CM_ BO_ 966 "Reserve";
CM_ SG_ 966 UMRSIF03 "Upper Manager IF_ID";
CM_ SG_ 966 UMRSRQ03 "Request ID";
CM_ SG_ 966 UMRSRV03 "reserve";
CM_ SG_ 966 UMRSAD03 "Result Data";
CM_ SG_ 966 FV3C6 "Freshness Value";
CM_ SG_ 966 KZK3C6 "KZKValue";
CM_ BO_ 967 "Reserve";
CM_ SG_ 967 UMRSIF04 "Upper Manager IF_ID";
CM_ SG_ 967 UMRSRQ04 "Request ID";
CM_ SG_ 967 UMRSRV04 "reserve";
CM_ SG_ 967 UMRSAD04 "Result Data";
CM_ SG_ 967 FV3C7 "Freshness Value";
CM_ SG_ 967 KZK3C7 "KZKValue";
CM_ BO_ 973 "Reserve";
CM_ SG_ 973 UMRSIF05 "Upper Manager IF_ID";
CM_ SG_ 973 UMRSRQ05 "Request ID";
CM_ SG_ 973 UMRSRV05 "reserve";
CM_ SG_ 973 UMRSAD05 "Result Data";
CM_ SG_ 973 FV3CD "Freshness Value";
CM_ SG_ 973 KZK3CD "KZKValue";
CM_ BO_ 979 "Reserve";
CM_ SG_ 979 UMRSIF06 "Upper Manager IF_ID";
CM_ SG_ 979 UMRSRQ06 "Request ID";
CM_ SG_ 979 UMRSRV06 "reserve";
CM_ SG_ 979 UMRSAD06 "Result Data";
CM_ SG_ 979 FV3D3 "Freshness Value";
CM_ SG_ 979 KZK3D3 "KZKValue";
CM_ BO_ 982 "Reserve";
CM_ SG_ 982 UMRSIF07 "Upper Manager IF_ID";
CM_ SG_ 982 UMRSRQ07 "Request ID";
CM_ SG_ 982 UMRSRV07 "reserve";
CM_ SG_ 982 UMRSAD07 "Result Data";
CM_ SG_ 982 FV3D6 "Freshness Value";
CM_ SG_ 982 KZK3D6 "KZKValue";
CM_ BO_ 989 "Reserve";
CM_ SG_ 989 UMRSIF08 "Upper Manager IF_ID";
CM_ SG_ 989 UMRSRQ08 "Request ID";
CM_ SG_ 989 UMRSRV08 "reserve";
CM_ SG_ 989 UMRSAD08 "Result Data";
CM_ SG_ 989 FV3DD "Freshness Value";
CM_ SG_ 989 KZK3DD "KZKValue";
CM_ BO_ 993 "Reserve";
CM_ SG_ 993 UMRSIF09 "Upper Manager IF_ID";
CM_ SG_ 993 UMRSRQ09 "Request ID";
CM_ SG_ 993 UMRSRV09 "reserve";
CM_ SG_ 993 UMRSAD09 "Result Data";
CM_ SG_ 993 FV3E1 "Freshness Value";
CM_ SG_ 993 KZK3E1 "KZKValue";
CM_ BO_ 1003 "Reserve";
CM_ SG_ 1003 UMRSIF10 "Upper Manager IF_ID";
CM_ SG_ 1003 UMRSRQ10 "Request ID";
CM_ SG_ 1003 UMRSRV10 "reserve";
CM_ SG_ 1003 UMRSAD10 "Result Data";
CM_ SG_ 1003 FV3EB "Freshness Value";
CM_ SG_ 1003 KZK3EB "KZKValue";
CM_ BO_ 1007 "Reserve";
CM_ SG_ 1007 UMRSIF11 "Upper Manager IF_ID";
CM_ SG_ 1007 UMRSRQ11 "Request ID";
CM_ SG_ 1007 UMRSRV11 "reserve";
CM_ SG_ 1007 UMRSAD11 "Result Data";
CM_ SG_ 1007 FV3EF "Freshness Value";
CM_ SG_ 1007 KZK3EF "KZKValue";
CM_ BO_ 1013 "Reserve";
CM_ SG_ 1013 UMRSIF12 "Upper Manager IF_ID";
CM_ SG_ 1013 UMRSRQ12 "Request ID";
CM_ SG_ 1013 UMRSRV12 "reserve";
CM_ SG_ 1013 UMRSAD12 "Result Data";
CM_ SG_ 1013 FV3F5 "Freshness Value";
CM_ SG_ 1013 KZK3F5 "KZKValue";
CM_ BO_ 1059 "Reserve";
CM_ SG_ 1059 UMIIFTT "Upper Manager IF_ID";
CM_ SG_ 1059 UMIREQTT "Request ID";
CM_ SG_ 1059 UMIRSVTT "reserve";
CM_ SG_ 1059 UMIDATTT "Information Data";
CM_ BO_ 1065 "Reserve";
CM_ SG_ 1065 UMIIFS1 "Upper Manager IF_ID";
CM_ SG_ 1065 UMIREQS1 "Request ID";
CM_ SG_ 1065 UMIRSVS1 "reserve";
CM_ SG_ 1065 UMIDATS1 "Information Data";
CM_ BO_ 1072 "Reserve";
CM_ SG_ 1072 UMIIFS2 "Upper Manager IF_ID";
CM_ SG_ 1072 UMIREQS2 "Request ID";
CM_ SG_ 1072 UMIRSVS2 "reserve";
CM_ SG_ 1072 UMIDATS2 "Information Data";
CM_ BO_ 1152 "Reserve";
CM_ SG_ 1152 UMIIFS3 "Upper Manager IF_ID";
CM_ SG_ 1152 UMIREQS3 "Request ID";
CM_ SG_ 1152 UMIRSVS3 "reserve";
CM_ SG_ 1152 UMIDATS3 "Information Data";
CM_ BO_ 1156 "Reserve";
CM_ SG_ 1156 UMIIFS4 "Upper Manager IF_ID";
CM_ SG_ 1156 UMIREQS4 "Request ID";
CM_ SG_ 1156 UMIRSVS4 "reserve";
CM_ SG_ 1156 UMIDATS4 "Information Data";
CM_ BO_ 1169 "Reserve";
CM_ SG_ 1169 UMIIFPW "Upper Manager IF_ID";
CM_ SG_ 1169 UMIREQPW "Request ID";
CM_ SG_ 1169 UMIRSVPW "reserve";
CM_ SG_ 1169 UMIDATPW "Information Data";
CM_ BO_ 1175 "Reserve";
CM_ SG_ 1175 UMIIFSD "Upper Manager IF_ID";
CM_ SG_ 1175 UMIREQSD "Request ID";
CM_ SG_ 1175 UMIRSVSD "reserve";
CM_ SG_ 1175 UMIDATSD "Information Data";
CM_ BO_ 1318 "Reserve";
CM_ SG_ 1318 UMIIFDL "Upper Manager IF_ID";
CM_ SG_ 1318 UMIREQDL "Request ID";
CM_ SG_ 1318 UMIRSVDL "reserve";
CM_ SG_ 1318 UMIDATDL "Information Data";
CM_ BO_ 1323 "Reserve";
CM_ SG_ 1323 UMIIFI1 "Upper Manager IF_ID";
CM_ SG_ 1323 UMIREQI1 "Request ID";
CM_ SG_ 1323 UMIRSVI1 "reserve";
CM_ SG_ 1323 UMIDATI1 "Information Data";
CM_ BO_ 1324 "Reserve";
CM_ SG_ 1324 UMIIFI2 "Upper Manager IF_ID";
CM_ SG_ 1324 UMIREQI2 "Request ID";
CM_ SG_ 1324 UMIRSVI2 "reserve";
CM_ SG_ 1324 UMIDATI2 "Information Data";
CM_ BO_ 1328 "Reserve";
CM_ SG_ 1328 UMIIFI3 "Upper Manager IF_ID";
CM_ SG_ 1328 UMIREQI3 "Request ID";
CM_ SG_ 1328 UMIRSVI3 "reserve";
CM_ SG_ 1328 UMIDATI3 "Information Data";
CM_ BO_ 1329 "Reserve";
CM_ SG_ 1329 UMIIFDP "Upper Manager IF_ID";
CM_ SG_ 1329 UMIREQDP "Request ID";
CM_ SG_ 1329 UMIRSVDP "reserve";
CM_ SG_ 1329 UMIDATDP "Information Data";
CM_ BO_ 1332 "Reserve";
CM_ SG_ 1332 UMIIFFG "Upper Manager IF_ID";
CM_ SG_ 1332 UMIREQFG "Request ID";
CM_ SG_ 1332 UMIRSVFG "reserve";
CM_ SG_ 1332 UMIDATFG "Information Data";
CM_ SG_ 1332 FV534 "Freshness Value";
CM_ SG_ 1332 KZK534 "KZKValue";
CM_ BO_ 1333 "Reserve";
CM_ SG_ 1333 UMIIFA1 "Upper Manager IF_ID";
CM_ SG_ 1333 UMIREQA1 "Request ID";
CM_ SG_ 1333 UMIRSVA1 "reserve";
CM_ SG_ 1333 UMIDATA1 "Information Data";
CM_ BO_ 1335 "Reserve";
CM_ SG_ 1335 UMIIFA2 "Upper Manager IF_ID";
CM_ SG_ 1335 UMIREQA2 "Request ID";
CM_ SG_ 1335 UMIRSVA2 "reserve";
CM_ SG_ 1335 UMIDATA2 "Information Data";
CM_ BO_ 1336 "Reserve";
CM_ SG_ 1336 UMIIFA3 "Upper Manager IF_ID";
CM_ SG_ 1336 UMIREQA3 "Request ID";
CM_ SG_ 1336 UMIRSVA3 "reserve";
CM_ SG_ 1336 UMIDATA3 "Information Data";
CM_ BO_ 691 "Reserve";
CM_ SG_ 691 ST1 "My Room State";
CM_ SG_ 691 ST1PER "My Room Permission";
CM_ SG_ 691 ST2 "Displaying car State";
CM_ SG_ 691 ST2PER "Displaying car Permission";
CM_ SG_ 691 ST3 "ADAS Training State";
CM_ SG_ 691 ST3PER "ADAS Training Permission";
CM_ SG_ 691 ST4 "reserve";
CM_ SG_ 691 ST4PER "reserve";
CM_ SG_ 691 ST5 "reserve";
CM_ SG_ 691 ST5PER "reserve";
CM_ SG_ 691 ST6 "reserve";
CM_ SG_ 691 ST6PER "reserve";
CM_ SG_ 691 ST7 "reserve";
CM_ SG_ 691 ST7PER "reserve";
CM_ SG_ 691 ST8 "reserve";
CM_ SG_ 691 ST8PER "reserve";
CM_ SG_ 691 ST9 "reserve";
CM_ SG_ 691 ST9PER "reserve";
CM_ SG_ 691 ST10 "reserve";
CM_ SG_ 691 ST10PER "reserve";
CM_ SG_ 691 ST11 "reserve";
CM_ SG_ 691 ST11PER "reserve";
CM_ SG_ 691 ST12 "reserve";
CM_ SG_ 691 ST12PER "reserve";
CM_ SG_ 691 ST13 "reserve";
CM_ SG_ 691 ST13PER "reserve";
CM_ SG_ 691 ST14 "reserve";
CM_ SG_ 691 ST14PER "reserve";
CM_ SG_ 691 ST15 "reserve";
CM_ SG_ 691 ST15PER "reserve";
CM_ SG_ 691 ST16 "reserve";
CM_ SG_ 691 ST16PER "reserve";
CM_ SG_ 691 ST17 "reserve";
CM_ SG_ 691 ST17PER "reserve";
CM_ SG_ 691 ST18 "reserve";
CM_ SG_ 691 ST18PER "reserve";
CM_ BO_ 1157 "Reserve";
CM_ SG_ 1157 VSI_L4B " [L4B] REAR WINDOW  WIPER";
CM_ SG_ 1157 VSI_L6K " [L6K] FRONT FOG LAMP";
CM_ SG_ 1157 VSI_L7E " [L7E] REAR FOG LAMP";
CM_ BO_ 1084 "Reserve";
CM_ SG_ 1084 VSI_B3N " [B3N] TOWING PACKAGE";
CM_ SG_ 1084 VSI_K1B " [K1B] FRONT BUMPER";
CM_ SG_ 1084 VSI_U4C " [U4C] PERIPHERAL MONITOR CAMERA";
CM_ SG_ 1084 VSI_B2B " [B2B] GRADE PACKAGE";
CM_ SG_ 1084 VSI_B2C " [B2C] PACKAGE OPTION 1";
CM_ SG_ 1084 VSI_U4Y " [U4Y] CAMERA WASHER";
CM_ BO_ 1158 "Reserve";
CM_ SG_ 1158 VSI_C7E "[C7E] SLOPE UNIT";
CM_ SG_ 1158 VSI_C7F "[C7F] VEHICLE HEIGHT DOWN DEVI";
CM_ SG_ 1158 VSI_G4A " [G4A] TIRE & DISC WHEEL";
CM_ SG_ 1158 VSI_G4B " [G4B] TIRE & DISC WHEEL";
CM_ BO_ 891 "Reserve";
CM_ SG_ 891 ACPRE_AD "refrigerant gas pressure sensor A/D data";
CM_ SG_ 891 EXPMIP "Expansion A/C input power";
CM_ SG_ 891 AMR "A/C motor revolution";
CM_ SG_ 891 MIP "A/C input power";
CM_ BO_ 397 "Reserve";
CM_ SG_ 397 HVH_ATPW "high voltage heater actual power";
CM_ BO_ 410 "Reserve";
CM_ SG_ 410 COMPRP_A "Electromotion Compressor Target revolutions signal";
CM_ SG_ 410 ACMODE_P "A/C control state signal";
CM_ BO_ 971 "Reserve";
CM_ SG_ 971 PBD_MAIN "PBD Main SW";
CM_ SG_ 971 LOCK_IF "Backdoor Lock Information";
CM_ SG_ 971 BZ_VOL "Buzzer volume";
CM_ SG_ 971 OPN_POS "PBD Opening Position";
CM_ SG_ 971 KICK_CON "Kick Sensor Condition";
CM_ SG_ 971 KICK_FNT "Kick Sensor Function Display";
CM_ SG_ 971 KSSCONTL "Kick Sensor Condition for PTL";
CM_ SG_ 971 KSSFNTTL "Kick Sensor Function Display for PTL";
CM_ SG_ 971 BVC_FNT "Buzzer Volume Control Function Display";
CM_ SG_ 971 MSC_FNT "Main Switch Control Function Display";
CM_ SG_ 971 DOC_FNT "Door Openig Control Function Display";
CM_ BO_ 939 "Reserve";
CM_ SG_ 939 PBDPTLFG "PBDPTL flag";
CM_ SG_ 939 PBDOPE "PBD operation status";
CM_ SG_ 939 PBDPOSLV "Back Door Position Level";
CM_ BO_ 1014 "Reserve";
CM_ SG_ 1014 BSD_STAT "BSD Module Status";
CM_ SG_ 1014 RCTA_DIR "RCTA direction signal";
CM_ SG_ 1014 BSD_SW "BSD Main Switch";
CM_ SG_ 1014 RCTA_EQ "RCTA equipment flag";
CM_ SG_ 1014 RCTADISP "RCTA display permit flag";
CM_ SG_ 1014 RCTA_SW "RCTA Switch";
CM_ SG_ 1014 BSD_BUZ "BSD BUZZER";
CM_ SG_ 1014 BSD_ILCR "BSM Indicator Luminance customization request";
CM_ SG_ 1014 BSD_ILV "BSM Indicator Luminance customization value";
CM_ SG_ 1014 BSD_ITCR "BSM Information providing Timing customization request";
CM_ SG_ 1014 BSD_ITV "BSM Information providing Timing customization value";
CM_ SG_ 1014 FHL_STAT "FHL System Status";
CM_ SG_ 1014 ADDSTRI2 "ADDS request 2";
CM_ SG_ 1014 ADDSTRI1 "ADDS request 1";
CM_ SG_ 1014 BSD_TTR "BSM OFF Indicator request";
CM_ SG_ 1014 BSD_SWR "BSM Soft Switch request";
CM_ SG_ 1014 RCTA_SWR "RCTA Soft Switch request";
CM_ SG_ 1014 ADDS_EQ "ADDS equipment flag";
CM_ SG_ 1014 FHL_EQ "FHL equipment flag";
CM_ SG_ 1014 BSD_SMS "BSM Support Method Status";
CM_ SG_ 1014 RTAN_ITV "RTAN Information providing Timing customization value";
CM_ SG_ 1014 RTAN_SW "RTAN Main Switch";
CM_ SG_ 1014 RTAN_SWR "RTAN Soft Switch request";
CM_ SG_ 1014 RTANITCR "RTAN Information providing Timing customization request";
CM_ SG_ 1014 RTANDISM "RTAN Display request for MET";
CM_ SG_ 1014 BSDDISP2 "BSM alert options customization request";
CM_ SG_ 1014 BSDDISP1 "BSM buzzer alert custimization request";
CM_ SG_ 1014 DOA_BUZ "DOA buzzer sound request";
CM_ BO_ 565 "Reserve";
CM_ SG_ 565 DOA_EQ "DOA equipment flag";
CM_ SG_ 565 DOA_STAT "DOA System Status";
CM_ SG_ 565 DOAM_FR "DOA operation indication request for MID FR";
CM_ SG_ 565 DOAM_FL "DOA operation indication request for MID FL";
CM_ SG_ 565 DOAM_RR "DOA operation indication request for MID RR";
CM_ SG_ 565 DOAM_RL "DOA operation indication request for MID RL";
CM_ SG_ 565 DOAM_TR "DOA Target indication request for MID RH";
CM_ SG_ 565 DOAM_TL "DOA Target indication request for MID LH";
CM_ SG_ 565 DOAM_VEH "DOA Vehicle indication request for MID";
CM_ SG_ 565 DOA_ITCR "DOA Information providing Timing customization request";
CM_ SG_ 565 DOA_VORH "DOA VOICE ALERT RIGHT";
CM_ SG_ 565 DOA_VOLH "DOA VOICE ALERT LEFT";
CM_ SG_ 565 DOA_STVO "MM standby requested ";
CM_ SG_ 565 DOA_SWR "DOA Soft Switch request";
CM_ SG_ 565 DOA_SW "DOA Main Switch";
CM_ SG_ 565 DOAM_MSG "DOA  Unavailable indication request for MID";
CM_ SG_ 565 DOA_ITV "DOA Information providing Sensitivity customization value";
CM_ SG_ 565 ADDS_SW "ADDS Main Switch";
CM_ SG_ 565 DOAVOL_R "DOA Voice Notification Usage";
CM_ SG_ 565 ADDS_SWR "ADDS Soft Switch request";
CM_ SG_ 565 BSR_STAT "BSM ECU Status";
CM_ SG_ 565 BSMDISPR "BSM meter information right";
CM_ SG_ 565 BSMDISPL "BSM meter information left";
CM_ BO_ 687 "Reserve";
CM_ SG_ 687 TBSM_POP "Trailer BSM specific Pop-Ups";
CM_ SG_ 687 TBSMSTAT "Trailer BSM Status";
CM_ SG_ 687 GRG_EQ "Trailer Garage menu Equipment";
CM_ SG_ 687 OMI_L "Drive request of Left side Indicator";
CM_ SG_ 687 OMI_R "Drive request of Right side Indicator";
CM_ SG_ 687 TRA_STT "Trailer ADAS ON OFF";
CM_ SG_ 687 TRLR_EQ "Trailer Package Equipment";
CM_ SG_ 687 TCSL_L "Currently Selected Trailer Length";
CM_ BO_ 1090 "Reserve";
CM_ SG_ 1090 CDCREV "[RESERVE]";
CM_ BO_ 819 "Reserve";
CM_ SG_ 819 ODO_MET "Odometer value stored in Meter ECU memory";
CM_ SG_ 819 FV333 "MET1S02Freshness Value";
CM_ SG_ 819 KZK333 "MET1S02 KZKValue";
CM_ BO_ 820 "Reserve";
CM_ SG_ 820 PRMEXE_M "Parameter of execution of personal identification device registration";
CM_ SG_ 820 REQEXE_M "Request of execution of personal identification device registration";
CM_ SG_ 820 DIDEXE_M "Devce id of execution of personal identification device registration";
CM_ SG_ 820 DEL_UN_M "ScreenResponse_DeleteDriverUserNo";
CM_ SG_ 820 MREQDP_M "ScreenResponse_DrivingPositionRecallRequest";
CM_ SG_ 820 MSRDRV_M "ScreenResponse_Driver";
CM_ SG_ 820 OPTEXE_M "execution option of personal identification device registration";
CM_ BO_ 849 "Reserve";
CM_ SG_ 849 ETHWU_21 "Eth continuous reques to ADC from CDC";
CM_ SG_ 849 ETHWU_23 "Eth continuous reques to DCM from CDC";
CM_ BO_ 473 "Reserve";
CM_ SG_ 473 HED_S "Head position signal of Light SW for STR";
CM_ SG_ 473 TAL_S "Tail position signal of Light SW for STR";
CM_ SG_ 473 DRL_S "DRL position signal of Light SW for STR";
CM_ SG_ 473 AUT_S "Auto position signal of Light SW for STR";
CM_ SG_ 473 OFF_S "OFF position signal of Light SW for STR";
CM_ SG_ 473 AHB_S "AUTO hi-beam position signal of Light SW for STR";
CM_ SG_ 473 PAS_S "Passing SW position signal for STR";
CM_ SG_ 473 HIB_S "Hi-beam position signal of Light SW for STR";
CM_ SG_ 473 BW_S "Bad Weather SW position signal for STR";
CM_ SG_ 473 RFG_S "Rear Fog SW position signal for STR";
CM_ SG_ 473 FOG_S "Front Fog SW position signal for STR";
CM_ SG_ 473 CRGL_S "Lever position signal for Left cornering Lamp on STR";
CM_ SG_ 473 CRGR_S "Lever position signal for Right cornering Lamp on STR";
CM_ SG_ 473 TRNL_S "Lever position signal for Left Turn Lamp on STR";
CM_ SG_ 473 TRNR_S "Lever position signal for Right Turn Lamp on STR";
CM_ SG_ 473 CXP_TERR "CXPI communication Error (Turn SW)";
CM_ SG_ 473 CXP_JDGT "Multiple signal presence judgement (Turn SW)";
CM_ BO_ 755 "Reserve";
CM_ SG_ 755 WVR_S "Volume signal of Wiper adjustment for STR";
CM_ SG_ 755 WSW_S "Signal of Washer SW for STR";
CM_ SG_ 755 WRSW_S "Signal of Rear Washer SW for STR";
CM_ SG_ 755 WRON_S "ON position signal of Rear Wiper SW for STR";
CM_ SG_ 755 WRIN_S "INT position signal of Rear Wiper SW for STR";
CM_ SG_ 755 WINT_S "INT position signal of Wiper SW for STR";
CM_ SG_ 755 WMST_S "MIST position signal of Wiper SW for STR";
CM_ SG_ 755 WA_S "AUTO position signal of Wiper SW for STR";
CM_ SG_ 755 WHI_S "HI position signal of Wiper SW for STR";
CM_ SG_ 755 WLO_S "LO position signal of Wiper SW for STR";
CM_ SG_ 755 WOFF_S "OFF position signal of Wiper SW for STR";
CM_ SG_ 755 WAI_S "Distriction signal of Wiper AUTO/INT SW for STR";
CM_ SG_ 755 CXP_WERR "CXPI communication Error (Wiper SW)";
CM_ SG_ 755 CXP_JDGW "Multiple signal presence judgement (Wiper SW)";
CM_ BO_ 1080 "Reserve";
CM_ SG_ 1080 VCDSP_1 "Switching display request of voice";
CM_ SG_ 1080 PCDSP_1 "Switching display request of external camera image";
CM_ SG_ 1080 GCDSP_1 "Switching display request of location information";
CM_ BO_ 847 "Reserve";
CM_ SG_ 847 SNCCNTRQ "AVN Display Request Synchronous Counter";
CM_ SG_ 847 REQDSPID "AVN Display Request ID";
CM_ SG_ 847 ST_LCRIM "Remote Immobilizer Passcode Lock Status";
CM_ SG_ 847 ST_STRIM "Remote Immobilizer Setting Status";
CM_ BO_ 867 "Reserve";
CM_ SG_ 867 RSCOM811 "Remote Service Request 11";
CM_ SG_ 867 RSCOM812 "Remote Service Request 12";
CM_ SG_ 867 RSCOM813 "Remote Service Request 13";
CM_ SG_ 867 RSCOM814 "Remote Service Request 14";
CM_ SG_ 867 RSCOM815 "Remote Service Request 15";
CM_ SG_ 867 RSCOM816 "Remote Service Request 16";
CM_ SG_ 867 RSCOM817 "Remote Service Command 7";
CM_ SG_ 867 RSCOM818 "Remote Service Command 8";
CM_ SG_ 867 RSCOMEX1 "Remote Service Extension Command 1";
CM_ SG_ 867 RSCOMEX2 "Remote Service Extension Command 2";
CM_ SG_ 867 RSCOMEX3 "Remote Service Extension Command 3";
CM_ BO_ 840 "Reserve";
CM_ SG_ 840 ETHWU_32 "Eth continuous reques to CDC from DCM";
CM_ BO_ 184 "Reserve";
CM_ SG_ 184 BKTQA "Driver Operate Brake Torque (on D/S shaft)";
CM_ SG_ 184 FBKSYS "Control torque valid flag";
CM_ SG_ 184 TBKCSYS2 "TBKCR_AX valid flag";
CM_ SG_ 184 TBKCR_AX "Target Brake Control Request Acceleration from brake system operation";
CM_ SG_ 184 FBKDR_AX "Driver Request Acceleration from brake pedal operation";
CM_ SG_ 184 FBKDRSYS "FBKDR_AX valid flag";
CM_ BO_ 750 "Reserve";
CM_ SG_ 750 NMRBR_MD "Nameraka Brake  Mode Information";
CM_ SG_ 750 BHSWEXT "Existence of BH software switch";
CM_ BO_ 471 "Reserve";
CM_ SG_ 471 E_CRC1D7 "DDM1S17 E2E_CRC";
CM_ SG_ 471 E_CNT1D7 "DDM1S17 E2E_CNT";
CM_ SG_ 471 B_BRKW "Brake Warning Lamp Control Flag";
CM_ SG_ 471 BRK_MID "Brake Warning display request for Multidisplay";
CM_ SG_ 471 B_ABS "ABS Warning Lamp Control Flag";
CM_ SG_ 471 ABS_MID "ABS Warning display request for Multidisplay";
CM_ SG_ 471 B_EBW "ECB Warning Lamp Control Flag";
CM_ SG_ 471 EBW_MID "EBW Warning display request for Multidisplay";
CM_ SG_ 471 B_BRLV "Brake Reservoir Level Warning SW";
CM_ SG_ 471 TRCOFF "TRC OFF Lamp";
CM_ SG_ 471 TRCCONRL "TRC activating condition flag(RL)";
CM_ SG_ 471 TRCCONRR "TRC activating condition flag(RR)";
CM_ SG_ 471 TRCCONFL "TRC activating condition flag(FL)";
CM_ SG_ 471 TRCCONFR "TRC activating condition flag(FR)";
CM_ SG_ 471 TRC_MID "TRC OFF  display request for Multidisplay";
CM_ SG_ 471 VSCOFF "VSC OFF Lamp";
CM_ SG_ 471 SLP_WL "Slip Indicator";
CM_ SG_ 471 B_ALSD "AutoLSD Lamp Control Flag";
CM_ SG_ 471 BHEXIST "BrakeHold control existance flag";
CM_ SG_ 471 B_DAINDP "BH Hold Indicator";
CM_ SG_ 471 B_DAINDC "BH Standby Indicator";
CM_ SG_ 471 B_DAINFO "BH Information Contorl Flag";
CM_ SG_ 471 B_OTA "Off road Turn Assist Indicator Control Flag";
CM_ SG_ 471 OTA_DISP "Off road Turn Assist display request for Multidisplay";
CM_ SG_ 471 VSCEXPRT "VSC Expert mode indicator";
CM_ SG_ 471 EXPTLVL "Expert Level from VSC ";
CM_ SG_ 471 EXPTCNFG "Expert config info";
CM_ SG_ 471 EXPTPLUS "Expert+ mode status";
CM_ SG_ 471 B_DACIND "DAC Indicator Control Flag";
CM_ SG_ 471 DAC_DISP "DAC display request for Multidisplay";
CM_ SG_ 471 DAC_SETV "DAC set speed";
CM_ SG_ 471 CRAWLIND "Crawl Control Indicator";
CM_ SG_ 471 CRAWLMID "Crawl Control display request for Multidisplay";
CM_ SG_ 471 CRAWLSPD "Crawl Control display request for SPEED";
CM_ SG_ 471 DDRTWV "Demand remote Warning of VSC";
CM_ SG_ 471 VSCEXIST "VSC control existance flag";
CM_ SG_ 471 B_BUZZER "Buzzer Control Flag";
CM_ SG_ 471 B_PKBLP "PKB lamp control";
CM_ SG_ 471 B_EPBWL "EPB warning lamp control";
CM_ SG_ 471 B_EPBMID "EPB multi information display control";
CM_ SG_ 471 MCBW "MCB Warning";
CM_ SG_ 471 CRLSPD2 "Crawl Control display request for SPEED2";
CM_ SG_ 471 CRLAOFF "Crawl Control Accelerator OFF Operation";
CM_ SG_ 471 CRLSRINF "Crawl Control Speed Range Information";
CM_ BO_ 730 "Reserve";
CM_ SG_ 730 POSIREQ "TargetPosReq";
CM_ SG_ 730 POSIREQ2 "TargetPosReq2";
CM_ SG_ 730 A_DMODEA "A/C drive Drive Mode information";
CM_ SG_ 730 B_DCMDA1 "A/C drive mode serect signal infomation";
CM_ SG_ 730 B_DCMDA2 "A/C drive mode serect signal support information";
CM_ SG_ 730 B_DCMDA3 "A/C drive mode serect status";
CM_ BO_ 741 "Reserve";
CM_ SG_ 741 GRLGDBCR "Cutomize current signal of distribution ratio between left and right for Grip mode";
CM_ SG_ 741 DMCNVINF "Conversion select information";
CM_ SG_ 741 CNV_MODE "Conversion Mode";
CM_ SG_ 741 DMCNVVLD "Conversion valid information";
CM_ BO_ 641 "Reserve";
CM_ SG_ 641 TEC "Total Energy Consumption";
CM_ SG_ 641 DRVEC "Driving Energy Consumption";
CM_ SG_ 641 ALTEC "Altitude Energy Consumption";
CM_ SG_ 641 ACEC "A/C Energy Consumption";
CM_ SG_ 641 BPEC "Battery Preconditioning Energy Consumption";
CM_ SG_ 641 DAEC "Driving Ather Energy Consumption";
CM_ SG_ 641 CAEC "Chging Ather Energy Consumption";
CM_ SG_ 641 CUMTEC "Cumulative Total Energy Consumption";
CM_ SG_ 641 CUMDRVEC "Cumulative Driving Energy Consumption";
CM_ SG_ 641 CUMALTEC "Cumulative Altitude Energy Consumption";
CM_ SG_ 641 CUMACEC "Cumulative A/C Energy Consumption";
CM_ BO_ 642 "Reserve";
CM_ SG_ 642 CUMBPEC "Cumulative Battery Preconditioning Energy Consumption";
CM_ SG_ 642 CUMDAEC "Cumulative Driving Ather Energy Consumption";
CM_ SG_ 642 CUMCAEC "Cumulative Chging Ather Energy Consumption";
CM_ SG_ 642 RBSCC_E "Remaining Batterypower to SOC Convert Coefficient E";
CM_ SG_ 642 RBSCC_F "Remaining Batterypower to SOC Convert Coefficient F";
CM_ SG_ 642 RBSCC_G "Remaining Batterypower to SOC Convert Coefficient G";
CM_ SG_ 642 RBSCC_H "Remaining Batterypower to SOC Convert Coefficient H";
CM_ SG_ 642 CHGCAL1 "Charge calculation No1";
CM_ SG_ 642 CHGCAL2 "Charge calculation No2";
CM_ SG_ 642 FSWRP "Route Planner Function Switching";
CM_ SG_ 642 U1TOCDC1 "u1 dummy to CDC No.1";
CM_ SG_ 642 U1TOCDC2 "u1 dummy to CDC No.2";
CM_ SG_ 642 U1TOCDC3 "u1 dummy to CDC No.3";
CM_ SG_ 642 S2TOCDC1 "s1 dummy to CDC No.1";
CM_ SG_ 642 S2TOCDC2 "s1 dummy to CDC No.2";
CM_ SG_ 642 S2TOCDC3 "s1 dummy to CDC No.3";
CM_ BO_ 1320 "Reserve";
CM_ SG_ 1320 RSISDKME "Prior identification Res_MEANS";
CM_ SG_ 1320 RSISIDDK "Prior identification result";
CM_ BO_ 290 "Reserve";
CM_ SG_ 290 FR_DISP "face recognition display";
CM_ BO_ 1063 "Reserve";
CM_ SG_ 1063 R1_MD_SW "Track Mode switch operation signal";
CM_ SG_ 1063 R2_MD_SW "Reserve2 Mode switch operation signal";
CM_ SG_ 1063 R3_MD_SW "Reserve3 Mode switch operation signal";
CM_ SG_ 1063 R4_MD_SW "Reserve4 Mode switch operation signal";
CM_ SG_ 1063 R5_MD_SW "Reserve5 Mode switch operation signal";
CM_ SG_ 1063 R6_MD_SW "Reserve6 Mode switch operation signal";
CM_ SG_ 1063 R7_MD_SW "Reserve7 Mode switch operation signal";
CM_ SG_ 1063 R8_MD_SW "Reserve8 Mode switch operation signal";
CM_ SG_ 1063 R9_MD_SW "Reserve9 Mode switch operation signal";
CM_ SG_ 1063 R10_MDSW "Reserve10 Mode switch operation signal";
CM_ SG_ 1063 R11_MDSW "Reserve11 Mode switch operation signal";
CM_ SG_ 1063 R12_MDSW "Reserve12 Mode switch operation signal";
CM_ SG_ 1063 R13_MDSW "Reserve13 Mode switch operation signal";
CM_ SG_ 1063 R14_MDSW "Reserve14 Mode switch operation signal";
CM_ SG_ 1063 R15_MDSW "Reserve15 Mode switch operation signal";
CM_ SG_ 1063 R16_MDSW "Reserve16 Mode switch operation signal";
CM_ SG_ 1063 R17_MDSW "Reserve17 Mode switch operation signal";
CM_ SG_ 1063 R18_MDSW "Reserve18 Mode switch operation signal";
CM_ SG_ 1063 R19_MDSW "Reserve19 Mode switch operation signal";
CM_ SG_ 1063 R20_MDSW "Reserve20 Mode switch operation signal";
CM_ SG_ 1063 R21_MDSW "Reserve21 Mode switch operation signal";
CM_ SG_ 1063 R22_MDSW "Reserve22 Mode switch operation signal";
CM_ SG_ 1063 R23_MDSW "Reserve23 Mode switch operation signal";
CM_ SG_ 1063 R24_MDSW "Reserve9 Mode switch operation signal";
CM_ SG_ 1063 TW_MD_SW "Towing MODE SW operation signal";
CM_ SG_ 1063 CH_MD_SW "Chauffeur MODE SW operation signal";
CM_ SG_ 1063 P1_MD_SW "Plus1 MODE SW operation signal";
CM_ SG_ 1063 RG_MD_SW "Range MODE SW operation signal";
CM_ SG_ 1063 CF_MD_SW "COMFORT MODE SW operation signal";
CM_ SG_ 1063 PW_MD_SW "POWER MODE SW operation signal";
CM_ SG_ 1063 SN_MD_SW "SNOW MODE SW operation signal";
CM_ SG_ 1063 SP_MD_SW "SPORT SP MODE SW operation signal";
CM_ SG_ 1063 EC_MD_SW "ECO MODE SW operation signal";
CM_ SG_ 1063 NR_MD_SW "NORMAL MODE SW operation signal";
CM_ SG_ 1063 CS_MD_SW "CUSTOM MODE SW operation signal";
CM_ SG_ 1063 ECORC_SW "S&S OFF SW operation signal";
CM_ SG_ 1063 SS_MD_SW "SPORT S MODE SW operation signal";
CM_ BO_ 958 "Reserve";
CM_ SG_ 958 LPSDWARN "Left PSD Warning Request";
CM_ BO_ 943 "Reserve";
CM_ SG_ 943 RPSDWARN "Right PSD Warning Request";
CM_ BO_ 645 "Reserve";
CM_ SG_ 645 DESMUTE "Driver Emargency Stop Assist Mute request";
CM_ BO_ 791 "Reserve";
CM_ SG_ 791 LCANGBZ "LaneChangeSupport Cancel  buzzer";
CM_ SG_ 791 LCAVCBZ "LaneChangeSupport Vehicle Caution buzzer";
CM_ SG_ 791 LCSRQBZ "LaneChangeSupport Request acceptance buzzer";
CM_ SG_ 791 LCSONSD "LCS OnScreen Display";
CM_ SG_ 791 LCSEXIST "LCS EXIST";
CM_ SG_ 791 LCATRAJE "LCA Trajectory display";
CM_ SG_ 791 LCSLWNGD "LCS Left Warning Display";
CM_ SG_ 791 LCSARRLD "LCS Left Arrow Display";
CM_ SG_ 791 LCSARRRD "LCS Right Arrow Display";
CM_ SG_ 791 LCSRWNGD "LCS Right Warning Display";
CM_ SG_ 791 LTCLCSD "LTC LCS DISP";
CM_ SG_ 791 DM_DISPM "Emergency stop support display request for MID";
CM_ SG_ 791 DM_BZR "Emergency stop support Buzzer request";
CM_ SG_ 791 LCASGEST "LCA suggestion exist";
CM_ SG_ 791 LCASGMCS "LCA suggestion MODE Customize State";
CM_ SG_ 791 LCAMSG "LCA message display";
CM_ SG_ 791 LCASGIND "LCA sugestion indicator";
CM_ BO_ 1544 "Reserve";
CM_ SG_ 1544 CTAMBG "CTA MID display background";
CM_ SG_ 1544 CTAMIDCR "CTA MID display cross target right";
CM_ SG_ 1544 CTAMIDCL "CTA MID display cross target left";
CM_ SG_ 1544 CTAMIDCA "CTA MID display caution";
CM_ SG_ 1544 CTAOFFS "CTA Off Status for Customize Switch";
CM_ SG_ 1544 CTAWDS "CTA Warning Distance Status for Customize Switch";
CM_ SG_ 1544 CTABUZF "CTA buzzer flag";
CM_ SG_ 1544 CTAHR "CTA HUD display right target";
CM_ SG_ 1544 CTAHL "CTA HUD display left target";
CM_ SG_ 1544 CTAUCT "CTA unusable condition switch text ";
CM_ BO_ 1041 "Reserve";
CM_ SG_ 1041 PCSINDI "PCS Indicator display";
CM_ SG_ 1041 PCSWM "PCS Warning Message";
CM_ SG_ 1041 PCSEXIST "PCS existence flag";
CM_ SG_ 1041 PCSWDUCT "PCS Warning distance unusable condition text display";
CM_ SG_ 1041 RTWUCT "Right/Left turn warning unusable condition switch text ";
CM_ SG_ 1041 RTWOFFS "Right/Left turn warning Off Status for Customize Switch";
CM_ SG_ 1041 PCSMTBZ2 "PCS Meter Buzzer Request(extend)";
CM_ SG_ 1041 PCSOFFS "PCS Off Stasus for Soft Switch";
CM_ SG_ 1041 FSSINFO "False start suppression system Information";
CM_ SG_ 1041 PCSRTWM "Right turn caution";
CM_ SG_ 1041 PCSSWM "Notice during AES steerage control";
CM_ BO_ 1042 "Reserve";
CM_ SG_ 1042 LDAINDI "LDA Indicator Display";
CM_ SG_ 1042 LTAINDI "LTA Indicator Display";
CM_ SG_ 1042 LDAMSG "LDA Message Display";
CM_ SG_ 1042 LTAMSG "LTA Message Display";
CM_ SG_ 1042 CSFBUZ "Hands-free Attention Buzzer Request";
CM_ SG_ 1042 LDWBUZ "Lane Departure Alert Buzzer Request";
CM_ SG_ 1042 LKACB "Lane Tracing Assist Cancel Buzzer Request";
CM_ SG_ 1042 SWSBUZ "SWS Buzzer Request";
CM_ SG_ 1042 LKAWLSL "Left Side White Line Display";
CM_ SG_ 1042 LKAWLSR "Right Side White Line Display";
CM_ SG_ 1042 SWSRAD "SWS Rest Advisory Display";
CM_ SG_ 1042 LTAEXIST "LTA Existance Flag";
CM_ SG_ 1042 LDAEXIST "LDA Existence Information";
CM_ SG_ 1042 LKAWTCS "LDA Warning Timing Customize State";
CM_ SG_ 1042 SWSSWD "SWS SW INFO DISP";
CM_ SG_ 1042 LDWEXIST "LDA existance flag";
CM_ SG_ 1042 LDACS "LDA Main Switch Customize State";
CM_ SG_ 1042 VIBEXIST "STEERING VIBRATOR EXIST";
CM_ SG_ 1042 LDACD "LDA ALERT CUSTOMIZE DISP";
CM_ SG_ 1042 LTABZR "Lane Tracing Assist Buzzer Request";
CM_ SG_ 1042 SWSEXIST "SWS Existence Information";
CM_ SG_ 1042 LDWTEXT "LDA Warning Timing Existence Information";
CM_ SG_ 1042 LDAAMEX "LDA Mode Customize Existence";
CM_ SG_ 1042 LDAAMST "LDA Mode Customize State";
CM_ SG_ 1042 VSDGCONT "SDG control status";
CM_ SG_ 1042 VSDGONST "SDG function ON/OFF status";
CM_ SG_ 1042 VUSMONST "URSM function ON/OFF status";
CM_ BO_ 1008 "Reserve";
CM_ SG_ 1008 D_OPPT1 "Driver's seat operation part 1";
CM_ SG_ 1008 D_OPPT2 "Driver's seat operation part 2";
CM_ SG_ 1008 D_RF_ST "Driver's seat refresh mode";
CM_ SG_ 1008 D_RF_LV "Driver's seat refresh level";
CM_ SG_ 1008 D_STM2 "Driver's seat operation state No.2";
CM_ SG_ 1008 D_STM1 "Driver's seat operation state No.1";
CM_ SG_ 1008 SCD2 "Seat display request No.2";
CM_ SG_ 1008 D_WALKIN "Walk in State of Driver's Seat";
CM_ SG_ 1008 D_FST "Driver's seat function";
CM_ SG_ 1008 RST_OPAT "Display request signal for Rear seat operation attention";
CM_ SG_ 1008 D_SLDPOS "Driver's Seat Slide Position";
CM_ SG_ 1008 D_RCLPOS "Driver's Seat Reclining Position";
CM_ SG_ 1008 D_LIFPOS "Driver's Seat Lift Position";
CM_ BO_ 1184 "Reserve";
CM_ SG_ 1184 DREBUID "Drive Recorder EBU ID";
CM_ SG_ 1184 DREBU02 "Drive Recorder EBU02";
CM_ SG_ 1184 DREBU03 "Drive Recorder EBU03";
CM_ SG_ 1184 DREBU04 "Drive Recorder EBU04";
CM_ SG_ 1184 DREBU05 "Drive Recorder EBU05";
CM_ SG_ 1184 DREBU06 "Drive Recorder EBU06";
CM_ SG_ 1184 DREBU07 "Drive Recorder EBU07";
CM_ SG_ 1184 DREBU08 "Drive Recorder EBU08";
CM_ SG_ 1184 DREBU11 "Drive Recorder EBU11";
CM_ SG_ 1184 DREBU12 "Drive Recorder EBU12";
CM_ SG_ 1184 DREBU13 "Drive Recorder EBU13";
CM_ SG_ 1184 DREBU14 "Drive Recorder EBU14";
CM_ SG_ 1184 DREBU15 "Drive Recorder EBU15";
CM_ SG_ 1184 DREBU16 "Drive Recorder EBU16";
CM_ SG_ 1184 DREBU17 "Drive Recorder EBU17";
CM_ SG_ 1184 DREBU18 "Drive Recorder EBU18";
CM_ SG_ 1184 DREBU21 "Drive Recorder EBU21";
CM_ SG_ 1184 DREBU22 "Drive Recorder EBU22";
CM_ SG_ 1184 DREBU23 "Drive Recorder EBU23";
CM_ SG_ 1184 DREBU24 "Drive Recorder EBU24";
CM_ SG_ 1184 DREBU25 "Drive Recorder EBU25";
CM_ SG_ 1184 DREBU26 "Drive Recorder EBU26";
CM_ SG_ 1184 DREBU27 "Drive Recorder EBU27";
CM_ SG_ 1184 DREBU28 "Drive Recorder EBU28";
CM_ SG_ 1184 DREBU31 "Drive Recorder EBU31";
CM_ SG_ 1184 DREBU32 "Drive Recorder EBU33";
CM_ SG_ 1184 DREBU33 "Drive Recorder EBU32";
CM_ SG_ 1184 DREBU34 "Drive Recorder EBU34";
CM_ SG_ 1184 DREBU35 "Drive Recorder EBU35";
CM_ SG_ 1184 DREBU36 "Drive Recorder EBU36";
CM_ SG_ 1184 DREBU37 "Drive Recorder EBU37";
CM_ SG_ 1184 DREBU38 "Drive Recorder EBU38";
CM_ BO_ 959 "Reserve";
CM_ SG_ 959 B_P "Shift position P signal";
CM_ SG_ 959 B_R "Shift position R signal";
CM_ SG_ 959 B_N "Shift position N signal";
CM_ SG_ 959 B_D "Shift position D signal";
CM_ SG_ 959 B_B "Shift position B signal";
CM_ SG_ 959 XFSFT "Gear position fail / gear ratio fail";
CM_ SG_ 959 SFTOUT "Gear position signal";
CM_ SG_ 959 ACT "Under speed change (engagement start to engagement end)";
CM_ SG_ 959 IGP_PT2 "IGP Status Information";
CM_ BO_ 1025 "Reserve";
CM_ SG_ 1025 DRDYSTS "DRIVE READY status";
CM_ SG_ 1025 DRDYB "DRIVE READY buzzer";
CM_ BO_ 444 "Reserve";
CM_ SG_ 444 STRGCM "Torque of  Regeneration Brake";
CM_ BO_ 296 "Reserve";
CM_ SG_ 296 BCKLTRQ "Backup light request";
CM_ BO_ 464 "Reserve";
CM_ SG_ 464 FCRF "Forced charging request judgment flag";
CM_ SG_ 464 CLE_SOCF "Cloud Eco for heat management SOC control execution flag";
CM_ BO_ 1071 "Reserve";
CM_ SG_ 1071 HVIND "HV system malfunction indcation signal";
CM_ SG_ 1071 HVMALPAT "HV system malfunction part signal";
CM_ SG_ 1071 HVBUZZ "HV system malfunction buzzer signal";
CM_ SG_ 1071 HV4WNG "4WD warning ON and flashing request";
CM_ SG_ 1071 RMMPOPUP "Range Mode Message pop-up request";
CM_ SG_ 1071 BRKOTID "Brake system temperature warning ID";
CM_ SG_ 1071 PWRLMID "Driving Power Limit";
CM_ SG_ 1071 RBKLM "Deceleration decline(Engine brake reduction)";
CM_ SG_ 1071 EVBATLO "Low battery warning";
CM_ BO_ 805 "Reserve";
CM_ SG_ 805 INS_EVD "instantaneous EV distance";
CM_ SG_ 805 INS_UPD "instantaneous Data Update";
CM_ SG_ 805 INS_BATE "instantaneous Battery Energy";
CM_ SG_ 805 SOCINDLL "SOC Indicator Lower Limit";
CM_ SG_ 805 CNGPIEVD "change Plug-in EV distance";
CM_ BO_ 950 "Reserve";
CM_ SG_ 950 NDBW "NDB warning";
CM_ SG_ 950 SOC_MON "state of charge";
CM_ SG_ 950 CMH4 "check mode 4";
CM_ SG_ 950 CMH3 "check mode 3";
CM_ SG_ 950 CMH2 "check mode 2";
CM_ SG_ 950 CHMH "check mode 1";
CM_ SG_ 950 HV_M2B "energy flow(Battery->Motor2)";
CM_ SG_ 950 HV_EP "energy flow(Engine->Peller)";
CM_ SG_ 950 HV_EM "energy flow(Engine->Motor)";
CM_ SG_ 950 RNRG "renewal of regenerative";
CM_ SG_ 950 HV_MP "energy flow(Motor->Peller)";
CM_ SG_ 950 HV_MB "energy flow(Motor->Battery)";
CM_ SG_ 950 HV_RG "HV regenerative";
CM_ BO_ 1057 "Reserve";
CM_ SG_ 1057 PIEVSTS "Plug-in EV drive status";
CM_ SG_ 1057 HVEWUPST "HV engine warm-up status";
CM_ SG_ 1057 NACCON "Depress the accelerator in N position";
CM_ SG_ 1057 PICAU "Plug-in caution display data";
CM_ SG_ 1057 HVCAU "HV system malfunction notification signal";
CM_ SG_ 1057 TOWW "Towing warning";
CM_ SG_ 1057 ACCHCAU "accelerator hold caution";
CM_ SG_ 1057 VSP_MSG "Vehicle Start Prevantion System Message Request";
CM_ BO_ 1035 "Reserve";
CM_ SG_ 1035 BPSTS "Battery Preconditioning status";
CM_ SG_ 1035 BPRQSWDP "Display state of User battery preconditioning control request SW";
CM_ SG_ 1035 BPNGRS "NG Reason for Battery Preconditioning";
CM_ SG_ 1035 BPENBL "Enable to Battery Preconditioning";
CM_ SG_ 1035 BPNAVIDP "Display state of Battery Preconditioning with Navigation setting";
CM_ SG_ 1035 STTEMCON "Battery Preconditioning functional information";
CM_ SG_ 1035 BPNTIM "Neccesarry Time for Battery Preconditioning";
CM_ SG_ 1035 BPNPC "Neccesarry Power Consumption for Battery Preconditioning";
CM_ BO_ 506 "Reserve";
CM_ SG_ 506 RNEC_MON "Renewal of Electricity Consumption";
CM_ SG_ 506 EC_MON "Electricity Consumption";
CM_ BO_ 1067 "Reserve";
CM_ SG_ 1067 ACINVSSW "Power outlets SW information";
CM_ SG_ 1067 SILUAEHV "Dynamically Specification Switching Unfinished Alert";
CM_ SG_ 1067 ACINVACT "Vehicle Inside AC Inverter outlet operation status";
CM_ BO_ 747 "Reserve";
CM_ SG_ 747 BTSTS "Battery temperature status";
CM_ BO_ 514 "Reserve";
CM_ SG_ 514 ENECRT1 "Energy Consumption Ratio item1";
CM_ SG_ 514 ENERTEX "Energy Consumption Ratio Display Existence";
CM_ SG_ 514 ENECRT2 "Energy Consumption Ratio item2";
CM_ SG_ 514 ENECRT3 "Energy Consumption Ratio item3";
CM_ SG_ 514 EVDSPEC "EV Range Display Electricity Cost";
CM_ BO_ 821 "Reserve";
CM_ SG_ 821 DREIMABN "Drive recorder(EIM) malfunction notification";
CM_ BO_ 164 "Reserve";
CM_ SG_ 164 AOR "Accelerator pedal angle";
CM_ SG_ 164 HV_ACCP "Accelerator pedal angle";
CM_ BO_ 453 "Reserve";
CM_ SG_ 453 VARENG1 "Engine type information 1";
CM_ SG_ 453 VARENG2 "Engine type information 2";
CM_ SG_ 453 VARENG3 "Engine type information 3";
CM_ SG_ 453 VARENG4 "Engine type information 4";
CM_ SG_ 453 DVINF "Drive train information";
CM_ SG_ 453 VARTRM1 "Transmission information";
CM_ SG_ 453 PTSYS "Power Train System";
CM_ SG_ 453 TF "Type of Fuel";
CM_ BO_ 1310 "Reserve";
CM_ SG_ 1310 RDYIND "READY signal";
CM_ SG_ 1310 B_ISNW "ECT SNOW indicator";
CM_ SG_ 1310 B_DMODE "Drive Mode Select Signal";
CM_ SG_ 1310 FSITRG "Full Screen Interrupt Trigger";
CM_ SG_ 1310 B_OMODE "Offroad Mode Select Signal";
CM_ SG_ 1310 FSIKIND "Full Screen Interrupt Kind";
CM_ SG_ 1310 FSILSTTP "Full Screen Interrupt List Type";
CM_ SG_ 1310 B_DMODE2 "Drive Mode Select Signal2";
CM_ SG_ 1310 B_DMSINF "Drive Mode Select Availability Mode Information";
CM_ SG_ 1310 B_DMSIF2 "Drive Mode Select Availability Mode Information2";
CM_ SG_ 1310 B_TMODE "Towing Mode Select Signal";
CM_ SG_ 1310 TOW_DISP "Towing Mode select information";
CM_ SG_ 1310 B_PDL1 "Strong Regenerative Mode Indicator";
CM_ SG_ 1310 MDSLTACT "Under Mode Select Control";
CM_ SG_ 1310 B_DMSSFT "Drive Mode Select Software switch existence";
CM_ SG_ 1310 B_DMINF2 "Drive Mode Select Availability Mode Information 2";
CM_ BO_ 252 "Reserve";
CM_ SG_ 252 B_STPE "Stop lamp switch";
CM_ SG_ 252 CHAW_BZR "charge warning buzzer request";
CM_ SG_ 252 CHAWID "charge warning ID";
CM_ SG_ 252 B_TOWINF "Towing Mode Select Availability Mode Information for Rotary SW";
CM_ SG_ 252 BOSLAMP "BOS Lamp Request";
CM_ SG_ 252 BOSMINF "BOS Multi Information Request";
CM_ SG_ 252 GOSMINF "GOS Multi Information Request";
CM_ SG_ 252 MSG_SFML "Shift system malfunction indication request";
CM_ SG_ 252 BZR_PT "Buzzer request powertrain ECU";
CM_ BO_ 1426 "Reserve";
CM_ SG_ 1426 VIN_1 "Vehicle Identification Number 1";
CM_ SG_ 1426 VIN_2 "Vehicle Identification Number 2";
CM_ SG_ 1426 VIN_3 "Vehicle Identification Number 3";
CM_ SG_ 1426 VIN_4 "Vehicle Identification Number 4";
CM_ SG_ 1426 VIN_5 "Vehicle Identification Number 5";
CM_ SG_ 1426 VIN_6 "Vehicle Identification Number 6";
CM_ SG_ 1426 VIN_7 "Vehicle Identification Number 7";
CM_ SG_ 1426 VIN_8 "Vehicle Identification Number 8";
CM_ SG_ 1426 VIN_9 "Vehicle Identification Number 9";
CM_ SG_ 1426 VIN_10 "Vehicle Identification Number 10";
CM_ SG_ 1426 VIN_11 "Vehicle Identification Number 11";
CM_ SG_ 1426 VIN_12 "Vehicle Identification Number 12";
CM_ SG_ 1426 VIN_13 "Vehicle Identification Number 13";
CM_ SG_ 1426 VIN_14 "Vehicle Identification Number 14";
CM_ SG_ 1426 VIN_15 "Vehicle Identification Number 15";
CM_ SG_ 1426 VIN_16 "Vehicle Identification Number 16";
CM_ SG_ 1426 VIN_17 "Vehicle Identification Number 17";
CM_ BO_ 98 "Reserve";
CM_ SG_ 98 TRQSENS "EPS torque sensor value";
CM_ SG_ 98 ST_TYP "Steering system type";
CM_ SG_ 98 PANG "Pinion angle";
CM_ SG_ 98 PANGV "Pinion angle velocity";
CM_ SG_ 98 PANGINV "Invalid flag of pinion angle";
CM_ SG_ 98 PANGFAIL "Abnormality flag of pinion angle";
CM_ SG_ 98 PANGVS "Pinion angle speed LSB enhancing signal";
CM_ SG_ 98 TRQSENSS "EPS torque sensor value LSB enhancing signal";
CM_ SG_ 98 EPSSATGF "Taget angle invalidation";
CM_ SG_ 98 EPSSATG "Target angle";
CM_ SG_ 98 EPSTRQ "EPS torque";
CM_ SG_ 98 SANGFAIL "Abnormality flag of steering angle";
CM_ SG_ 98 SANGINV "Invalid flag of steering angle";
CM_ SG_ 98 SANG "Steering angle";
CM_ SG_ 98 SANGV "Steering angle speed";
CM_ SG_ 98 STRDIFF "Difference value of steering midpoint";
CM_ BO_ 458 "Reserve";
CM_ SG_ 458 E_CRC1CA "EPS1S90 E2E_CRC";
CM_ SG_ 458 E_CNT1CA "EPS1S90 E2E_CNT";
CM_ SG_ 458 EPS_BZER "Demand Buzzer to Meter";
CM_ SG_ 458 EPS_WLMP "EPS W/L request";
CM_ SG_ 458 EPS_MINF "Multi Information Request";
CM_ SG_ 458 EPS_REMT "Remote service request";
CM_ BO_ 593 "Reserve";
CM_ SG_ 593 ACCEX "ACC existence";
CM_ SG_ 593 ACCID "ACC indicator";
CM_ SG_ 593 ACCCCSID "CCS indicator";
CM_ SG_ 593 ISAID "ISA indicator";
CM_ SG_ 593 ISALIMID "LIMIT indication";
CM_ SG_ 593 ACCSPU "Vehicle speed unit";
CM_ SG_ 593 ACCSPEXC "Vehicle speed excess";
CM_ SG_ 593 ACCSP "Control vehicle speed";
CM_ SG_ 593 ACCSPST1 "Control vehicle speed state 1(color)";
CM_ SG_ 593 ACCSUST1 "Vehicle speed unit1 (color)";
CM_ SG_ 593 ERMMAXID "ERM MAX indication";
CM_ SG_ 593 ACCDST "Following distance time";
CM_ SG_ 593 ACCDTST1 "Following distance time state 1(color)";
CM_ SG_ 593 ACCDTST2 "Following distance time state 2(blinking)";
CM_ SG_ 593 ERMID "ERM indicator";
CM_ SG_ 593 MODEEX "MODE existence";
CM_ BO_ 602 "Reserve";
CM_ SG_ 602 OTHAHCON "Construction on the road ahead Flag";
CM_ SG_ 602 OTHINCON "Inside construction Flag";
CM_ SG_ 602 SRP_PRE "Presence/absence of Signal Road Projection";
CM_ SG_ 602 SRP_IND "Signal Road Projection Indicator Request";
CM_ SG_ 602 AHSSWVST "AHS Swivel Function customization status";
CM_ SG_ 602 AHSSWVEX "AHS Swivel Function customization display request";
CM_ SG_ 602 AHSSDEST "AHS Shading Edge customization status";
CM_ SG_ 602 AHSSDEEX "AHS Shading Edge customization display request";
CM_ SG_ 602 A_LMP_ST "Head Lamp System Indicator";
CM_ SG_ 602 A_HLLI "Head Lamp Leveling Indicator";
CM_ SG_ 602 A_BW_IND "Bad Weather Indicator Request";
CM_ SG_ 602 A_BW_PRE "Bad Weather Exist";
CM_ SG_ 602 AH_IND_S "AHS Shading Indicator";
CM_ SG_ 602 AHSACTST "AHS ON/OFF Function customization status";
CM_ SG_ 602 AHSACTEX "AHS ON/OFF Function customization display request";
CM_ SG_ 602 AHBACTST "AHB ON/OFF Function customization status";
CM_ SG_ 602 AHBACTEX "AHB ON/OFF Function customization display request";
CM_ BO_ 346 "Reserve";
CM_ SG_ 346 OTHFRILL "Front brightness";
CM_ BO_ 256 "Reserve";
CM_ SG_ 256 OTHSOR "Sky occupancy rate";
CM_ SG_ 256 OTHROR "Road occupancy rate";
CM_ SG_ 256 OTHLX "Illuminance around vehicle";
CM_ SG_ 256 OTHSOLAR "Relative value with solar radiation";
CM_ BO_ 434 "Reserve";
CM_ SG_ 434 XREQFPB "FPB Request Flag(DDR)";
CM_ SG_ 434 XREQPB "PB Request Flag(DDR)";
CM_ SG_ 434 XREQPBH "PBH Request Flag(DDR)";
CM_ BO_ 1015 "Reserve";
CM_ SG_ 1015 HUD_ST "State Signal of HUD";
CM_ BO_ 1587 "Reserve";
CM_ SG_ 1587 BZDN3 "Meter Buzzer intermittence request(0.4sec cycle)";
CM_ SG_ 1587 BZDN2 "Meter Buzzer intermittence request(0.7sec cycle)";
CM_ SG_ 1587 BZ "Meter buzzer single-shot request";
CM_ SG_ 1587 BZDN "Meter Buzzer intermittence request";
CM_ SG_ 1587 NSPB "Meter buzzer continuation request";
CM_ SG_ 1587 D_SWR1 "Digital Key System warning 1";
CM_ SG_ 1587 BZ2 "Imobilizer Key Identification Completion";
CM_ SG_ 1587 SWR3 "Smart system warning 3";
CM_ SG_ 1587 SWR2 "Smart system warning 2";
CM_ SG_ 1587 SWR1 "Smart system warning 1";
BA_DEF_ BO_  "GenMsgILSupport" ENUM  "No","Yes";
BA_DEF_ BO_  "GenMsgSendType" ENUM  "Cyclic","NotUsed","NotUsed","NotUsed","NotUsed","NotUsed","NotUsed","NotUsed","NoMsgSendType";
BA_DEF_ SG_  "GenSigSendType" ENUM  "Cyclic","OnWrite","OnWriteWithRepetition","OnChange","OnChangeWithRepetition","NotUsed","NotUsed","NoSigSendType";
BA_DEF_ BO_  "GenMsgCycleTime" INT 0 65535;
BA_DEF_ SG_  "GenSigStartValue" FLOAT 0 100000000000;
BA_DEF_ BO_  "GenMsgStartDelayTime" INT 0 100000;
BA_DEF_ BO_  "VFrameFormat" ENUM  "StandardCAN","ExtendedCAN","reserved","reserved","reserved","reserved","reserved","reserved","reserved","reserved","reserved","reserved","reserved","reserved","StandardCAN_FD","ExtendedCAN_FD";
BA_DEF_ BO_  "CANFD_BRS" ENUM  "0","1";
BA_DEF_ BO_  "NmAsrMessage" ENUM  "No","Yes";
BA_DEF_ BO_  "DiagState" ENUM  "No","Yes";
BA_DEF_ BO_  "DiagRequest" ENUM  "No","Yes";
BA_DEF_ BO_  "DiagResponse" ENUM  "No","Yes";
BA_DEF_ BO_  "DiagConnection" HEX 0 65535;
BA_DEF_ SG_  "SystemSignalLongSymbol" STRING ;
BA_DEF_DEF_  "GenMsgILSupport" "No";
BA_DEF_DEF_  "GenMsgSendType" "NoMsgSendType";
BA_DEF_DEF_  "GenSigSendType" "NoSigSendType";
BA_DEF_DEF_  "GenMsgCycleTime" 0;
BA_DEF_DEF_  "GenSigStartValue" 0;
BA_DEF_DEF_  "GenMsgStartDelayTime" 0;
BA_DEF_DEF_  "VFrameFormat" "";
BA_DEF_DEF_  "CANFD_BRS" "1";
BA_DEF_DEF_  "NmAsrMessage" "No";
BA_DEF_DEF_  "DiagState" "No";
BA_DEF_DEF_  "DiagRequest" "No";
BA_DEF_DEF_  "DiagResponse" "No";
BA_DEF_DEF_  "DiagConnection" 3000.00005758105;
BA_DEF_DEF_  "SystemSignalLongSymbol" "";
BA_ "GenMsgILSupport" BO_ 1570 1;
BA_ "GenMsgSendType" BO_ 1570 0;
BA_ "GenMsgCycleTime" BO_ 1570 1000;
BA_ "VFrameFormat" BO_ 1570 14;
BA_ "GenMsgILSupport" BO_ 1571 1;
BA_ "GenMsgSendType" BO_ 1571 0;
BA_ "GenMsgCycleTime" BO_ 1571 1000;
BA_ "VFrameFormat" BO_ 1571 14;
BA_ "GenMsgILSupport" BO_ 896 1;
BA_ "GenMsgSendType" BO_ 896 0;
BA_ "GenMsgCycleTime" BO_ 896 1000;
BA_ "VFrameFormat" BO_ 896 14;
BA_ "GenMsgILSupport" BO_ 1572 1;
BA_ "GenMsgSendType" BO_ 1572 0;
BA_ "GenMsgCycleTime" BO_ 1572 1000;
BA_ "VFrameFormat" BO_ 1572 14;
BA_ "GenMsgILSupport" BO_ 1574 1;
BA_ "GenMsgSendType" BO_ 1574 0;
BA_ "GenMsgCycleTime" BO_ 1574 1000;
BA_ "VFrameFormat" BO_ 1574 14;
BA_ "GenMsgILSupport" BO_ 1580 1;
BA_ "VFrameFormat" BO_ 1580 14;
BA_ "GenMsgILSupport" BO_ 1020 1;
BA_ "GenMsgSendType" BO_ 1020 0;
BA_ "GenMsgCycleTime" BO_ 1020 50;
BA_ "VFrameFormat" BO_ 1020 14;
BA_ "GenMsgILSupport" BO_ 774 1;
BA_ "GenMsgSendType" BO_ 774 0;
BA_ "GenMsgCycleTime" BO_ 774 1000;
BA_ "VFrameFormat" BO_ 774 14;
BA_ "GenMsgILSupport" BO_ 773 1;
BA_ "GenMsgSendType" BO_ 773 0;
BA_ "GenMsgCycleTime" BO_ 773 1000;
BA_ "VFrameFormat" BO_ 773 14;
BA_ "GenMsgILSupport" BO_ 1577 1;
BA_ "GenMsgSendType" BO_ 1577 0;
BA_ "GenMsgCycleTime" BO_ 1577 1000;
BA_ "VFrameFormat" BO_ 1577 14;
BA_ "GenMsgILSupport" BO_ 1578 1;
BA_ "GenMsgSendType" BO_ 1578 0;
BA_ "GenMsgCycleTime" BO_ 1578 1000;
BA_ "VFrameFormat" BO_ 1578 14;
BA_ "GenMsgILSupport" BO_ 919 1;
BA_ "GenMsgSendType" BO_ 919 0;
BA_ "GenMsgCycleTime" BO_ 919 1000;
BA_ "VFrameFormat" BO_ 919 14;
BA_ "GenMsgILSupport" BO_ 949 1;
BA_ "GenMsgSendType" BO_ 949 0;
BA_ "GenMsgCycleTime" BO_ 949 1000;
BA_ "VFrameFormat" BO_ 949 14;
BA_ "GenMsgILSupport" BO_ 952 1;
BA_ "GenMsgSendType" BO_ 952 0;
BA_ "GenMsgCycleTime" BO_ 952 1000;
BA_ "VFrameFormat" BO_ 952 14;
BA_ "GenMsgILSupport" BO_ 786 1;
BA_ "GenMsgSendType" BO_ 786 0;
BA_ "GenMsgCycleTime" BO_ 786 1000;
BA_ "VFrameFormat" BO_ 786 14;
BA_ "GenMsgILSupport" BO_ 800 1;
BA_ "GenMsgSendType" BO_ 800 0;
BA_ "GenMsgCycleTime" BO_ 800 1000;
BA_ "VFrameFormat" BO_ 800 14;
BA_ "GenMsgILSupport" BO_ 810 1;
BA_ "GenMsgSendType" BO_ 810 0;
BA_ "GenMsgCycleTime" BO_ 810 1000;
BA_ "VFrameFormat" BO_ 810 14;
BA_ "GenMsgILSupport" BO_ 892 1;
BA_ "GenMsgSendType" BO_ 892 0;
BA_ "GenMsgCycleTime" BO_ 892 1000;
BA_ "VFrameFormat" BO_ 892 14;
BA_ "GenMsgILSupport" BO_ 320 1;
BA_ "VFrameFormat" BO_ 320 14;
BA_ "GenMsgILSupport" BO_ 390 1;
BA_ "GenMsgSendType" BO_ 390 0;
BA_ "GenMsgCycleTime" BO_ 390 100;
BA_ "VFrameFormat" BO_ 390 14;
BA_ "GenMsgILSupport" BO_ 466 1;
BA_ "GenMsgSendType" BO_ 466 0;
BA_ "GenMsgCycleTime" BO_ 466 300;
BA_ "VFrameFormat" BO_ 466 14;
BA_ "GenMsgILSupport" BO_ 328 1;
BA_ "GenMsgSendType" BO_ 328 0;
BA_ "GenMsgCycleTime" BO_ 328 100;
BA_ "VFrameFormat" BO_ 328 14;
BA_ "GenMsgILSupport" BO_ 868 1;
BA_ "GenMsgSendType" BO_ 868 0;
BA_ "GenMsgCycleTime" BO_ 868 1000;
BA_ "VFrameFormat" BO_ 868 14;
BA_ "GenMsgILSupport" BO_ 467 1;
BA_ "GenMsgSendType" BO_ 467 0;
BA_ "GenMsgCycleTime" BO_ 467 300;
BA_ "VFrameFormat" BO_ 467 14;
BA_ "GenMsgILSupport" BO_ 823 1;
BA_ "GenMsgSendType" BO_ 823 0;
BA_ "GenMsgCycleTime" BO_ 823 1000;
BA_ "VFrameFormat" BO_ 823 14;
BA_ "GenMsgILSupport" BO_ 19 1;
BA_ "VFrameFormat" BO_ 19 14;
BA_ "GenMsgILSupport" BO_ 27 1;
BA_ "VFrameFormat" BO_ 27 14;
BA_ "GenMsgILSupport" BO_ 833 1;
BA_ "GenMsgSendType" BO_ 833 0;
BA_ "GenMsgCycleTime" BO_ 833 1000;
BA_ "VFrameFormat" BO_ 833 14;
BA_ "GenMsgILSupport" BO_ 483 1;
BA_ "GenMsgSendType" BO_ 483 0;
BA_ "GenMsgCycleTime" BO_ 483 300;
BA_ "VFrameFormat" BO_ 483 14;
BA_ "GenMsgILSupport" BO_ 871 1;
BA_ "GenMsgSendType" BO_ 871 0;
BA_ "GenMsgCycleTime" BO_ 871 1000;
BA_ "VFrameFormat" BO_ 871 14;
BA_ "GenMsgILSupport" BO_ 853 1;
BA_ "GenMsgSendType" BO_ 853 0;
BA_ "GenMsgCycleTime" BO_ 853 1000;
BA_ "VFrameFormat" BO_ 853 14;
BA_ "GenMsgILSupport" BO_ 856 1;
BA_ "GenMsgSendType" BO_ 856 0;
BA_ "GenMsgCycleTime" BO_ 856 1000;
BA_ "VFrameFormat" BO_ 856 14;
BA_ "GenMsgILSupport" BO_ 861 1;
BA_ "GenMsgSendType" BO_ 861 0;
BA_ "GenMsgCycleTime" BO_ 861 1000;
BA_ "VFrameFormat" BO_ 861 14;
BA_ "GenMsgILSupport" BO_ 420 1;
BA_ "GenMsgSendType" BO_ 420 0;
BA_ "GenMsgCycleTime" BO_ 420 200;
BA_ "VFrameFormat" BO_ 420 14;
BA_ "GenMsgILSupport" BO_ 863 1;
BA_ "GenMsgSendType" BO_ 863 0;
BA_ "GenMsgCycleTime" BO_ 863 1000;
BA_ "VFrameFormat" BO_ 863 14;
BA_ "GenMsgILSupport" BO_ 915 1;
BA_ "GenMsgSendType" BO_ 915 0;
BA_ "GenMsgCycleTime" BO_ 915 1000;
BA_ "VFrameFormat" BO_ 915 14;
BA_ "GenMsgILSupport" BO_ 917 1;
BA_ "GenMsgSendType" BO_ 917 0;
BA_ "GenMsgCycleTime" BO_ 917 1000;
BA_ "VFrameFormat" BO_ 917 14;
BA_ "GenMsgILSupport" BO_ 918 1;
BA_ "GenMsgSendType" BO_ 918 0;
BA_ "GenMsgCycleTime" BO_ 918 1000;
BA_ "VFrameFormat" BO_ 918 14;
BA_ "GenMsgILSupport" BO_ 922 1;
BA_ "GenMsgSendType" BO_ 922 0;
BA_ "GenMsgCycleTime" BO_ 922 1000;
BA_ "VFrameFormat" BO_ 922 14;
BA_ "GenMsgILSupport" BO_ 923 1;
BA_ "GenMsgSendType" BO_ 923 0;
BA_ "GenMsgCycleTime" BO_ 923 1000;
BA_ "VFrameFormat" BO_ 923 14;
BA_ "GenMsgILSupport" BO_ 925 1;
BA_ "GenMsgSendType" BO_ 925 0;
BA_ "GenMsgCycleTime" BO_ 925 1000;
BA_ "VFrameFormat" BO_ 925 14;
BA_ "GenMsgILSupport" BO_ 926 1;
BA_ "GenMsgSendType" BO_ 926 0;
BA_ "GenMsgCycleTime" BO_ 926 1000;
BA_ "VFrameFormat" BO_ 926 14;
BA_ "GenMsgILSupport" BO_ 927 1;
BA_ "GenMsgSendType" BO_ 927 0;
BA_ "GenMsgCycleTime" BO_ 927 1000;
BA_ "VFrameFormat" BO_ 927 14;
BA_ "GenMsgILSupport" BO_ 933 1;
BA_ "GenMsgSendType" BO_ 933 0;
BA_ "GenMsgCycleTime" BO_ 933 1000;
BA_ "VFrameFormat" BO_ 933 14;
BA_ "GenMsgILSupport" BO_ 940 1;
BA_ "GenMsgSendType" BO_ 940 0;
BA_ "GenMsgCycleTime" BO_ 940 1000;
BA_ "VFrameFormat" BO_ 940 14;
BA_ "GenMsgILSupport" BO_ 942 1;
BA_ "GenMsgSendType" BO_ 942 0;
BA_ "GenMsgCycleTime" BO_ 942 1000;
BA_ "VFrameFormat" BO_ 942 14;
BA_ "GenMsgILSupport" BO_ 946 1;
BA_ "GenMsgSendType" BO_ 946 0;
BA_ "GenMsgCycleTime" BO_ 946 1000;
BA_ "VFrameFormat" BO_ 946 14;
BA_ "GenMsgILSupport" BO_ 947 1;
BA_ "GenMsgSendType" BO_ 947 0;
BA_ "GenMsgCycleTime" BO_ 947 1000;
BA_ "VFrameFormat" BO_ 947 14;
BA_ "GenMsgILSupport" BO_ 953 1;
BA_ "GenMsgSendType" BO_ 953 0;
BA_ "GenMsgCycleTime" BO_ 953 1000;
BA_ "VFrameFormat" BO_ 953 14;
BA_ "GenMsgILSupport" BO_ 956 1;
BA_ "GenMsgSendType" BO_ 956 0;
BA_ "GenMsgCycleTime" BO_ 956 1000;
BA_ "VFrameFormat" BO_ 956 14;
BA_ "GenMsgILSupport" BO_ 966 1;
BA_ "GenMsgSendType" BO_ 966 0;
BA_ "GenMsgCycleTime" BO_ 966 1000;
BA_ "VFrameFormat" BO_ 966 14;
BA_ "GenMsgILSupport" BO_ 967 1;
BA_ "GenMsgSendType" BO_ 967 0;
BA_ "GenMsgCycleTime" BO_ 967 1000;
BA_ "VFrameFormat" BO_ 967 14;
BA_ "GenMsgILSupport" BO_ 973 1;
BA_ "GenMsgSendType" BO_ 973 0;
BA_ "GenMsgCycleTime" BO_ 973 1000;
BA_ "VFrameFormat" BO_ 973 14;
BA_ "GenMsgILSupport" BO_ 979 1;
BA_ "GenMsgSendType" BO_ 979 0;
BA_ "GenMsgCycleTime" BO_ 979 1000;
BA_ "VFrameFormat" BO_ 979 14;
BA_ "GenMsgILSupport" BO_ 982 1;
BA_ "GenMsgSendType" BO_ 982 0;
BA_ "GenMsgCycleTime" BO_ 982 1000;
BA_ "VFrameFormat" BO_ 982 14;
BA_ "GenMsgILSupport" BO_ 989 1;
BA_ "GenMsgSendType" BO_ 989 0;
BA_ "GenMsgCycleTime" BO_ 989 1000;
BA_ "VFrameFormat" BO_ 989 14;
BA_ "GenMsgILSupport" BO_ 993 1;
BA_ "GenMsgSendType" BO_ 993 0;
BA_ "GenMsgCycleTime" BO_ 993 1000;
BA_ "VFrameFormat" BO_ 993 14;
BA_ "GenMsgILSupport" BO_ 1003 1;
BA_ "GenMsgSendType" BO_ 1003 0;
BA_ "GenMsgCycleTime" BO_ 1003 1000;
BA_ "VFrameFormat" BO_ 1003 14;
BA_ "GenMsgILSupport" BO_ 1007 1;
BA_ "GenMsgSendType" BO_ 1007 0;
BA_ "GenMsgCycleTime" BO_ 1007 1000;
BA_ "VFrameFormat" BO_ 1007 14;
BA_ "GenMsgILSupport" BO_ 1013 1;
BA_ "GenMsgSendType" BO_ 1013 0;
BA_ "GenMsgCycleTime" BO_ 1013 1000;
BA_ "VFrameFormat" BO_ 1013 14;
BA_ "GenMsgILSupport" BO_ 1059 1;
BA_ "GenMsgSendType" BO_ 1059 0;
BA_ "GenMsgCycleTime" BO_ 1059 1000;
BA_ "VFrameFormat" BO_ 1059 14;
BA_ "GenMsgILSupport" BO_ 1065 1;
BA_ "GenMsgSendType" BO_ 1065 0;
BA_ "GenMsgCycleTime" BO_ 1065 1000;
BA_ "VFrameFormat" BO_ 1065 14;
BA_ "GenMsgILSupport" BO_ 1072 1;
BA_ "GenMsgSendType" BO_ 1072 0;
BA_ "GenMsgCycleTime" BO_ 1072 1000;
BA_ "VFrameFormat" BO_ 1072 14;
BA_ "GenMsgILSupport" BO_ 1152 1;
BA_ "GenMsgSendType" BO_ 1152 0;
BA_ "GenMsgCycleTime" BO_ 1152 1000;
BA_ "VFrameFormat" BO_ 1152 14;
BA_ "GenMsgILSupport" BO_ 1156 1;
BA_ "GenMsgSendType" BO_ 1156 0;
BA_ "GenMsgCycleTime" BO_ 1156 1000;
BA_ "VFrameFormat" BO_ 1156 14;
BA_ "GenMsgILSupport" BO_ 1169 1;
BA_ "GenMsgSendType" BO_ 1169 0;
BA_ "GenMsgCycleTime" BO_ 1169 1000;
BA_ "VFrameFormat" BO_ 1169 14;
BA_ "GenMsgILSupport" BO_ 1175 1;
BA_ "GenMsgSendType" BO_ 1175 0;
BA_ "GenMsgCycleTime" BO_ 1175 1000;
BA_ "VFrameFormat" BO_ 1175 14;
BA_ "GenMsgILSupport" BO_ 1318 1;
BA_ "GenMsgSendType" BO_ 1318 0;
BA_ "GenMsgCycleTime" BO_ 1318 1000;
BA_ "VFrameFormat" BO_ 1318 14;
BA_ "GenMsgILSupport" BO_ 1323 1;
BA_ "GenMsgSendType" BO_ 1323 0;
BA_ "GenMsgCycleTime" BO_ 1323 1000;
BA_ "VFrameFormat" BO_ 1323 14;
BA_ "GenMsgILSupport" BO_ 1324 1;
BA_ "GenMsgSendType" BO_ 1324 0;
BA_ "GenMsgCycleTime" BO_ 1324 1000;
BA_ "VFrameFormat" BO_ 1324 14;
BA_ "GenMsgILSupport" BO_ 1328 1;
BA_ "GenMsgSendType" BO_ 1328 0;
BA_ "GenMsgCycleTime" BO_ 1328 1000;
BA_ "VFrameFormat" BO_ 1328 14;
BA_ "GenMsgILSupport" BO_ 1329 1;
BA_ "GenMsgSendType" BO_ 1329 0;
BA_ "GenMsgCycleTime" BO_ 1329 1000;
BA_ "VFrameFormat" BO_ 1329 14;
BA_ "GenMsgILSupport" BO_ 1332 1;
BA_ "GenMsgSendType" BO_ 1332 0;
BA_ "GenMsgCycleTime" BO_ 1332 1000;
BA_ "VFrameFormat" BO_ 1332 14;
BA_ "GenMsgILSupport" BO_ 1333 1;
BA_ "GenMsgSendType" BO_ 1333 0;
BA_ "GenMsgCycleTime" BO_ 1333 1000;
BA_ "VFrameFormat" BO_ 1333 14;
BA_ "GenMsgILSupport" BO_ 1335 1;
BA_ "GenMsgSendType" BO_ 1335 0;
BA_ "GenMsgCycleTime" BO_ 1335 1000;
BA_ "VFrameFormat" BO_ 1335 14;
BA_ "GenMsgILSupport" BO_ 1336 1;
BA_ "GenMsgSendType" BO_ 1336 0;
BA_ "GenMsgCycleTime" BO_ 1336 1000;
BA_ "VFrameFormat" BO_ 1336 14;
BA_ "GenMsgILSupport" BO_ 691 1;
BA_ "GenMsgSendType" BO_ 691 0;
BA_ "GenMsgCycleTime" BO_ 691 1000;
BA_ "VFrameFormat" BO_ 691 14;
BA_ "GenMsgILSupport" BO_ 1157 1;
BA_ "GenMsgSendType" BO_ 1157 0;
BA_ "GenMsgCycleTime" BO_ 1157 1000;
BA_ "VFrameFormat" BO_ 1157 14;
BA_ "GenMsgILSupport" BO_ 1084 1;
BA_ "GenMsgSendType" BO_ 1084 0;
BA_ "GenMsgCycleTime" BO_ 1084 1000;
BA_ "VFrameFormat" BO_ 1084 14;
BA_ "GenMsgILSupport" BO_ 1158 1;
BA_ "GenMsgSendType" BO_ 1158 0;
BA_ "GenMsgCycleTime" BO_ 1158 1000;
BA_ "VFrameFormat" BO_ 1158 14;
BA_ "GenMsgILSupport" BO_ 891 1;
BA_ "GenMsgSendType" BO_ 891 0;
BA_ "GenMsgCycleTime" BO_ 891 1000;
BA_ "VFrameFormat" BO_ 891 14;
BA_ "GenMsgILSupport" BO_ 397 1;
BA_ "GenMsgSendType" BO_ 397 0;
BA_ "GenMsgCycleTime" BO_ 397 100;
BA_ "VFrameFormat" BO_ 397 14;
BA_ "GenMsgILSupport" BO_ 410 1;
BA_ "GenMsgSendType" BO_ 410 0;
BA_ "GenMsgCycleTime" BO_ 410 200;
BA_ "VFrameFormat" BO_ 410 14;
BA_ "GenMsgILSupport" BO_ 971 1;
BA_ "GenMsgSendType" BO_ 971 0;
BA_ "GenMsgCycleTime" BO_ 971 1000;
BA_ "VFrameFormat" BO_ 971 14;
BA_ "GenMsgILSupport" BO_ 939 1;
BA_ "GenMsgSendType" BO_ 939 0;
BA_ "GenMsgCycleTime" BO_ 939 1000;
BA_ "VFrameFormat" BO_ 939 14;
BA_ "GenMsgILSupport" BO_ 1014 1;
BA_ "GenMsgSendType" BO_ 1014 0;
BA_ "GenMsgCycleTime" BO_ 1014 1000;
BA_ "VFrameFormat" BO_ 1014 14;
BA_ "GenMsgILSupport" BO_ 565 1;
BA_ "GenMsgSendType" BO_ 565 0;
BA_ "GenMsgCycleTime" BO_ 565 1000;
BA_ "VFrameFormat" BO_ 565 14;
BA_ "GenMsgILSupport" BO_ 687 1;
BA_ "GenMsgSendType" BO_ 687 0;
BA_ "GenMsgCycleTime" BO_ 687 1000;
BA_ "VFrameFormat" BO_ 687 14;
BA_ "NmAsrMessage" BO_ 1090 1;
BA_ "VFrameFormat" BO_ 1090 0;
BA_ "GenMsgSendType" BO_ 1090 0;
BA_ "GenMsgCycleTime" BO_ 1090 1000;
BA_ "GenMsgStartDelayTime" BO_ 819 228;
BA_ "GenMsgILSupport" BO_ 819 1;
BA_ "GenMsgSendType" BO_ 819 0;
BA_ "GenMsgCycleTime" BO_ 819 1000;
BA_ "VFrameFormat" BO_ 819 14;
BA_ "GenMsgStartDelayTime" BO_ 820 232;
BA_ "GenMsgILSupport" BO_ 820 1;
BA_ "GenMsgSendType" BO_ 820 0;
BA_ "GenMsgCycleTime" BO_ 820 1000;
BA_ "VFrameFormat" BO_ 820 14;
BA_ "GenMsgStartDelayTime" BO_ 849 236;
BA_ "GenMsgILSupport" BO_ 849 1;
BA_ "GenMsgSendType" BO_ 849 0;
BA_ "GenMsgCycleTime" BO_ 849 1000;
BA_ "VFrameFormat" BO_ 849 14;
BA_ "GenMsgILSupport" BO_ 473 1;
BA_ "GenMsgSendType" BO_ 473 0;
BA_ "GenMsgCycleTime" BO_ 473 300;
BA_ "VFrameFormat" BO_ 473 14;
BA_ "GenMsgILSupport" BO_ 755 1;
BA_ "GenMsgSendType" BO_ 755 0;
BA_ "GenMsgCycleTime" BO_ 755 1000;
BA_ "VFrameFormat" BO_ 755 14;
BA_ "GenMsgILSupport" BO_ 1080 1;
BA_ "GenMsgSendType" BO_ 1080 0;
BA_ "GenMsgCycleTime" BO_ 1080 1000;
BA_ "VFrameFormat" BO_ 1080 14;
BA_ "GenMsgILSupport" BO_ 847 1;
BA_ "GenMsgSendType" BO_ 847 0;
BA_ "GenMsgCycleTime" BO_ 847 1000;
BA_ "VFrameFormat" BO_ 847 14;
BA_ "GenMsgILSupport" BO_ 867 1;
BA_ "VFrameFormat" BO_ 867 14;
BA_ "GenMsgILSupport" BO_ 840 1;
BA_ "GenMsgSendType" BO_ 840 0;
BA_ "GenMsgCycleTime" BO_ 840 1000;
BA_ "VFrameFormat" BO_ 840 14;
BA_ "GenMsgILSupport" BO_ 184 1;
BA_ "GenMsgSendType" BO_ 184 0;
BA_ "GenMsgCycleTime" BO_ 184 30;
BA_ "VFrameFormat" BO_ 184 14;
BA_ "GenMsgILSupport" BO_ 750 1;
BA_ "GenMsgSendType" BO_ 750 0;
BA_ "GenMsgCycleTime" BO_ 750 1000;
BA_ "VFrameFormat" BO_ 750 14;
BA_ "GenMsgILSupport" BO_ 471 1;
BA_ "GenMsgSendType" BO_ 471 0;
BA_ "GenMsgCycleTime" BO_ 471 300;
BA_ "VFrameFormat" BO_ 471 14;
BA_ "GenMsgILSupport" BO_ 730 1;
BA_ "GenMsgSendType" BO_ 730 0;
BA_ "GenMsgCycleTime" BO_ 730 1000;
BA_ "VFrameFormat" BO_ 730 14;
BA_ "GenMsgILSupport" BO_ 741 1;
BA_ "GenMsgSendType" BO_ 741 0;
BA_ "GenMsgCycleTime" BO_ 741 1000;
BA_ "VFrameFormat" BO_ 741 14;
BA_ "GenMsgILSupport" BO_ 641 1;
BA_ "GenMsgSendType" BO_ 641 0;
BA_ "GenMsgCycleTime" BO_ 641 1000;
BA_ "VFrameFormat" BO_ 641 14;
BA_ "GenMsgILSupport" BO_ 642 1;
BA_ "GenMsgSendType" BO_ 642 0;
BA_ "GenMsgCycleTime" BO_ 642 1000;
BA_ "VFrameFormat" BO_ 642 14;
BA_ "GenMsgILSupport" BO_ 1320 1;
BA_ "VFrameFormat" BO_ 1320 14;
BA_ "GenMsgILSupport" BO_ 290 1;
BA_ "GenMsgSendType" BO_ 290 0;
BA_ "GenMsgCycleTime" BO_ 290 100;
BA_ "VFrameFormat" BO_ 290 14;
BA_ "GenMsgStartDelayTime" BO_ 1063 240;
BA_ "GenMsgILSupport" BO_ 1063 1;
BA_ "GenMsgSendType" BO_ 1063 0;
BA_ "GenMsgCycleTime" BO_ 1063 1000;
BA_ "VFrameFormat" BO_ 1063 14;
BA_ "GenMsgILSupport" BO_ 958 1;
BA_ "GenMsgSendType" BO_ 958 0;
BA_ "GenMsgCycleTime" BO_ 958 1000;
BA_ "VFrameFormat" BO_ 958 14;
BA_ "GenMsgILSupport" BO_ 943 1;
BA_ "GenMsgSendType" BO_ 943 0;
BA_ "GenMsgCycleTime" BO_ 943 1000;
BA_ "VFrameFormat" BO_ 943 14;
BA_ "GenMsgILSupport" BO_ 645 1;
BA_ "GenMsgSendType" BO_ 645 0;
BA_ "GenMsgCycleTime" BO_ 645 1000;
BA_ "VFrameFormat" BO_ 645 14;
BA_ "GenMsgILSupport" BO_ 791 1;
BA_ "GenMsgSendType" BO_ 791 0;
BA_ "GenMsgCycleTime" BO_ 791 1000;
BA_ "VFrameFormat" BO_ 791 14;
BA_ "GenMsgILSupport" BO_ 1544 1;
BA_ "GenMsgSendType" BO_ 1544 0;
BA_ "GenMsgCycleTime" BO_ 1544 1000;
BA_ "VFrameFormat" BO_ 1544 14;
BA_ "GenMsgILSupport" BO_ 1041 1;
BA_ "GenMsgSendType" BO_ 1041 0;
BA_ "GenMsgCycleTime" BO_ 1041 1000;
BA_ "VFrameFormat" BO_ 1041 14;
BA_ "GenMsgILSupport" BO_ 1042 1;
BA_ "GenMsgSendType" BO_ 1042 0;
BA_ "GenMsgCycleTime" BO_ 1042 1000;
BA_ "VFrameFormat" BO_ 1042 14;
BA_ "GenMsgILSupport" BO_ 1008 1;
BA_ "GenMsgSendType" BO_ 1008 0;
BA_ "GenMsgCycleTime" BO_ 1008 1000;
BA_ "VFrameFormat" BO_ 1008 14;
BA_ "GenMsgILSupport" BO_ 1184 1;
BA_ "GenMsgSendType" BO_ 1184 0;
BA_ "GenMsgCycleTime" BO_ 1184 500;
BA_ "VFrameFormat" BO_ 1184 14;
BA_ "GenMsgILSupport" BO_ 959 1;
BA_ "GenMsgSendType" BO_ 959 0;
BA_ "GenMsgCycleTime" BO_ 959 1000;
BA_ "VFrameFormat" BO_ 959 14;
BA_ "GenMsgILSupport" BO_ 1025 1;
BA_ "GenMsgSendType" BO_ 1025 0;
BA_ "GenMsgCycleTime" BO_ 1025 1024;
BA_ "VFrameFormat" BO_ 1025 14;
BA_ "GenMsgILSupport" BO_ 444 1;
BA_ "GenMsgSendType" BO_ 444 0;
BA_ "GenMsgCycleTime" BO_ 444 200;
BA_ "VFrameFormat" BO_ 444 14;
BA_ "GenMsgILSupport" BO_ 296 1;
BA_ "GenMsgSendType" BO_ 296 0;
BA_ "GenMsgCycleTime" BO_ 296 100;
BA_ "VFrameFormat" BO_ 296 14;
BA_ "GenMsgILSupport" BO_ 464 1;
BA_ "GenMsgSendType" BO_ 464 0;
BA_ "GenMsgCycleTime" BO_ 464 300;
BA_ "VFrameFormat" BO_ 464 14;
BA_ "GenMsgILSupport" BO_ 1071 1;
BA_ "GenMsgSendType" BO_ 1071 0;
BA_ "GenMsgCycleTime" BO_ 1071 1000;
BA_ "VFrameFormat" BO_ 1071 14;
BA_ "GenMsgILSupport" BO_ 805 1;
BA_ "GenMsgSendType" BO_ 805 0;
BA_ "GenMsgCycleTime" BO_ 805 1000;
BA_ "VFrameFormat" BO_ 805 14;
BA_ "GenMsgILSupport" BO_ 950 1;
BA_ "GenMsgSendType" BO_ 950 0;
BA_ "GenMsgCycleTime" BO_ 950 1000;
BA_ "VFrameFormat" BO_ 950 14;
BA_ "GenMsgILSupport" BO_ 1057 1;
BA_ "GenMsgSendType" BO_ 1057 0;
BA_ "GenMsgCycleTime" BO_ 1057 1000;
BA_ "VFrameFormat" BO_ 1057 14;
BA_ "GenMsgILSupport" BO_ 1035 1;
BA_ "GenMsgSendType" BO_ 1035 0;
BA_ "GenMsgCycleTime" BO_ 1035 1000;
BA_ "VFrameFormat" BO_ 1035 14;
BA_ "GenMsgILSupport" BO_ 506 1;
BA_ "GenMsgSendType" BO_ 506 0;
BA_ "GenMsgCycleTime" BO_ 506 500;
BA_ "VFrameFormat" BO_ 506 14;
BA_ "GenMsgILSupport" BO_ 1067 1;
BA_ "GenMsgSendType" BO_ 1067 0;
BA_ "GenMsgCycleTime" BO_ 1067 1000;
BA_ "VFrameFormat" BO_ 1067 14;
BA_ "GenMsgILSupport" BO_ 747 1;
BA_ "GenMsgSendType" BO_ 747 0;
BA_ "GenMsgCycleTime" BO_ 747 1000;
BA_ "VFrameFormat" BO_ 747 14;
BA_ "GenMsgILSupport" BO_ 514 1;
BA_ "GenMsgSendType" BO_ 514 0;
BA_ "GenMsgCycleTime" BO_ 514 1000;
BA_ "VFrameFormat" BO_ 514 14;
BA_ "GenMsgILSupport" BO_ 821 1;
BA_ "GenMsgSendType" BO_ 821 0;
BA_ "GenMsgCycleTime" BO_ 821 1000;
BA_ "VFrameFormat" BO_ 821 14;
BA_ "GenMsgILSupport" BO_ 164 1;
BA_ "GenMsgSendType" BO_ 164 0;
BA_ "GenMsgCycleTime" BO_ 164 24;
BA_ "VFrameFormat" BO_ 164 14;
BA_ "GenMsgILSupport" BO_ 453 1;
BA_ "GenMsgSendType" BO_ 453 0;
BA_ "GenMsgCycleTime" BO_ 453 250;
BA_ "VFrameFormat" BO_ 453 14;
BA_ "GenMsgILSupport" BO_ 1310 1;
BA_ "GenMsgSendType" BO_ 1310 0;
BA_ "GenMsgCycleTime" BO_ 1310 1000;
BA_ "VFrameFormat" BO_ 1310 14;
BA_ "GenMsgILSupport" BO_ 252 1;
BA_ "GenMsgSendType" BO_ 252 0;
BA_ "GenMsgCycleTime" BO_ 252 1000;
BA_ "VFrameFormat" BO_ 252 14;
BA_ "GenMsgILSupport" BO_ 1426 1;
BA_ "GenMsgSendType" BO_ 1426 0;
BA_ "GenMsgCycleTime" BO_ 1426 1500;
BA_ "VFrameFormat" BO_ 1426 14;
BA_ "GenMsgILSupport" BO_ 98 1;
BA_ "GenMsgSendType" BO_ 98 0;
BA_ "GenMsgCycleTime" BO_ 98 10;
BA_ "VFrameFormat" BO_ 98 14;
BA_ "GenMsgILSupport" BO_ 458 1;
BA_ "GenMsgSendType" BO_ 458 0;
BA_ "GenMsgCycleTime" BO_ 458 300;
BA_ "VFrameFormat" BO_ 458 14;
BA_ "GenMsgILSupport" BO_ 593 1;
BA_ "GenMsgSendType" BO_ 593 0;
BA_ "GenMsgCycleTime" BO_ 593 1000;
BA_ "VFrameFormat" BO_ 593 14;
BA_ "GenMsgILSupport" BO_ 602 1;
BA_ "GenMsgSendType" BO_ 602 0;
BA_ "GenMsgCycleTime" BO_ 602 1000;
BA_ "VFrameFormat" BO_ 602 14;
BA_ "GenMsgILSupport" BO_ 346 1;
BA_ "GenMsgSendType" BO_ 346 0;
BA_ "GenMsgCycleTime" BO_ 346 100;
BA_ "VFrameFormat" BO_ 346 14;
BA_ "GenMsgILSupport" BO_ 256 1;
BA_ "GenMsgSendType" BO_ 256 0;
BA_ "GenMsgCycleTime" BO_ 256 50;
BA_ "VFrameFormat" BO_ 256 14;
BA_ "GenMsgILSupport" BO_ 434 1;
BA_ "GenMsgSendType" BO_ 434 0;
BA_ "GenMsgCycleTime" BO_ 434 200;
BA_ "VFrameFormat" BO_ 434 14;
BA_ "GenMsgStartDelayTime" BO_ 1015 244;
BA_ "GenMsgILSupport" BO_ 1015 1;
BA_ "GenMsgSendType" BO_ 1015 0;
BA_ "GenMsgCycleTime" BO_ 1015 1000;
BA_ "VFrameFormat" BO_ 1015 14;
BA_ "GenMsgILSupport" BO_ 1587 1;
BA_ "GenMsgSendType" BO_ 1587 0;
BA_ "GenMsgCycleTime" BO_ 1587 1000;
BA_ "VFrameFormat" BO_ 1587 14;
BA_ "GenSigSendType" SG_ 1570 RSRSENFT 3;
BA_ "GenSigSendType" SG_ 1570 SULDCD 3;
BA_ "GenSigSendType" SG_ 1570 PANL 3;
BA_ "GenSigSendType" SG_ 1570 LED_HI_B 3;
BA_ "GenSigSendType" SG_ 1570 DRL 3;
BA_ "GenSigSendType" SG_ 1570 HEDH 3;
BA_ "GenSigSendType" SG_ 1570 HEDL 3;
BA_ "GenSigSendType" SG_ 1570 TAIL 3;
BA_ "GenSigSendType" SG_ 1570 FFOG 3;
BA_ "GenSigSendType" SG_ 1570 RFOG 3;
BA_ "GenSigSendType" SG_ 1570 RSROFFTT 3;
BA_ "GenSigSendType" SG_ 1570 SB_IND 3;
BA_ "GenSigSendType" SG_ 1570 RSRMIDR3 3;
BA_ "GenSigSendType" SG_ 1570 RSRMID_R 3;
BA_ "GenSigSendType" SG_ 1570 RSR_PR 3;
BA_ "GenSigSendType" SG_ 1570 RSRON_ST 3;
BA_ "GenSigSendType" SG_ 1570 LTOFF_AD 3;
BA_ "GenSigSendType" SG_ 1570 RSRSENFC 3;
BA_ "GenSigSendType" SG_ 1570 SRWARN 3;
BA_ "GenSigSendType" SG_ 1570 PWWARN 3;
BA_ "GenSigSendType" SG_ 1570 LTRBZ_R 3;
BA_ "GenSigSendType" SG_ 1571 MRMV_R 3;
BA_ "GenSigSendType" SG_ 1571 RSEL 3;
BA_ "GenSigSendType" SG_ 1571 LSEL 3;
BA_ "GenSigSendType" SG_ 1571 MHR 3;
BA_ "GenSigSendType" SG_ 1571 MHL 3;
BA_ "GenSigSendType" SG_ 1571 MVU 3;
BA_ "GenSigSendType" SG_ 1571 MVD 3;
BA_ "GenSigSendType" SG_ 1571 GCTY 3;
BA_ "GenSigSendType" SG_ 1571 WF 3;
BA_ "GenSigSendType" SG_ 1571 BSTMID_R 3;
BA_ "GenSigSendType" SG_ 1571 PWOP_ADV 3;
BA_ "GenSigSendType" SG_ 896 LSWD 3;
BA_ "GenSigSendType" SG_ 896 LSWP 3;
BA_ "GenSigSendType" SG_ 896 LSWR 3;
BA_ "GenSigSendType" SG_ 896 LSWL 3;
BA_ "GenSigSendType" SG_ 896 LSWB 3;
BA_ "GenSigSendType" SG_ 896 EL_MID 3;
BA_ "GenSigSendType" SG_ 896 LSWT 3;
BA_ "GenSigSendType" SG_ 896 PWDRD 3;
BA_ "GenSigSendType" SG_ 896 PWDRP 3;
BA_ "GenSigSendType" SG_ 896 PWDRR 3;
BA_ "GenSigSendType" SG_ 896 PWDRL 3;
BA_ "GenSigSendType" SG_ 896 EL_BZ 3;
BA_ "GenSigSendType" SG_ 896 PWD_OPE 3;
BA_ "GenSigSendType" SG_ 896 PWP_OPE 3;
BA_ "GenSigSendType" SG_ 896 PWR_OPE 3;
BA_ "GenSigSendType" SG_ 896 PWL_OPE 3;
BA_ "GenSigStartValue" SG_ 1572 DEST_BDB 255;
BA_ "GenSigStartValue" SG_ 1572 C_CODE1 15;
BA_ "GenSigStartValue" SG_ 1572 C_CODE2 15;
BA_ "GenSigStartValue" SG_ 1572 C_CODE3 15;
BA_ "GenSigStartValue" SG_ 1572 STRG_WHL 3;
BA_ "GenSigStartValue" SG_ 1572 DVINF_B 3;
BA_ "GenSigSendType" SG_ 1574 IL_FDOME 3;
BA_ "GenSigSendType" SG_ 1574 IL_LOUNG 3;
BA_ "GenSigSendType" SG_ 1574 IL_OSSTP 3;
BA_ "GenSigSendType" SG_ 1574 AMB_COP 3;
BA_ "GenSigSendType" SG_ 1574 SUPRQ 3;
BA_ "GenSigStartValue" SG_ 1020 SOLAR_R 510;
BA_ "GenSigStartValue" SG_ 1020 SOLAR_L 510;
BA_ "GenSigStartValue" SG_ 1020 N_LX 8190;
BA_ "GenSigSendType" SG_ 774 B_FUNC1 3;
BA_ "GenSigSendType" SG_ 774 B_FUNC2 3;
BA_ "GenSigSendType" SG_ 774 B_FUNC3 3;
BA_ "GenSigSendType" SG_ 774 B_FUNC4 3;
BA_ "GenSigSendType" SG_ 774 B_FUNC5 3;
BA_ "GenSigSendType" SG_ 774 B_FUNC6 3;
BA_ "GenSigSendType" SG_ 774 B_FUNC7 3;
BA_ "GenSigSendType" SG_ 773 B_VRRES 3;
BA_ "GenSigSendType" SG_ 773 OPEINF1 3;
BA_ "GenSigSendType" SG_ 773 OPEINF2 3;
BA_ "GenSigSendType" SG_ 773 OPEINF3 3;
BA_ "GenSigSendType" SG_ 773 OPEINF4 3;
BA_ "GenSigSendType" SG_ 773 OPEINF5 3;
BA_ "GenSigSendType" SG_ 773 OPEINF6 3;
BA_ "GenSigSendType" SG_ 773 OPEINF7 3;
BA_ "GenSigSendType" SG_ 1577 PSUN_D 3;
BA_ "GenSigStartValue" SG_ 1577 PSUN_D 7;
BA_ "GenSigSendType" SG_ 1577 PSLUN_D 3;
BA_ "GenSigStartValue" SG_ 1577 PSLUN_D 7;
BA_ "GenSigSendType" SG_ 1577 PSDEV_D 3;
BA_ "GenSigSendType" SG_ 1578 PSEN 3;
BA_ "GenSigSendType" SG_ 1578 PS_MBR 3;
BA_ "GenSigSendType" SG_ 1578 PSEU 3;
BA_ "GenSigSendType" SG_ 1578 PSER 3;
BA_ "GenSigSendType" SG_ 919 WS_NUM 3;
BA_ "GenSigSendType" SG_ 919 WS_DRVR 3;
BA_ "GenSigSendType" SG_ 919 WS_NEXTD 3;
BA_ "GenSigSendType" SG_ 919 WS_MSG 3;
BA_ "GenSigSendType" SG_ 919 DP_ST 3;
BA_ "GenSigSendType" SG_ 919 NDRV_DET 3;
BA_ "GenSigSendType" SG_ 919 REQ_DPSC 3;
BA_ "GenSigSendType" SG_ 919 PS_NUM 3;
BA_ "GenSigSendType" SG_ 919 PS_DRVR 3;
BA_ "GenSigSendType" SG_ 919 PS_GO_DS 3;
BA_ "GenSigSendType" SG_ 919 PS_GO_PD 3;
BA_ "GenSigSendType" SG_ 919 PS_GO_FR 3;
BA_ "GenSigSendType" SG_ 919 PS_OD 3;
BA_ "GenSigSendType" SG_ 919 PS_GO_KA 3;
BA_ "GenSigSendType" SG_ 919 PS_FRR 3;
BA_ "GenSigSendType" SG_ 919 DKY_EXST 3;
BA_ "GenSigSendType" SG_ 919 PS_N_KEY 3;
BA_ "GenSigSendType" SG_ 919 PS_FRMEM 3;
BA_ "GenSigSendType" SG_ 919 RESEXERS 3;
BA_ "GenSigSendType" SG_ 919 DIDEXERS 3;
BA_ "GenSigSendType" SG_ 919 PS_DKLNK 3;
BA_ "GenSigSendType" SG_ 919 PS_PDHR 3;
BA_ "GenSigSendType" SG_ 919 FRTIME 3;
BA_ "GenSigSendType" SG_ 949 FILB_M 3;
BA_ "GenSigSendType" SG_ 949 ACILB_M 3;
BA_ "GenSigSendType" SG_ 949 RILB_M 3;
BA_ "GenSigSendType" SG_ 949 CEILB_M 3;
BA_ "GenSigSendType" SG_ 949 FTILB_M 3;
BA_ "GenSigSendType" SG_ 949 ILBAR_M 3;
BA_ "GenSigSendType" SG_ 949 ILTHM_M 3;
BA_ "GenSigSendType" SG_ 949 EXILB_M 3;
BA_ "GenSigSendType" SG_ 952 ILCUSA_M 3;
BA_ "GenSigSendType" SG_ 952 WELIL_M 3;
BA_ "GenSigSendType" SG_ 952 DRIIL_M 3;
BA_ "GenSigSendType" SG_ 952 ACIL_M 3;
BA_ "GenSigSendType" SG_ 952 TIMEIL_M 3;
BA_ "GenSigSendType" SG_ 952 ILMAIN_M 3;
BA_ "GenSigSendType" SG_ 952 FNIL_M 3;
BA_ "GenSigSendType" SG_ 952 SEAIL_M 3;
BA_ "GenSigSendType" SG_ 952 ILLON_NO 3;
BA_ "GenSigSendType" SG_ 952 ILLON_F 3;
BA_ "GenSigStartValue" SG_ 786 ODO_BECU 4294967295;
BA_ "GenSigSendType" SG_ 800 B_RACRES 3;
BA_ "GenSigSendType" SG_ 800 B_RACTRG 3;
BA_ "GenSigSendType" SG_ 800 B_DPADD 3;
BA_ "GenSigSendType" SG_ 800 B_DPACTM 3;
BA_ "GenSigSendType" SG_ 800 B_DPACMD 3;
BA_ "GenSigSendType" SG_ 800 B_DPTMP 3;
BA_ "GenSigSendType" SG_ 800 B_DPREFR 3;
BA_ "GenSigSendType" SG_ 800 B_DPBLLV 3;
BA_ "GenSigSendType" SG_ 800 B_DPFDEF 3;
BA_ "GenSigSendType" SG_ 800 B_DPRDEF 3;
BA_ "GenSigSendType" SG_ 800 B_DPSH 3;
BA_ "GenSigSendType" SG_ 800 B_DPFDHV 3;
BA_ "GenSigSendType" SG_ 800 B_DPFPHV 3;
BA_ "GenSigSendType" SG_ 800 B_DPRDHV 3;
BA_ "GenSigSendType" SG_ 800 B_DPRPHV 3;
BA_ "GenSigSendType" SG_ 800 B_DPFGON 3;
BA_ "GenSigSendType" SG_ 800 B_DPFGCH 3;
BA_ "GenSigSendType" SG_ 800 B_DPFGLV 3;
BA_ "GenSigSendType" SG_ 810 B_DPID1 3;
BA_ "GenSigSendType" SG_ 810 B_DPON1 3;
BA_ "GenSigSendType" SG_ 810 B_DPTYP1 3;
BA_ "GenSigSendType" SG_ 810 B_DPDAY1 3;
BA_ "GenSigSendType" SG_ 810 B_DPMON1 3;
BA_ "GenSigSendType" SG_ 810 B_DPDAT1 3;
BA_ "GenSigSendType" SG_ 810 B_DPDTM1 3;
BA_ "GenSigSendType" SG_ 810 B_DPAC1 3;
BA_ "GenSigSendType" SG_ 810 B_DPBC1 3;
BA_ "GenSigSendType" SG_ 810 B_DPID2 3;
BA_ "GenSigSendType" SG_ 810 B_DPON2 3;
BA_ "GenSigSendType" SG_ 810 B_DPTYP2 3;
BA_ "GenSigSendType" SG_ 810 B_DPDAY2 3;
BA_ "GenSigSendType" SG_ 810 B_DPMON2 3;
BA_ "GenSigSendType" SG_ 810 B_DPDAT2 3;
BA_ "GenSigSendType" SG_ 810 B_DPDTM2 3;
BA_ "GenSigSendType" SG_ 810 B_DPAC2 3;
BA_ "GenSigSendType" SG_ 810 B_DPBC2 3;
BA_ "GenSigSendType" SG_ 810 B_DPID3 3;
BA_ "GenSigSendType" SG_ 810 B_DPON3 3;
BA_ "GenSigSendType" SG_ 810 B_DPTYP3 3;
BA_ "GenSigSendType" SG_ 810 B_DPDAY3 3;
BA_ "GenSigSendType" SG_ 810 B_DPMON3 3;
BA_ "GenSigSendType" SG_ 810 B_DPDAT3 3;
BA_ "GenSigSendType" SG_ 810 B_DPDTM3 3;
BA_ "GenSigSendType" SG_ 810 B_DPAC3 3;
BA_ "GenSigSendType" SG_ 810 B_DPBC3 3;
BA_ "GenSigSendType" SG_ 810 B_DPID4 3;
BA_ "GenSigSendType" SG_ 810 B_DPON4 3;
BA_ "GenSigSendType" SG_ 810 B_DPTYP4 3;
BA_ "GenSigSendType" SG_ 810 B_DPDAY4 3;
BA_ "GenSigSendType" SG_ 810 B_DPMON4 3;
BA_ "GenSigSendType" SG_ 810 B_DPDAT4 3;
BA_ "GenSigSendType" SG_ 810 B_DPDTM4 3;
BA_ "GenSigSendType" SG_ 810 B_DPAC4 3;
BA_ "GenSigSendType" SG_ 810 B_DPBC4 3;
BA_ "GenSigSendType" SG_ 810 B_DPID5 3;
BA_ "GenSigSendType" SG_ 810 B_DPON5 3;
BA_ "GenSigSendType" SG_ 810 B_DPTYP5 3;
BA_ "GenSigSendType" SG_ 810 B_DPDAY5 3;
BA_ "GenSigSendType" SG_ 810 B_DPMON5 3;
BA_ "GenSigSendType" SG_ 810 B_DPDAT5 3;
BA_ "GenSigSendType" SG_ 810 B_DPDTM5 3;
BA_ "GenSigSendType" SG_ 810 B_DPAC5 3;
BA_ "GenSigSendType" SG_ 810 B_DPBC5 3;
BA_ "GenSigSendType" SG_ 810 B_DPID6 3;
BA_ "GenSigSendType" SG_ 810 B_DPON6 3;
BA_ "GenSigSendType" SG_ 810 B_DPTYP6 3;
BA_ "GenSigSendType" SG_ 810 B_DPDAY6 3;
BA_ "GenSigSendType" SG_ 810 B_DPMON6 3;
BA_ "GenSigSendType" SG_ 810 B_DPDAT6 3;
BA_ "GenSigSendType" SG_ 810 B_DPDTM6 3;
BA_ "GenSigSendType" SG_ 810 B_DPAC6 3;
BA_ "GenSigSendType" SG_ 810 B_DPBC6 3;
BA_ "GenSigSendType" SG_ 810 B_DPID7 3;
BA_ "GenSigSendType" SG_ 810 B_DPON7 3;
BA_ "GenSigSendType" SG_ 810 B_DPTYP7 3;
BA_ "GenSigSendType" SG_ 810 B_DPDAY7 3;
BA_ "GenSigSendType" SG_ 810 B_DPMON7 3;
BA_ "GenSigSendType" SG_ 810 B_DPDAT7 3;
BA_ "GenSigSendType" SG_ 810 B_DPDTM7 3;
BA_ "GenSigSendType" SG_ 810 B_DPAC7 3;
BA_ "GenSigSendType" SG_ 810 B_DPBC7 3;
BA_ "GenSigSendType" SG_ 810 B_DPTYPN 3;
BA_ "GenSigSendType" SG_ 810 B_DPDAYN 3;
BA_ "GenSigSendType" SG_ 810 B_DPMONN 3;
BA_ "GenSigSendType" SG_ 810 B_DPDATN 3;
BA_ "GenSigSendType" SG_ 810 B_DPDTMN 3;
BA_ "GenSigSendType" SG_ 810 B_DPACN 3;
BA_ "GenSigSendType" SG_ 810 B_DPBCN 3;
BA_ "GenSigSendType" SG_ 810 B_DPACTO 3;
BA_ "GenSigSendType" SG_ 892 THEFTD1 3;
BA_ "GenSigSendType" SG_ 892 THEFTD2 3;
BA_ "GenSigSendType" SG_ 320 MTNLS_L 3;
BA_ "GenSigSendType" SG_ 320 MTNLS_R 3;
BA_ "GenSigSendType" SG_ 466 TVPSOFF 3;
BA_ "GenSigSendType" SG_ 466 APSCJDSA 3;
BA_ "GenSigStartValue" SG_ 328 AXSOC 1023;
BA_ "GenSigSendType" SG_ 823 PS_GO_DD 3;
BA_ "GenSigSendType" SG_ 823 PS_GO_DK 3;
BA_ "GenSigSendType" SG_ 823 FRRSTBDB 3;
BA_ "GenSigSendType" SG_ 823 DISPMODE 3;
BA_ "GenSigSendType" SG_ 823 PS_PD 3;
BA_ "GenSigSendType" SG_ 823 PS_GO_ND 3;
BA_ "GenSigSendType" SG_ 823 MRMAINSW 3;
BA_ "GenSigStartValue" SG_ 823 MRMAINSW 3;
BA_ "GenSigSendType" SG_ 823 MRSOCANS 3;
BA_ "GenSigSendType" SG_ 823 MRSOCMIN 3;
BA_ "GenSigSendType" SG_ 823 MRRUN 3;
BA_ "GenSigSendType" SG_ 823 MREXITF 3;
BA_ "GenSigSendType" SG_ 833 POW_ADV 3;
BA_ "GenSigSendType" SG_ 483 VPSINFO7 3;
BA_ "GenSigSendType" SG_ 483 VPSINFO6 3;
BA_ "GenSigSendType" SG_ 483 VPSINFO5 3;
BA_ "GenSigSendType" SG_ 483 VPSINFO4 3;
BA_ "GenSigSendType" SG_ 483 VPSINFO3 3;
BA_ "GenSigSendType" SG_ 483 VPSINFO2 3;
BA_ "GenSigSendType" SG_ 483 VPSINFO1 3;
BA_ "GenSigStartValue" SG_ 483 VPSINFO1 1;
BA_ "GenSigSendType" SG_ 483 VPSINFOS 3;
BA_ "GenSigSendType" SG_ 483 VPSISOTA 3;
BA_ "GenSigSendType" SG_ 483 APOFRQ 3;
BA_ "GenSigSendType" SG_ 871 PWRSVSET 3;
BA_ "GenSigSendType" SG_ 871 PWRSVSOC 3;
BA_ "GenSigSendType" SG_ 853 PWCRTRT1 3;
BA_ "GenSigSendType" SG_ 853 PWCRTMD1 3;
BA_ "GenSigSendType" SG_ 853 PWCRTID1 3;
BA_ "GenSigSendType" SG_ 856 PWCRTRT2 3;
BA_ "GenSigSendType" SG_ 856 PWCRTMD2 3;
BA_ "GenSigSendType" SG_ 856 PWCRTID2 3;
BA_ "GenSigSendType" SG_ 861 SBCGOTA 3;
BA_ "GenSigSendType" SG_ 861 PWLVOTA 3;
BA_ "GenSigSendType" SG_ 861 PWCRTRT3 3;
BA_ "GenSigSendType" SG_ 861 PWCRTMD3 3;
BA_ "GenSigSendType" SG_ 861 PWCRTID3 3;
BA_ "GenSigSendType" SG_ 861 RDYOF_ST 3;
BA_ "GenSigSendType" SG_ 420 PROTREQ 3;
BA_ "GenSigSendType" SG_ 420 CYCLCREQ 3;
BA_ "GenSigSendType" SG_ 420 DRWUREQ2 3;
BA_ "GenSigSendType" SG_ 420 RMSETREQ 3;
BA_ "GenSigSendType" SG_ 420 STRMREQ 3;
BA_ "GenSigSendType" SG_ 420 STATREQ 3;
BA_ "GenSigSendType" SG_ 863 PAD_EQ2 3;
BA_ "GenSigSendType" SG_ 863 BSET_PAD 3;
BA_ "GenSigSendType" SG_ 863 BSET_PG 3;
BA_ "GenSigSendType" SG_ 863 HLACK 3;
BA_ "GenSigSendType" SG_ 863 DRBDCABN 3;
BA_ "GenSigSendType" SG_ 863 DRGABN 3;
BA_ "GenSigSendType" SG_ 863 DRGOFF 3;
BA_ "GenSigSendType" SG_ 915 BDOACK01 3;
BA_ "GenSigSendType" SG_ 915 BDOACK02 3;
BA_ "GenSigSendType" SG_ 915 BDOACK03 3;
BA_ "GenSigSendType" SG_ 915 BDOACK04 3;
BA_ "GenSigSendType" SG_ 915 BDOACK05 3;
BA_ "GenSigSendType" SG_ 915 BDOACK06 3;
BA_ "GenSigSendType" SG_ 915 BDOACK07 3;
BA_ "GenSigSendType" SG_ 915 BDOACK08 3;
BA_ "GenSigSendType" SG_ 915 BDOACK09 3;
BA_ "GenSigSendType" SG_ 915 BDOACK10 3;
BA_ "GenSigSendType" SG_ 915 BDOACK11 3;
BA_ "GenSigSendType" SG_ 915 BDOACK12 3;
BA_ "GenSigSendType" SG_ 915 BDOACRSV 3;
BA_ "GenSigSendType" SG_ 917 UMASIF01 3;
BA_ "GenSigSendType" SG_ 917 UMASRQ01 3;
BA_ "GenSigSendType" SG_ 917 UMASRV01 3;
BA_ "GenSigSendType" SG_ 917 UMASAD01 3;
BA_ "GenSigSendType" SG_ 918 UMASIF02 3;
BA_ "GenSigSendType" SG_ 918 UMASRQ02 3;
BA_ "GenSigSendType" SG_ 918 UMASRV02 3;
BA_ "GenSigSendType" SG_ 918 UMASAD02 3;
BA_ "GenSigSendType" SG_ 922 UMASIF03 3;
BA_ "GenSigSendType" SG_ 922 UMASRQ03 3;
BA_ "GenSigSendType" SG_ 922 UMASRV03 3;
BA_ "GenSigSendType" SG_ 922 UMASAD03 3;
BA_ "GenSigSendType" SG_ 923 UMASIF04 3;
BA_ "GenSigSendType" SG_ 923 UMASRQ04 3;
BA_ "GenSigSendType" SG_ 923 UMASRV04 3;
BA_ "GenSigSendType" SG_ 923 UMASAD04 3;
BA_ "GenSigSendType" SG_ 925 UMASIF05 3;
BA_ "GenSigSendType" SG_ 925 UMASRQ05 3;
BA_ "GenSigSendType" SG_ 925 UMASRV05 3;
BA_ "GenSigSendType" SG_ 925 UMASAD05 3;
BA_ "GenSigSendType" SG_ 926 UMASIF06 3;
BA_ "GenSigSendType" SG_ 926 UMASRQ06 3;
BA_ "GenSigSendType" SG_ 926 UMASRV06 3;
BA_ "GenSigSendType" SG_ 926 UMASAD06 3;
BA_ "GenSigSendType" SG_ 927 UMASIF07 3;
BA_ "GenSigSendType" SG_ 927 UMASRQ07 3;
BA_ "GenSigSendType" SG_ 927 UMASRV07 3;
BA_ "GenSigSendType" SG_ 927 UMASAD07 3;
BA_ "GenSigSendType" SG_ 933 UMASIF08 3;
BA_ "GenSigSendType" SG_ 933 UMASRQ08 3;
BA_ "GenSigSendType" SG_ 933 UMASRV08 3;
BA_ "GenSigSendType" SG_ 933 UMASAD08 3;
BA_ "GenSigSendType" SG_ 940 UMASIF09 3;
BA_ "GenSigSendType" SG_ 940 UMASRQ09 3;
BA_ "GenSigSendType" SG_ 940 UMASRV09 3;
BA_ "GenSigSendType" SG_ 940 UMASAD09 3;
BA_ "GenSigSendType" SG_ 942 UMASIF10 3;
BA_ "GenSigSendType" SG_ 942 UMASRQ10 3;
BA_ "GenSigSendType" SG_ 942 UMASRV10 3;
BA_ "GenSigSendType" SG_ 942 UMASAD10 3;
BA_ "GenSigSendType" SG_ 946 UMASIF11 3;
BA_ "GenSigSendType" SG_ 946 UMASRQ11 3;
BA_ "GenSigSendType" SG_ 946 UMASRV11 3;
BA_ "GenSigSendType" SG_ 946 UMASAD11 3;
BA_ "GenSigSendType" SG_ 947 UMASIF12 3;
BA_ "GenSigSendType" SG_ 947 UMASRQ12 3;
BA_ "GenSigSendType" SG_ 947 UMASRV12 3;
BA_ "GenSigSendType" SG_ 947 UMASAD12 3;
BA_ "GenSigSendType" SG_ 953 UMRSIF01 3;
BA_ "GenSigSendType" SG_ 953 UMRSRQ01 3;
BA_ "GenSigSendType" SG_ 953 UMRSRV01 3;
BA_ "GenSigSendType" SG_ 953 UMRSAD01 3;
BA_ "GenSigSendType" SG_ 956 UMRSIF02 3;
BA_ "GenSigSendType" SG_ 956 UMRSRQ02 3;
BA_ "GenSigSendType" SG_ 956 UMRSRV02 3;
BA_ "GenSigSendType" SG_ 956 UMRSAD02 3;
BA_ "GenSigSendType" SG_ 966 UMRSIF03 3;
BA_ "GenSigSendType" SG_ 966 UMRSRQ03 3;
BA_ "GenSigSendType" SG_ 966 UMRSRV03 3;
BA_ "GenSigSendType" SG_ 966 UMRSAD03 3;
BA_ "GenSigSendType" SG_ 967 UMRSIF04 3;
BA_ "GenSigSendType" SG_ 967 UMRSRQ04 3;
BA_ "GenSigSendType" SG_ 967 UMRSRV04 3;
BA_ "GenSigSendType" SG_ 967 UMRSAD04 3;
BA_ "GenSigSendType" SG_ 973 UMRSIF05 3;
BA_ "GenSigSendType" SG_ 973 UMRSRQ05 3;
BA_ "GenSigSendType" SG_ 973 UMRSRV05 3;
BA_ "GenSigSendType" SG_ 973 UMRSAD05 3;
BA_ "GenSigSendType" SG_ 979 UMRSIF06 3;
BA_ "GenSigSendType" SG_ 979 UMRSRQ06 3;
BA_ "GenSigSendType" SG_ 979 UMRSRV06 3;
BA_ "GenSigSendType" SG_ 979 UMRSAD06 3;
BA_ "GenSigSendType" SG_ 982 UMRSIF07 3;
BA_ "GenSigSendType" SG_ 982 UMRSRQ07 3;
BA_ "GenSigSendType" SG_ 982 UMRSRV07 3;
BA_ "GenSigSendType" SG_ 982 UMRSAD07 3;
BA_ "GenSigSendType" SG_ 989 UMRSIF08 3;
BA_ "GenSigSendType" SG_ 989 UMRSRQ08 3;
BA_ "GenSigSendType" SG_ 989 UMRSRV08 3;
BA_ "GenSigSendType" SG_ 989 UMRSAD08 3;
BA_ "GenSigSendType" SG_ 993 UMRSIF09 3;
BA_ "GenSigSendType" SG_ 993 UMRSRQ09 3;
BA_ "GenSigSendType" SG_ 993 UMRSRV09 3;
BA_ "GenSigSendType" SG_ 993 UMRSAD09 3;
BA_ "GenSigSendType" SG_ 1003 UMRSIF10 3;
BA_ "GenSigSendType" SG_ 1003 UMRSRQ10 3;
BA_ "GenSigSendType" SG_ 1003 UMRSRV10 3;
BA_ "GenSigSendType" SG_ 1003 UMRSAD10 3;
BA_ "GenSigSendType" SG_ 1007 UMRSIF11 3;
BA_ "GenSigSendType" SG_ 1007 UMRSRQ11 3;
BA_ "GenSigSendType" SG_ 1007 UMRSRV11 3;
BA_ "GenSigSendType" SG_ 1007 UMRSAD11 3;
BA_ "GenSigSendType" SG_ 1013 UMRSIF12 3;
BA_ "GenSigSendType" SG_ 1013 UMRSRQ12 3;
BA_ "GenSigSendType" SG_ 1013 UMRSRV12 3;
BA_ "GenSigSendType" SG_ 1013 UMRSAD12 3;
BA_ "GenSigSendType" SG_ 1059 UMIIFTT 3;
BA_ "GenSigSendType" SG_ 1059 UMIREQTT 3;
BA_ "GenSigSendType" SG_ 1059 UMIRSVTT 3;
BA_ "GenSigSendType" SG_ 1059 UMIDATTT 3;
BA_ "GenSigSendType" SG_ 1065 UMIIFS1 3;
BA_ "GenSigSendType" SG_ 1065 UMIREQS1 3;
BA_ "GenSigSendType" SG_ 1065 UMIRSVS1 3;
BA_ "GenSigSendType" SG_ 1065 UMIDATS1 3;
BA_ "GenSigSendType" SG_ 1072 UMIIFS2 3;
BA_ "GenSigSendType" SG_ 1072 UMIREQS2 3;
BA_ "GenSigSendType" SG_ 1072 UMIRSVS2 3;
BA_ "GenSigSendType" SG_ 1072 UMIDATS2 3;
BA_ "GenSigSendType" SG_ 1152 UMIIFS3 3;
BA_ "GenSigSendType" SG_ 1152 UMIREQS3 3;
BA_ "GenSigSendType" SG_ 1152 UMIRSVS3 3;
BA_ "GenSigSendType" SG_ 1152 UMIDATS3 3;
BA_ "GenSigSendType" SG_ 1156 UMIIFS4 3;
BA_ "GenSigSendType" SG_ 1156 UMIREQS4 3;
BA_ "GenSigSendType" SG_ 1156 UMIRSVS4 3;
BA_ "GenSigSendType" SG_ 1156 UMIDATS4 3;
BA_ "GenSigSendType" SG_ 1169 UMIIFPW 3;
BA_ "GenSigSendType" SG_ 1169 UMIREQPW 3;
BA_ "GenSigSendType" SG_ 1169 UMIRSVPW 3;
BA_ "GenSigSendType" SG_ 1169 UMIDATPW 3;
BA_ "GenSigSendType" SG_ 1175 UMIIFSD 3;
BA_ "GenSigSendType" SG_ 1175 UMIREQSD 3;
BA_ "GenSigSendType" SG_ 1175 UMIRSVSD 3;
BA_ "GenSigSendType" SG_ 1175 UMIDATSD 3;
BA_ "GenSigSendType" SG_ 1318 UMIIFDL 3;
BA_ "GenSigSendType" SG_ 1318 UMIREQDL 3;
BA_ "GenSigSendType" SG_ 1318 UMIRSVDL 3;
BA_ "GenSigSendType" SG_ 1318 UMIDATDL 3;
BA_ "GenSigSendType" SG_ 1323 UMIIFI1 3;
BA_ "GenSigSendType" SG_ 1323 UMIREQI1 3;
BA_ "GenSigSendType" SG_ 1323 UMIRSVI1 3;
BA_ "GenSigSendType" SG_ 1323 UMIDATI1 3;
BA_ "GenSigSendType" SG_ 1324 UMIIFI2 3;
BA_ "GenSigSendType" SG_ 1324 UMIREQI2 3;
BA_ "GenSigSendType" SG_ 1324 UMIRSVI2 3;
BA_ "GenSigSendType" SG_ 1324 UMIDATI2 3;
BA_ "GenSigSendType" SG_ 1328 UMIIFI3 3;
BA_ "GenSigSendType" SG_ 1328 UMIREQI3 3;
BA_ "GenSigSendType" SG_ 1328 UMIRSVI3 3;
BA_ "GenSigSendType" SG_ 1328 UMIDATI3 3;
BA_ "GenSigSendType" SG_ 1329 UMIIFDP 3;
BA_ "GenSigSendType" SG_ 1329 UMIREQDP 3;
BA_ "GenSigSendType" SG_ 1329 UMIRSVDP 3;
BA_ "GenSigSendType" SG_ 1329 UMIDATDP 3;
BA_ "GenSigSendType" SG_ 1332 UMIIFFG 3;
BA_ "GenSigSendType" SG_ 1332 UMIREQFG 3;
BA_ "GenSigSendType" SG_ 1332 UMIRSVFG 3;
BA_ "GenSigSendType" SG_ 1332 UMIDATFG 3;
BA_ "GenSigSendType" SG_ 1333 UMIIFA1 3;
BA_ "GenSigSendType" SG_ 1333 UMIREQA1 3;
BA_ "GenSigSendType" SG_ 1333 UMIRSVA1 3;
BA_ "GenSigSendType" SG_ 1333 UMIDATA1 3;
BA_ "GenSigSendType" SG_ 1335 UMIIFA2 3;
BA_ "GenSigSendType" SG_ 1335 UMIREQA2 3;
BA_ "GenSigSendType" SG_ 1335 UMIRSVA2 3;
BA_ "GenSigSendType" SG_ 1335 UMIDATA2 3;
BA_ "GenSigSendType" SG_ 1336 UMIIFA3 3;
BA_ "GenSigSendType" SG_ 1336 UMIREQA3 3;
BA_ "GenSigSendType" SG_ 1336 UMIRSVA3 3;
BA_ "GenSigSendType" SG_ 1336 UMIDATA3 3;
BA_ "GenSigSendType" SG_ 691 ST1 3;
BA_ "GenSigSendType" SG_ 691 ST1PER 3;
BA_ "GenSigSendType" SG_ 691 ST2 3;
BA_ "GenSigSendType" SG_ 691 ST2PER 3;
BA_ "GenSigSendType" SG_ 691 ST3 3;
BA_ "GenSigSendType" SG_ 691 ST3PER 3;
BA_ "GenSigSendType" SG_ 691 ST4 3;
BA_ "GenSigSendType" SG_ 691 ST4PER 3;
BA_ "GenSigSendType" SG_ 691 ST5 3;
BA_ "GenSigSendType" SG_ 691 ST5PER 3;
BA_ "GenSigSendType" SG_ 691 ST6 3;
BA_ "GenSigSendType" SG_ 691 ST6PER 3;
BA_ "GenSigSendType" SG_ 691 ST7 3;
BA_ "GenSigSendType" SG_ 691 ST7PER 3;
BA_ "GenSigSendType" SG_ 691 ST8 3;
BA_ "GenSigSendType" SG_ 691 ST8PER 3;
BA_ "GenSigSendType" SG_ 691 ST9 3;
BA_ "GenSigSendType" SG_ 691 ST9PER 3;
BA_ "GenSigSendType" SG_ 691 ST10 3;
BA_ "GenSigSendType" SG_ 691 ST10PER 3;
BA_ "GenSigSendType" SG_ 691 ST11 3;
BA_ "GenSigSendType" SG_ 691 ST11PER 3;
BA_ "GenSigSendType" SG_ 691 ST12 3;
BA_ "GenSigSendType" SG_ 691 ST12PER 3;
BA_ "GenSigSendType" SG_ 691 ST13 3;
BA_ "GenSigSendType" SG_ 691 ST13PER 3;
BA_ "GenSigSendType" SG_ 691 ST14 3;
BA_ "GenSigSendType" SG_ 691 ST14PER 3;
BA_ "GenSigSendType" SG_ 691 ST15 3;
BA_ "GenSigSendType" SG_ 691 ST15PER 3;
BA_ "GenSigSendType" SG_ 691 ST16 3;
BA_ "GenSigSendType" SG_ 691 ST16PER 3;
BA_ "GenSigSendType" SG_ 691 ST17 3;
BA_ "GenSigSendType" SG_ 691 ST17PER 3;
BA_ "GenSigSendType" SG_ 691 ST18 3;
BA_ "GenSigSendType" SG_ 691 ST18PER 3;
BA_ "GenSigStartValue" SG_ 1157 VSI_L4B 255;
BA_ "GenSigStartValue" SG_ 1157 VSI_L6K 255;
BA_ "GenSigStartValue" SG_ 1157 VSI_L7E 255;
BA_ "GenSigStartValue" SG_ 1084 VSI_B3N 255;
BA_ "GenSigStartValue" SG_ 1084 VSI_K1B 255;
BA_ "GenSigStartValue" SG_ 1084 VSI_U4C 255;
BA_ "GenSigStartValue" SG_ 1084 VSI_B2B 255;
BA_ "GenSigStartValue" SG_ 1084 VSI_B2C 255;
BA_ "GenSigStartValue" SG_ 1084 VSI_U4Y 255;
BA_ "GenSigStartValue" SG_ 1158 VSI_C7E 255;
BA_ "GenSigStartValue" SG_ 1158 VSI_C7F 255;
BA_ "GenSigStartValue" SG_ 1158 VSI_G4A 255;
BA_ "GenSigStartValue" SG_ 1158 VSI_G4B 255;
BA_ "GenSigStartValue" SG_ 397 HVH_ATPW 1023;
BA_ "GenSigSendType" SG_ 410 ACMODE_P 3;
BA_ "GenSigSendType" SG_ 971 PBD_MAIN 3;
BA_ "GenSigSendType" SG_ 971 LOCK_IF 3;
BA_ "GenSigSendType" SG_ 971 BZ_VOL 3;
BA_ "GenSigSendType" SG_ 971 OPN_POS 3;
BA_ "GenSigSendType" SG_ 971 KICK_CON 3;
BA_ "GenSigSendType" SG_ 971 KICK_FNT 3;
BA_ "GenSigSendType" SG_ 971 KSSCONTL 3;
BA_ "GenSigSendType" SG_ 971 KSSFNTTL 3;
BA_ "GenSigSendType" SG_ 971 BVC_FNT 3;
BA_ "GenSigSendType" SG_ 971 MSC_FNT 3;
BA_ "GenSigSendType" SG_ 971 DOC_FNT 3;
BA_ "GenSigSendType" SG_ 939 PBDPTLFG 3;
BA_ "GenSigSendType" SG_ 939 PBDOPE 3;
BA_ "GenSigSendType" SG_ 939 PBDPOSLV 3;
BA_ "GenSigSendType" SG_ 1014 BSD_STAT 3;
BA_ "GenSigStartValue" SG_ 1014 BSD_STAT 1;
BA_ "GenSigSendType" SG_ 1014 RCTA_DIR 3;
BA_ "GenSigSendType" SG_ 1014 BSD_SW 3;
BA_ "GenSigSendType" SG_ 1014 RCTA_EQ 3;
BA_ "GenSigSendType" SG_ 1014 RCTADISP 3;
BA_ "GenSigSendType" SG_ 1014 RCTA_SW 3;
BA_ "GenSigSendType" SG_ 1014 BSD_BUZ 3;
BA_ "GenSigSendType" SG_ 1014 BSD_ILCR 3;
BA_ "GenSigSendType" SG_ 1014 BSD_ILV 3;
BA_ "GenSigSendType" SG_ 1014 BSD_ITCR 3;
BA_ "GenSigSendType" SG_ 1014 BSD_ITV 3;
BA_ "GenSigStartValue" SG_ 1014 BSD_ITV 2;
BA_ "GenSigSendType" SG_ 1014 FHL_STAT 3;
BA_ "GenSigStartValue" SG_ 1014 FHL_STAT 1;
BA_ "GenSigSendType" SG_ 1014 ADDSTRI2 3;
BA_ "GenSigSendType" SG_ 1014 ADDSTRI1 3;
BA_ "GenSigSendType" SG_ 1014 BSD_TTR 3;
BA_ "GenSigSendType" SG_ 1014 BSD_SWR 3;
BA_ "GenSigSendType" SG_ 1014 RCTA_SWR 3;
BA_ "GenSigSendType" SG_ 1014 FHL_EQ 3;
BA_ "GenSigSendType" SG_ 1014 BSD_SMS 3;
BA_ "GenSigSendType" SG_ 1014 RTAN_ITV 3;
BA_ "GenSigStartValue" SG_ 1014 RTAN_ITV 2;
BA_ "GenSigSendType" SG_ 1014 RTAN_SW 3;
BA_ "GenSigSendType" SG_ 1014 RTANDISM 3;
BA_ "GenSigSendType" SG_ 1014 DOA_BUZ 3;
BA_ "GenSigSendType" SG_ 565 DOA_EQ 3;
BA_ "GenSigSendType" SG_ 565 DOA_STAT 3;
BA_ "GenSigSendType" SG_ 565 DOAM_FR 3;
BA_ "GenSigSendType" SG_ 565 DOAM_FL 3;
BA_ "GenSigSendType" SG_ 565 DOAM_RR 3;
BA_ "GenSigSendType" SG_ 565 DOAM_RL 3;
BA_ "GenSigSendType" SG_ 565 DOAM_TR 3;
BA_ "GenSigSendType" SG_ 565 DOAM_TL 3;
BA_ "GenSigSendType" SG_ 565 DOAM_VEH 3;
BA_ "GenSigSendType" SG_ 565 DOA_ITCR 3;
BA_ "GenSigSendType" SG_ 565 DOA_VORH 3;
BA_ "GenSigSendType" SG_ 565 DOA_VOLH 3;
BA_ "GenSigSendType" SG_ 565 DOA_STVO 3;
BA_ "GenSigSendType" SG_ 565 DOA_SWR 3;
BA_ "GenSigSendType" SG_ 565 DOA_SW 3;
BA_ "GenSigSendType" SG_ 565 DOAM_MSG 3;
BA_ "GenSigSendType" SG_ 565 DOA_ITV 3;
BA_ "GenSigStartValue" SG_ 565 DOA_ITV 2;
BA_ "GenSigSendType" SG_ 565 ADDS_SW 3;
BA_ "GenSigSendType" SG_ 565 DOAVOL_R 3;
BA_ "GenSigSendType" SG_ 565 BSR_STAT 3;
BA_ "GenSigSendType" SG_ 565 BSMDISPR 3;
BA_ "GenSigSendType" SG_ 565 BSMDISPL 3;
BA_ "GenSigSendType" SG_ 687 TBSM_POP 3;
BA_ "GenSigSendType" SG_ 687 TBSMSTAT 3;
BA_ "GenSigSendType" SG_ 687 GRG_EQ 3;
BA_ "GenSigSendType" SG_ 687 OMI_L 3;
BA_ "GenSigSendType" SG_ 687 OMI_R 3;
BA_ "GenSigSendType" SG_ 687 TRA_STT 3;
BA_ "GenSigSendType" SG_ 687 TRLR_EQ 3;
BA_ "GenSigSendType" SG_ 687 TCSL_L 3;
BA_ "GenSigStartValue" SG_ 819 ODO_MET 4294967295;
BA_ "GenSigSendType" SG_ 820 PRMEXE_M 3;
BA_ "GenSigSendType" SG_ 820 REQEXE_M 3;
BA_ "GenSigSendType" SG_ 820 DIDEXE_M 3;
BA_ "GenSigSendType" SG_ 820 DEL_UN_M 3;
BA_ "GenSigSendType" SG_ 820 MREQDP_M 3;
BA_ "GenSigSendType" SG_ 820 MSRDRV_M 3;
BA_ "GenSigSendType" SG_ 820 OPTEXE_M 3;
BA_ "GenSigSendType" SG_ 849 ETHWU_21 3;
BA_ "GenSigSendType" SG_ 849 ETHWU_23 3;
BA_ "GenSigSendType" SG_ 473 HED_S 3;
BA_ "GenSigSendType" SG_ 473 TAL_S 3;
BA_ "GenSigSendType" SG_ 473 DRL_S 3;
BA_ "GenSigSendType" SG_ 473 AUT_S 3;
BA_ "GenSigSendType" SG_ 473 OFF_S 3;
BA_ "GenSigStartValue" SG_ 473 OFF_S 1;
BA_ "GenSigSendType" SG_ 473 AHB_S 3;
BA_ "GenSigSendType" SG_ 473 PAS_S 3;
BA_ "GenSigSendType" SG_ 473 HIB_S 3;
BA_ "GenSigSendType" SG_ 473 BW_S 3;
BA_ "GenSigSendType" SG_ 473 RFG_S 3;
BA_ "GenSigSendType" SG_ 473 FOG_S 3;
BA_ "GenSigSendType" SG_ 473 CRGL_S 3;
BA_ "GenSigSendType" SG_ 473 CRGR_S 3;
BA_ "GenSigSendType" SG_ 473 TRNL_S 3;
BA_ "GenSigSendType" SG_ 473 TRNR_S 3;
BA_ "GenSigSendType" SG_ 473 CXP_TERR 3;
BA_ "GenSigSendType" SG_ 755 WVR_S 3;
BA_ "GenSigSendType" SG_ 755 WSW_S 3;
BA_ "GenSigSendType" SG_ 755 WRSW_S 3;
BA_ "GenSigSendType" SG_ 755 WRON_S 3;
BA_ "GenSigSendType" SG_ 755 WRIN_S 3;
BA_ "GenSigSendType" SG_ 755 WINT_S 3;
BA_ "GenSigSendType" SG_ 755 WMST_S 3;
BA_ "GenSigSendType" SG_ 755 WA_S 3;
BA_ "GenSigSendType" SG_ 755 WHI_S 3;
BA_ "GenSigSendType" SG_ 755 WLO_S 3;
BA_ "GenSigSendType" SG_ 755 WOFF_S 3;
BA_ "GenSigStartValue" SG_ 755 WOFF_S 1;
BA_ "GenSigSendType" SG_ 755 CXP_WERR 3;
BA_ "GenSigSendType" SG_ 1080 VCDSP_1 3;
BA_ "GenSigSendType" SG_ 1080 PCDSP_1 3;
BA_ "GenSigSendType" SG_ 1080 GCDSP_1 3;
BA_ "GenSigSendType" SG_ 847 SNCCNTRQ 3;
BA_ "GenSigSendType" SG_ 847 REQDSPID 3;
BA_ "GenSigSendType" SG_ 847 ST_LCRIM 3;
BA_ "GenSigSendType" SG_ 847 ST_STRIM 3;
BA_ "GenSigSendType" SG_ 840 ETHWU_32 3;
BA_ "GenSigSendType" SG_ 750 NMRBR_MD 3;
BA_ "GenSigSendType" SG_ 471 B_BRKW 3;
BA_ "GenSigSendType" SG_ 471 BRK_MID 3;
BA_ "GenSigSendType" SG_ 471 B_ABS 3;
BA_ "GenSigSendType" SG_ 471 ABS_MID 3;
BA_ "GenSigSendType" SG_ 471 B_EBW 3;
BA_ "GenSigSendType" SG_ 471 EBW_MID 3;
BA_ "GenSigSendType" SG_ 471 B_BRLV 3;
BA_ "GenSigSendType" SG_ 471 TRCOFF 3;
BA_ "GenSigSendType" SG_ 471 TRCCONRL 3;
BA_ "GenSigSendType" SG_ 471 TRCCONRR 3;
BA_ "GenSigSendType" SG_ 471 TRCCONFL 3;
BA_ "GenSigSendType" SG_ 471 TRCCONFR 3;
BA_ "GenSigSendType" SG_ 471 TRC_MID 3;
BA_ "GenSigSendType" SG_ 471 VSCOFF 3;
BA_ "GenSigSendType" SG_ 471 SLP_WL 3;
BA_ "GenSigSendType" SG_ 471 B_ALSD 3;
BA_ "GenSigSendType" SG_ 471 B_DAINDP 3;
BA_ "GenSigSendType" SG_ 471 B_DAINDC 3;
BA_ "GenSigSendType" SG_ 471 B_DAINFO 3;
BA_ "GenSigSendType" SG_ 471 B_OTA 3;
BA_ "GenSigSendType" SG_ 471 OTA_DISP 3;
BA_ "GenSigSendType" SG_ 471 VSCEXPRT 3;
BA_ "GenSigSendType" SG_ 471 EXPTLVL 3;
BA_ "GenSigSendType" SG_ 471 EXPTPLUS 3;
BA_ "GenSigSendType" SG_ 471 B_DACIND 3;
BA_ "GenSigSendType" SG_ 471 DAC_DISP 3;
BA_ "GenSigSendType" SG_ 471 DAC_SETV 3;
BA_ "GenSigSendType" SG_ 471 CRAWLIND 3;
BA_ "GenSigSendType" SG_ 471 CRAWLMID 3;
BA_ "GenSigSendType" SG_ 471 CRAWLSPD 3;
BA_ "GenSigSendType" SG_ 471 DDRTWV 3;
BA_ "GenSigSendType" SG_ 471 B_BUZZER 3;
BA_ "GenSigSendType" SG_ 471 B_PKBLP 3;
BA_ "GenSigSendType" SG_ 471 B_EPBWL 3;
BA_ "GenSigSendType" SG_ 471 B_EPBMID 3;
BA_ "GenSigSendType" SG_ 471 MCBW 3;
BA_ "GenSigSendType" SG_ 471 CRLSPD2 3;
BA_ "GenSigSendType" SG_ 471 CRLAOFF 3;
BA_ "GenSigSendType" SG_ 471 CRLSRINF 3;
BA_ "GenSigSendType" SG_ 730 POSIREQ 3;
BA_ "GenSigSendType" SG_ 730 POSIREQ2 3;
BA_ "GenSigSendType" SG_ 730 A_DMODEA 3;
BA_ "GenSigSendType" SG_ 730 B_DCMDA3 3;
BA_ "GenSigSendType" SG_ 741 GRLGDBCR 3;
BA_ "GenSigSendType" SG_ 741 DMCNVINF 3;
BA_ "GenSigSendType" SG_ 290 FR_DISP 3;
BA_ "GenSigSendType" SG_ 1063 R1_MD_SW 3;
BA_ "GenSigSendType" SG_ 1063 R2_MD_SW 3;
BA_ "GenSigSendType" SG_ 1063 R3_MD_SW 3;
BA_ "GenSigSendType" SG_ 1063 R4_MD_SW 3;
BA_ "GenSigSendType" SG_ 1063 R5_MD_SW 3;
BA_ "GenSigSendType" SG_ 1063 R6_MD_SW 3;
BA_ "GenSigSendType" SG_ 1063 R7_MD_SW 3;
BA_ "GenSigSendType" SG_ 1063 R8_MD_SW 3;
BA_ "GenSigSendType" SG_ 1063 R9_MD_SW 3;
BA_ "GenSigSendType" SG_ 1063 R10_MDSW 3;
BA_ "GenSigSendType" SG_ 1063 R11_MDSW 3;
BA_ "GenSigSendType" SG_ 1063 R12_MDSW 3;
BA_ "GenSigSendType" SG_ 1063 R13_MDSW 3;
BA_ "GenSigSendType" SG_ 1063 R14_MDSW 3;
BA_ "GenSigSendType" SG_ 1063 R15_MDSW 3;
BA_ "GenSigSendType" SG_ 1063 R16_MDSW 3;
BA_ "GenSigSendType" SG_ 1063 R17_MDSW 3;
BA_ "GenSigSendType" SG_ 1063 R18_MDSW 3;
BA_ "GenSigSendType" SG_ 1063 R19_MDSW 3;
BA_ "GenSigSendType" SG_ 1063 R20_MDSW 3;
BA_ "GenSigSendType" SG_ 1063 R21_MDSW 3;
BA_ "GenSigSendType" SG_ 1063 R22_MDSW 3;
BA_ "GenSigSendType" SG_ 1063 R23_MDSW 3;
BA_ "GenSigSendType" SG_ 1063 R24_MDSW 3;
BA_ "GenSigSendType" SG_ 1063 TW_MD_SW 3;
BA_ "GenSigSendType" SG_ 1063 CH_MD_SW 3;
BA_ "GenSigSendType" SG_ 1063 P1_MD_SW 3;
BA_ "GenSigSendType" SG_ 1063 RG_MD_SW 3;
BA_ "GenSigSendType" SG_ 1063 CF_MD_SW 3;
BA_ "GenSigSendType" SG_ 1063 PW_MD_SW 3;
BA_ "GenSigSendType" SG_ 1063 SN_MD_SW 3;
BA_ "GenSigSendType" SG_ 1063 SP_MD_SW 3;
BA_ "GenSigSendType" SG_ 1063 EC_MD_SW 3;
BA_ "GenSigSendType" SG_ 1063 NR_MD_SW 3;
BA_ "GenSigSendType" SG_ 1063 CS_MD_SW 3;
BA_ "GenSigSendType" SG_ 1063 ECORC_SW 3;
BA_ "GenSigSendType" SG_ 1063 SS_MD_SW 3;
BA_ "GenSigSendType" SG_ 958 LPSDWARN 3;
BA_ "GenSigSendType" SG_ 943 RPSDWARN 3;
BA_ "GenSigSendType" SG_ 791 LCANGBZ 3;
BA_ "GenSigSendType" SG_ 791 LCAVCBZ 3;
BA_ "GenSigSendType" SG_ 791 LCSRQBZ 3;
BA_ "GenSigSendType" SG_ 791 LCSONSD 3;
BA_ "GenSigSendType" SG_ 791 LCSEXIST 3;
BA_ "GenSigSendType" SG_ 791 LCATRAJE 3;
BA_ "GenSigSendType" SG_ 791 LCSLWNGD 3;
BA_ "GenSigSendType" SG_ 791 LCSARRLD 3;
BA_ "GenSigSendType" SG_ 791 LCSARRRD 3;
BA_ "GenSigSendType" SG_ 791 LCSRWNGD 3;
BA_ "GenSigSendType" SG_ 791 LTCLCSD 3;
BA_ "GenSigSendType" SG_ 791 DM_DISPM 3;
BA_ "GenSigSendType" SG_ 791 DM_BZR 3;
BA_ "GenSigSendType" SG_ 791 LCASGEST 3;
BA_ "GenSigSendType" SG_ 791 LCASGMCS 3;
BA_ "GenSigSendType" SG_ 791 LCAMSG 3;
BA_ "GenSigSendType" SG_ 791 LCASGIND 3;
BA_ "GenSigSendType" SG_ 1544 CTAMBG 3;
BA_ "GenSigSendType" SG_ 1544 CTAMIDCR 3;
BA_ "GenSigSendType" SG_ 1544 CTAMIDCL 3;
BA_ "GenSigSendType" SG_ 1544 CTAMIDCA 3;
BA_ "GenSigSendType" SG_ 1544 CTAOFFS 3;
BA_ "GenSigSendType" SG_ 1544 CTAWDS 3;
BA_ "GenSigSendType" SG_ 1544 CTABUZF 3;
BA_ "GenSigSendType" SG_ 1544 CTAHR 3;
BA_ "GenSigSendType" SG_ 1544 CTAHL 3;
BA_ "GenSigSendType" SG_ 1041 PCSINDI 3;
BA_ "GenSigSendType" SG_ 1041 PCSWM 3;
BA_ "GenSigSendType" SG_ 1041 PCSEXIST 3;
BA_ "GenSigSendType" SG_ 1041 PCSWDUCT 3;
BA_ "GenSigSendType" SG_ 1041 RTWOFFS 3;
BA_ "GenSigSendType" SG_ 1041 PCSMTBZ2 3;
BA_ "GenSigSendType" SG_ 1041 PCSOFFS 3;
BA_ "GenSigSendType" SG_ 1041 FSSINFO 3;
BA_ "GenSigSendType" SG_ 1041 PCSRTWM 3;
BA_ "GenSigSendType" SG_ 1041 PCSSWM 3;
BA_ "GenSigSendType" SG_ 1042 LDAINDI 3;
BA_ "GenSigSendType" SG_ 1042 LTAINDI 3;
BA_ "GenSigSendType" SG_ 1042 LDAMSG 3;
BA_ "GenSigSendType" SG_ 1042 LTAMSG 3;
BA_ "GenSigSendType" SG_ 1042 CSFBUZ 3;
BA_ "GenSigSendType" SG_ 1042 LDWBUZ 3;
BA_ "GenSigSendType" SG_ 1042 LKACB 3;
BA_ "GenSigSendType" SG_ 1042 SWSBUZ 3;
BA_ "GenSigSendType" SG_ 1042 LKAWLSL 3;
BA_ "GenSigSendType" SG_ 1042 LKAWLSR 3;
BA_ "GenSigSendType" SG_ 1042 SWSRAD 3;
BA_ "GenSigSendType" SG_ 1042 LKAWTCS 3;
BA_ "GenSigSendType" SG_ 1042 SWSSWD 3;
BA_ "GenSigSendType" SG_ 1042 LDACS 3;
BA_ "GenSigSendType" SG_ 1042 LDACD 3;
BA_ "GenSigSendType" SG_ 1042 LTABZR 3;
BA_ "GenSigSendType" SG_ 1042 LDAAMEX 3;
BA_ "GenSigSendType" SG_ 1042 LDAAMST 3;
BA_ "GenSigSendType" SG_ 1042 VSDGCONT 3;
BA_ "GenSigSendType" SG_ 1042 VSDGONST 3;
BA_ "GenSigSendType" SG_ 1042 VUSMONST 3;
BA_ "GenSigSendType" SG_ 1008 D_RF_ST 3;
BA_ "GenSigSendType" SG_ 1008 D_RF_LV 3;
BA_ "GenSigSendType" SG_ 1008 D_STM2 3;
BA_ "GenSigSendType" SG_ 1008 D_STM1 3;
BA_ "GenSigSendType" SG_ 1008 SCD2 3;
BA_ "GenSigSendType" SG_ 1008 D_WALKIN 3;
BA_ "GenSigSendType" SG_ 1008 RST_OPAT 3;
BA_ "GenSigSendType" SG_ 1008 D_SLDPOS 3;
BA_ "GenSigStartValue" SG_ 1008 D_SLDPOS 1023;
BA_ "GenSigSendType" SG_ 1008 D_RCLPOS 3;
BA_ "GenSigStartValue" SG_ 1008 D_RCLPOS 255;
BA_ "GenSigSendType" SG_ 1008 D_LIFPOS 3;
BA_ "GenSigStartValue" SG_ 1008 D_LIFPOS 255;
BA_ "GenSigSendType" SG_ 959 B_P 3;
BA_ "GenSigSendType" SG_ 959 B_R 3;
BA_ "GenSigSendType" SG_ 959 B_N 3;
BA_ "GenSigSendType" SG_ 959 B_D 3;
BA_ "GenSigSendType" SG_ 959 B_B 3;
BA_ "GenSigSendType" SG_ 959 XFSFT 3;
BA_ "GenSigSendType" SG_ 959 SFTOUT 3;
BA_ "GenSigSendType" SG_ 959 ACT 3;
BA_ "GenSigSendType" SG_ 959 IGP_PT2 3;
BA_ "GenSigSendType" SG_ 1025 DRDYSTS 3;
BA_ "GenSigSendType" SG_ 1025 DRDYB 3;
BA_ "GenSigStartValue" SG_ 444 STRGCM 128;
BA_ "GenSigSendType" SG_ 1071 HVIND 3;
BA_ "GenSigSendType" SG_ 1071 HVMALPAT 3;
BA_ "GenSigSendType" SG_ 1071 HVBUZZ 3;
BA_ "GenSigSendType" SG_ 1071 HV4WNG 3;
BA_ "GenSigSendType" SG_ 1071 RMMPOPUP 3;
BA_ "GenSigSendType" SG_ 1071 BRKOTID 3;
BA_ "GenSigSendType" SG_ 1071 PWRLMID 3;
BA_ "GenSigSendType" SG_ 1071 RBKLM 3;
BA_ "GenSigSendType" SG_ 805 INS_UPD 3;
BA_ "GenSigSendType" SG_ 805 SOCINDLL 3;
BA_ "GenSigSendType" SG_ 805 CNGPIEVD 3;
BA_ "GenSigSendType" SG_ 950 NDBW 3;
BA_ "GenSigSendType" SG_ 950 SOC_MON 3;
BA_ "GenSigSendType" SG_ 950 CMH4 3;
BA_ "GenSigSendType" SG_ 950 CMH3 3;
BA_ "GenSigSendType" SG_ 950 CMH2 3;
BA_ "GenSigSendType" SG_ 950 CHMH 3;
BA_ "GenSigSendType" SG_ 950 RNRG 3;
BA_ "GenSigSendType" SG_ 1057 HVEWUPST 3;
BA_ "GenSigSendType" SG_ 1057 NACCON 3;
BA_ "GenSigSendType" SG_ 1057 PICAU 3;
BA_ "GenSigSendType" SG_ 1057 HVCAU 3;
BA_ "GenSigSendType" SG_ 1057 TOWW 3;
BA_ "GenSigSendType" SG_ 1057 ACCHCAU 3;
BA_ "GenSigSendType" SG_ 1057 VSP_MSG 3;
BA_ "GenSigSendType" SG_ 1035 BPRQSWDP 3;
BA_ "GenSigSendType" SG_ 1035 BPENBL 3;
BA_ "GenSigSendType" SG_ 1035 BPNAVIDP 3;
BA_ "GenSigSendType" SG_ 506 RNEC_MON 3;
BA_ "GenSigSendType" SG_ 1067 ACINVSSW 3;
BA_ "GenSigSendType" SG_ 1067 ACINVACT 3;
BA_ "GenSigStartValue" SG_ 453 VARENG1 15;
BA_ "GenSigStartValue" SG_ 453 VARENG2 15;
BA_ "GenSigStartValue" SG_ 453 VARENG3 15;
BA_ "GenSigStartValue" SG_ 453 VARENG4 1;
BA_ "GenSigStartValue" SG_ 453 DVINF 3;
BA_ "GenSigStartValue" SG_ 453 VARTRM1 15;
BA_ "GenSigSendType" SG_ 1310 RDYIND 3;
BA_ "GenSigSendType" SG_ 1310 B_ISNW 3;
BA_ "GenSigSendType" SG_ 1310 B_DMODE 3;
BA_ "GenSigSendType" SG_ 1310 FSITRG 3;
BA_ "GenSigSendType" SG_ 1310 B_OMODE 3;
BA_ "GenSigSendType" SG_ 1310 FSIKIND 3;
BA_ "GenSigSendType" SG_ 1310 FSILSTTP 3;
BA_ "GenSigSendType" SG_ 1310 B_DMODE2 3;
BA_ "GenSigSendType" SG_ 1310 B_DMSINF 3;
BA_ "GenSigSendType" SG_ 1310 B_DMSIF2 3;
BA_ "GenSigSendType" SG_ 1310 B_TMODE 3;
BA_ "GenSigSendType" SG_ 1310 TOW_DISP 3;
BA_ "GenSigSendType" SG_ 1310 B_PDL1 3;
BA_ "GenSigSendType" SG_ 1310 MDSLTACT 3;
BA_ "GenSigSendType" SG_ 1310 B_DMINF2 3;
BA_ "GenSigSendType" SG_ 252 B_STPE 3;
BA_ "GenSigSendType" SG_ 252 CHAW_BZR 3;
BA_ "GenSigSendType" SG_ 252 CHAWID 3;
BA_ "GenSigSendType" SG_ 252 BOSLAMP 3;
BA_ "GenSigSendType" SG_ 252 BOSMINF 3;
BA_ "GenSigSendType" SG_ 252 GOSMINF 3;
BA_ "GenSigSendType" SG_ 252 MSG_SFML 3;
BA_ "GenSigSendType" SG_ 252 BZR_PT 3;
BA_ "GenSigStartValue" SG_ 1426 VIN_1 63;
BA_ "GenSigStartValue" SG_ 1426 VIN_2 63;
BA_ "GenSigStartValue" SG_ 1426 VIN_3 63;
BA_ "GenSigStartValue" SG_ 1426 VIN_4 63;
BA_ "GenSigStartValue" SG_ 1426 VIN_5 63;
BA_ "GenSigStartValue" SG_ 1426 VIN_6 63;
BA_ "GenSigStartValue" SG_ 1426 VIN_7 63;
BA_ "GenSigStartValue" SG_ 1426 VIN_8 63;
BA_ "GenSigStartValue" SG_ 1426 VIN_9 63;
BA_ "GenSigStartValue" SG_ 1426 VIN_10 63;
BA_ "GenSigStartValue" SG_ 1426 VIN_11 63;
BA_ "GenSigStartValue" SG_ 1426 VIN_12 63;
BA_ "GenSigStartValue" SG_ 1426 VIN_13 63;
BA_ "GenSigStartValue" SG_ 1426 VIN_14 63;
BA_ "GenSigStartValue" SG_ 1426 VIN_15 63;
BA_ "GenSigStartValue" SG_ 1426 VIN_16 63;
BA_ "GenSigStartValue" SG_ 1426 VIN_17 63;
BA_ "GenSigStartValue" SG_ 98 PANGINV 1;
BA_ "GenSigStartValue" SG_ 98 EPSSATGF 1;
BA_ "GenSigStartValue" SG_ 98 SANGINV 1;
BA_ "GenSigSendType" SG_ 458 EPS_BZER 3;
BA_ "GenSigSendType" SG_ 458 EPS_WLMP 3;
BA_ "GenSigSendType" SG_ 458 EPS_MINF 3;
BA_ "GenSigSendType" SG_ 458 EPS_REMT 3;
BA_ "GenSigSendType" SG_ 593 ACCEX 3;
BA_ "GenSigSendType" SG_ 593 ACCID 3;
BA_ "GenSigSendType" SG_ 593 ACCCCSID 3;
BA_ "GenSigSendType" SG_ 593 ISAID 3;
BA_ "GenSigSendType" SG_ 593 ISALIMID 3;
BA_ "GenSigSendType" SG_ 593 ACCSPU 3;
BA_ "GenSigSendType" SG_ 593 ACCSPEXC 3;
BA_ "GenSigSendType" SG_ 593 ACCSP 3;
BA_ "GenSigSendType" SG_ 593 ACCSPST1 3;
BA_ "GenSigSendType" SG_ 593 ACCSUST1 3;
BA_ "GenSigSendType" SG_ 593 ERMMAXID 3;
BA_ "GenSigSendType" SG_ 593 ACCDST 3;
BA_ "GenSigSendType" SG_ 593 ACCDTST1 3;
BA_ "GenSigSendType" SG_ 593 ACCDTST2 3;
BA_ "GenSigSendType" SG_ 593 ERMID 3;
BA_ "GenSigSendType" SG_ 593 MODEEX 3;
BA_ "GenSigSendType" SG_ 602 OTHAHCON 3;
BA_ "GenSigSendType" SG_ 602 OTHINCON 3;
BA_ "GenSigSendType" SG_ 602 SRP_PRE 3;
BA_ "GenSigSendType" SG_ 602 SRP_IND 3;
BA_ "GenSigSendType" SG_ 602 AHSSWVST 3;
BA_ "GenSigSendType" SG_ 602 AHSSWVEX 3;
BA_ "GenSigSendType" SG_ 602 AHSSDEST 3;
BA_ "GenSigStartValue" SG_ 602 AHSSDEST 3;
BA_ "GenSigSendType" SG_ 602 AHSSDEEX 3;
BA_ "GenSigSendType" SG_ 602 A_LMP_ST 3;
BA_ "GenSigSendType" SG_ 602 A_HLLI 3;
BA_ "GenSigSendType" SG_ 602 A_BW_IND 3;
BA_ "GenSigSendType" SG_ 602 A_BW_PRE 3;
BA_ "GenSigSendType" SG_ 602 AH_IND_S 3;
BA_ "GenSigSendType" SG_ 602 AHSACTST 3;
BA_ "GenSigSendType" SG_ 602 AHSACTEX 3;
BA_ "GenSigSendType" SG_ 602 AHBACTST 3;
BA_ "GenSigSendType" SG_ 602 AHBACTEX 3;
BA_ "GenSigStartValue" SG_ 346 OTHFRILL 1048574;
BA_ "GenSigStartValue" SG_ 256 OTHSOR 254;
BA_ "GenSigStartValue" SG_ 256 OTHROR 254;
BA_ "GenSigStartValue" SG_ 256 OTHLX 65534;
BA_ "GenSigStartValue" SG_ 256 OTHSOLAR 65534;
BA_ "GenSigSendType" SG_ 434 XREQFPB 3;
BA_ "GenSigSendType" SG_ 434 XREQPB 3;
BA_ "GenSigSendType" SG_ 434 XREQPBH 3;
BA_ "GenSigSendType" SG_ 1015 HUD_ST 3;
BA_ "GenSigSendType" SG_ 1587 BZDN3 3;
BA_ "GenSigSendType" SG_ 1587 BZDN2 3;
BA_ "GenSigSendType" SG_ 1587 BZDN 3;
BA_ "GenSigSendType" SG_ 1587 NSPB 3;
BA_ "GenSigSendType" SG_ 1587 D_SWR1 3;
BA_ "GenSigSendType" SG_ 1587 SWR3 3;
BA_ "GenSigSendType" SG_ 1587 SWR2 3;
BA_ "GenSigSendType" SG_ 1587 SWR1 3;
